// *************************************************************************** *
// *                                                                           *
// * Description:         CANDB File                                           *
// * Generated at:        2025-01-24 12:56                                     *
// * System:              SDB22436                                             *
// * Variant:             L946_ADCU9_ZCUDM                                     *
// * Network:             BodyExposedCAN                                       *
// *                                                                           *
// *************************************************************************** *
VERSION "BodyExposedCAN"

NS_ :

BS_ :

BU_ :  ETC HCML HCMR ZCUD

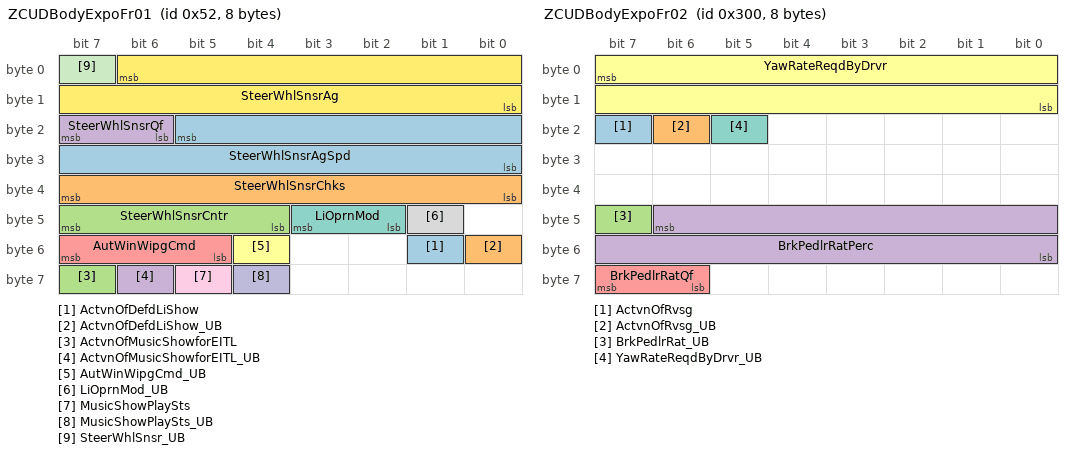
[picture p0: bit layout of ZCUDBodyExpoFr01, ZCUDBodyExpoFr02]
BO_ 82 ZCUDBodyExpoFr01 : 8 ZCUD
 SG_ ActvnOfDefdLiShow : 49|1@0+ (1,0) [0|1] "" HCML,HCMR
 SG_ ActvnOfDefdLiShow_UB : 48|1@0+ (1,0) [0|1] "" HCML,HCMR
 SG_ ActvnOfMusicShowforEITL : 63|1@0+ (1,0) [0|1] "" HCML,HCMR
 SG_ ActvnOfMusicShowforEITL_UB : 62|1@0+ (1,0) [0|1] "" HCML,HCMR
 SG_ AutWinWipgCmd : 55|3@0+ (1,0) [0|7] "" HCML,HCMR
 SG_ AutWinWipgCmd_UB : 52|1@0+ (1,0) [0|1] "" HCML,HCMR
 SG_ LiOprnMod : 43|2@0+ (1,0) [0|3] "" ETC,HCML,HCMR
 SG_ LiOprnMod_UB : 41|1@0+ (1,0) [0|1] "" ETC,HCML,HCMR
 SG_ MusicShowPlaySts : 61|1@0+ (1,0) [0|1] "" HCML,HCMR
 SG_ MusicShowPlaySts_UB : 60|1@0+ (1,0) [0|1] "" HCML,HCMR
 SG_ SteerWhlSnsr_UB : 7|1@0+ (1,0) [0|1] "" HCML,HCMR
 SG_ SteerWhlSnsrAg : 6|15@0- (0.0009765625,0.0) [-14.5|14.5] "rad" HCML,HCMR
 SG_ SteerWhlSnsrAgSpd : 21|14@0- (0.0078125,0.0) [-50.0|50.0] "rad/s" HCML,HCMR
 SG_ SteerWhlSnsrChks : 39|8@0+ (1.0,0.0) [0.0|255.0] "Unitless" HCML,HCMR
 SG_ SteerWhlSnsrCntr : 47|4@0+ (1.0,0.0) [0.0|15.0] "Unitless" HCML,HCMR
 SG_ SteerWhlSnsrQf : 23|2@0+ (1,0) [0|3] "" HCML,HCMR

BO_ 768 ZCUDBodyExpoFr02 : 8 ZCUD
 SG_ ActvnOfRvsg : 23|1@0+ (1,0) [0|1] "" Vector__XXX
 SG_ ActvnOfRvsg_UB : 22|1@0+ (1,0) [0|1] "" Vector__XXX
 SG_ BrkPedlrRat_UB : 47|1@0+ (1,0) [0|1] "" HCML,HCMR
 SG_ BrkPedlrRatPerc : 46|15@0+ (0.00390625,0.0) [0.0|100.0] "%" HCML,HCMR
 SG_ BrkPedlrRatQf : 63|2@0+ (1,0) [0|3] "" HCML,HCMR
 SG_ YawRateReqdByDrvr : 7|16@0- (0.000244140625,0.0) [-5.0|5.0] "rad/s" HCML,HCMR
 SG_ YawRateReqdByDrvr_UB : 21|1@0+ (1,0) [0|1] "" HCML,HCMR

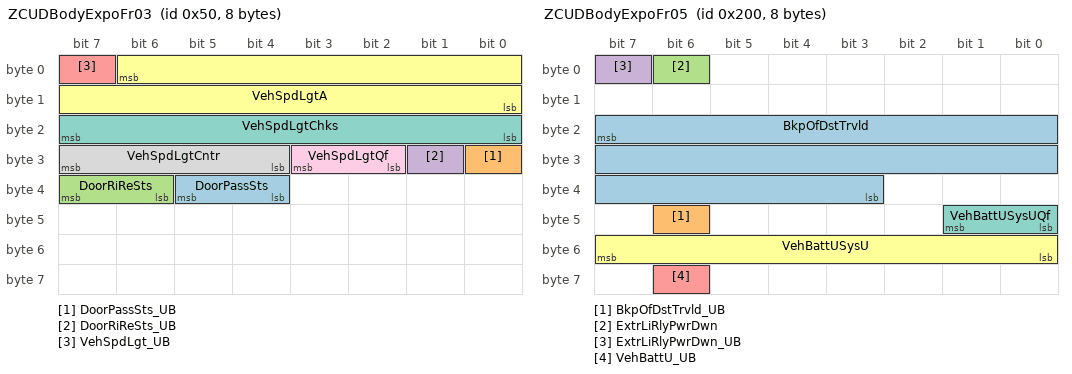
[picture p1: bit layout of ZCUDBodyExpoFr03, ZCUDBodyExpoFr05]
BO_ 80 ZCUDBodyExpoFr03 : 8 ZCUD
 SG_ DoorPassSts : 37|2@0+ (1,0) [0|3] "" Vector__XXX
 SG_ DoorPassSts_UB : 24|1@0+ (1,0) [0|1] "" Vector__XXX
 SG_ DoorRiReSts : 39|2@0+ (1,0) [0|3] "" Vector__XXX
 SG_ DoorRiReSts_UB : 25|1@0+ (1,0) [0|1] "" Vector__XXX
 SG_ VehSpdLgt_UB : 7|1@0+ (1,0) [0|1] "" HCML,HCMR
 SG_ VehSpdLgtA : 6|15@0+ (0.00391,0.0) [0.0|125.0027] "m/s" HCML,HCMR
 SG_ VehSpdLgtChks : 23|8@0+ (1.0,0.0) [0.0|255.0] "Unitless" HCML,HCMR
 SG_ VehSpdLgtCntr : 31|4@0+ (1.0,0.0) [0.0|15.0] "Unitless" HCML,HCMR
 SG_ VehSpdLgtQf : 27|2@0+ (1,0) [0|3] "" HCML,HCMR

BO_ 384 ZCUDBodyExpoFr04 : 8 ZCUD
 SG_ VehCfgPrmBlkIDBytePosn1 : 7|8@0+ (1.0,0.0) [0.0|255.0] "Unitless" HCML,HCMR
 SG_ VehCfgPrmCCPBytePosn2 : 15|8@0+ (1.0,0.0) [0.0|255.0] "Unitless" HCML,HCMR
 SG_ VehCfgPrmCCPBytePosn3 : 23|8@0+ (1.0,0.0) [0.0|255.0] "Unitless" HCML,HCMR
 SG_ VehCfgPrmCCPBytePosn4 : 31|8@0+ (1.0,0.0) [0.0|255.0] "Unitless" HCML,HCMR
 SG_ VehCfgPrmCCPBytePosn5 : 39|8@0+ (1.0,0.0) [0.0|255.0] "Unitless" HCML,HCMR
 SG_ VehCfgPrmCCPBytePosn6 : 47|8@0+ (1.0,0.0) [0.0|255.0] "Unitless" HCML,HCMR
 SG_ VehCfgPrmCCPBytePosn7 : 55|8@0+ (1.0,0.0) [0.0|255.0] "Unitless" HCML,HCMR
 SG_ VehCfgPrmCCPBytePosn8 : 63|8@0+ (1.0,0.0) [0.0|255.0] "Unitless" HCML,HCMR

BO_ 512 ZCUDBodyExpoFr05 : 8 ZCUD
 SG_ BkpOfDstTrvld : 23|21@0+ (1.0,0.0) [0.0|2000000.0] "km" HCML,HCMR
 SG_ BkpOfDstTrvld_UB : 46|1@0+ (1,0) [0|1] "" HCML,HCMR
 SG_ ExtrLiRlyPwrDwn : 6|1@0+ (1,0) [0|1] "" HCML,HCMR
 SG_ ExtrLiRlyPwrDwn_UB : 7|1@0+ (1,0) [0|1] "" HCML,HCMR
 SG_ VehBattU_UB : 62|1@0+ (1,0) [0|1] "" HCML,HCMR
 SG_ VehBattUSysU : 55|8@0+ (0.1,0.0) [0.0|25.0] "Volt" HCML,HCMR
 SG_ VehBattUSysUQf : 41|2@0+ (1,0) [0|3] "" HCML,HCMR

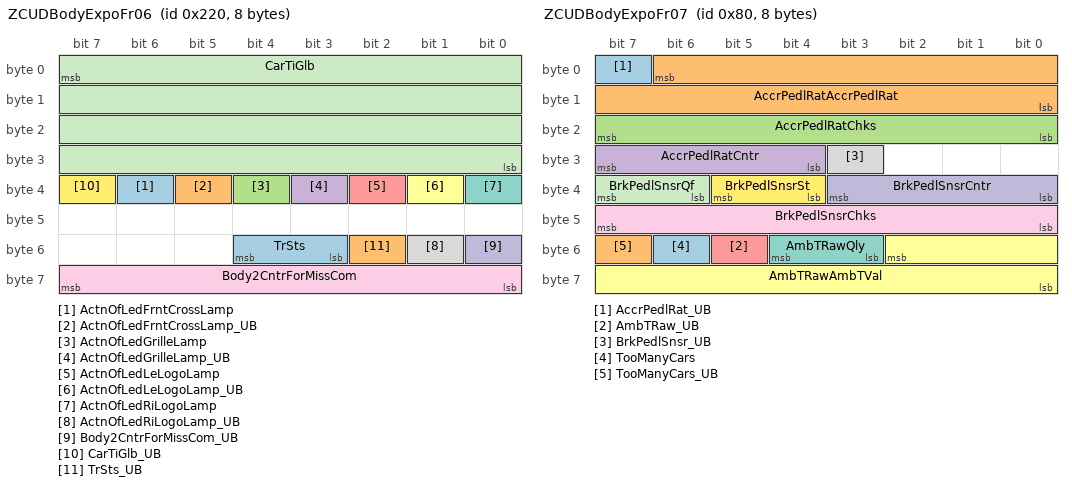
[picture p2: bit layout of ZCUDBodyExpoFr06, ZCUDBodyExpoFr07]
BO_ 544 ZCUDBodyExpoFr06 : 8 ZCUD
 SG_ ActnOfLedFrntCrossLamp : 38|1@0+ (1,0) [0|1] "" HCML,HCMR
 SG_ ActnOfLedFrntCrossLamp_UB : 37|1@0+ (1,0) [0|1] "" HCML,HCMR
 SG_ ActnOfLedGrilleLamp : 36|1@0+ (1,0) [0|1] "" HCML,HCMR
 SG_ ActnOfLedGrilleLamp_UB : 35|1@0+ (1,0) [0|1] "" HCML,HCMR
 SG_ ActnOfLedLeLogoLamp : 34|1@0+ (1,0) [0|1] "" HCML
 SG_ ActnOfLedLeLogoLamp_UB : 33|1@0+ (1,0) [0|1] "" HCML
 SG_ ActnOfLedRiLogoLamp : 32|1@0+ (1,0) [0|1] "" HCMR
 SG_ ActnOfLedRiLogoLamp_UB : 49|1@0+ (1,0) [0|1] "" HCMR
 SG_ Body2CntrForMissCom : 63|8@0+ (1.0,0.0) [0.0|255.0] "Unitless" HCML,HCMR
 SG_ Body2CntrForMissCom_UB : 48|1@0+ (1,0) [0|1] "" HCML,HCMR
 SG_ CarTiGlb : 7|32@0+ (0.1,0.0) [0.0|429496729.5] "s" HCML,HCMR
 SG_ CarTiGlb_UB : 39|1@0+ (1,0) [0|1] "" HCML,HCMR
 SG_ TrSts : 52|2@0+ (1,0) [0|3] "" Vector__XXX
 SG_ TrSts_UB : 50|1@0+ (1,0) [0|1] "" Vector__XXX

BO_ 128 ZCUDBodyExpoFr07 : 8 ZCUD
 SG_ AccrPedlRat_UB : 7|1@0+ (1,0) [0|1] "" HCML,HCMR
 SG_ AccrPedlRatAccrPedlRat : 6|15@0+ (0.00390625,0.0) [0.0|100.0] "%" HCML,HCMR
 SG_ AccrPedlRatChks : 23|8@0+ (1.0,0.0) [0.0|255.0] "Unitless" HCML,HCMR
 SG_ AccrPedlRatCntr : 31|4@0+ (1.0,0.0) [0.0|15.0] "Unitless" HCML,HCMR
 SG_ AmbTRaw_UB : 53|1@0+ (1,0) [0|1] "" HCML,HCMR
 SG_ AmbTRawAmbTVal : 50|11@0+ (0.1,-70.0) [-70.0|134.70000000000002] "degC" HCML,HCMR
 SG_ AmbTRawQly : 52|2@0+ (1,0) [0|3] "" HCML,HCMR
 SG_ BrkPedlSnsr_UB : 27|1@0+ (1,0) [0|1] "" HCML,HCMR
 SG_ BrkPedlSnsrChks : 47|8@0+ (1.0,0.0) [0.0|255.0] "Unitless" HCML,HCMR
 SG_ BrkPedlSnsrCntr : 35|4@0+ (1.0,0.0) [0.0|15.0] "Unitless" HCML,HCMR
 SG_ BrkPedlSnsrQf : 39|2@0+ (1,0) [0|3] "" HCML,HCMR
 SG_ BrkPedlSnsrSt : 37|2@0+ (1,0) [0|3] "" HCML,HCMR
 SG_ TooManyCars : 54|1@0+ (1,0) [0|1] "" HCML,HCMR
 SG_ TooManyCars_UB : 55|1@0+ (1,0) [0|1] "" HCML,HCMR

BO_ 387 ZCUDBodyExpoFr08 : 8 ZCUD
 SG_ VehCfgPrmExtBlkIDBytePosn1 : 7|8@0+ (1.0,0.0) [0.0|255.0] "Unitless" HCML,HCMR
 SG_ VehCfgPrmExtCCPBytePosn2 : 15|8@0+ (1.0,0.0) [0.0|255.0] "Unitless" HCML,HCMR
 SG_ VehCfgPrmExtCCPBytePosn3 : 23|8@0+ (1.0,0.0) [0.0|255.0] "Unitless" HCML,HCMR
 SG_ VehCfgPrmExtCCPBytePosn4 : 31|8@0+ (1.0,0.0) [0.0|255.0] "Unitless" HCML,HCMR
 SG_ VehCfgPrmExtCCPBytePosn5 : 39|8@0+ (1.0,0.0) [0.0|255.0] "Unitless" HCML,HCMR
 SG_ VehCfgPrmExtCCPBytePosn6 : 47|8@0+ (1.0,0.0) [0.0|255.0] "Unitless" HCML,HCMR
 SG_ VehCfgPrmExtCCPBytePosn7 : 55|8@0+ (1.0,0.0) [0.0|255.0] "Unitless" HCML,HCMR
 SG_ VehCfgPrmExtCCPBytePosn8 : 63|8@0+ (1.0,0.0) [0.0|255.0] "Unitless" HCML,HCMR

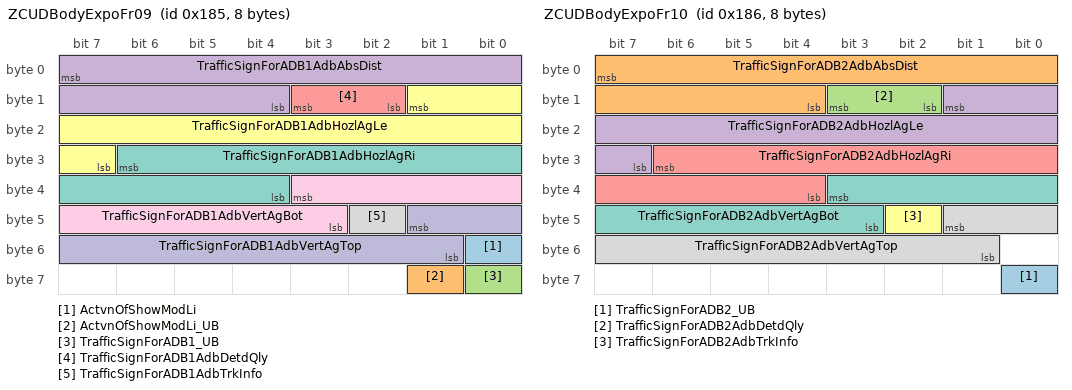
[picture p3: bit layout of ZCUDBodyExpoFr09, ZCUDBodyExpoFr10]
BO_ 389 ZCUDBodyExpoFr09 : 8 ZCUD
 SG_ ActvnOfShowModLi : 48|1@0+ (1,0) [0|1] "" HCML,HCMR
 SG_ ActvnOfShowModLi_UB : 57|1@0+ (1,0) [0|1] "" HCML,HCMR
 SG_ TrafficSignForADB1_UB : 56|1@0+ (1,0) [0|1] "" HCML,HCMR
 SG_ TrafficSignForADB1AdbAbsDist : 7|12@0+ (0.2,0.0) [0.0|819.0] "m" HCML,HCMR
 SG_ TrafficSignForADB1AdbDetdQly : 11|2@0+ (1,0) [0|3] "" HCML,HCMR
 SG_ TrafficSignForADB1AdbHozlAgLe : 9|11@0+ (0.05,-40.0) [-40.0|40.0] "Deg" HCML,HCMR
 SG_ TrafficSignForADB1AdbHozlAgRi : 30|11@0+ (0.05,-40.0) [-40.0|40.0] "Deg" HCML,HCMR
 SG_ TrafficSignForADB1AdbTrkInfo : 42|1@0+ (1,0) [0|1] "" HCML,HCMR
 SG_ TrafficSignForADB1AdbVertAgBot : 35|9@0+ (0.05,-3.0) [-3.0|22.55] "Deg" HCML,HCMR
 SG_ TrafficSignForADB1AdbVertAgTop : 41|9@0+ (0.05,-3.0) [-3.0|22.55] "Deg" HCML,HCMR

BO_ 390 ZCUDBodyExpoFr10 : 8 ZCUD
 SG_ TrafficSignForADB2_UB : 56|1@0+ (1,0) [0|1] "" HCML,HCMR
 SG_ TrafficSignForADB2AdbAbsDist : 7|12@0+ (0.2,0.0) [0.0|819.0] "m" HCML,HCMR
 SG_ TrafficSignForADB2AdbDetdQly : 11|2@0+ (1,0) [0|3] "" HCML,HCMR
 SG_ TrafficSignForADB2AdbHozlAgLe : 9|11@0+ (0.05,-40.0) [-40.0|40.0] "Deg" HCML,HCMR
 SG_ TrafficSignForADB2AdbHozlAgRi : 30|11@0+ (0.05,-40.0) [-40.0|40.0] "Deg" HCML,HCMR
 SG_ TrafficSignForADB2AdbTrkInfo : 42|1@0+ (1,0) [0|1] "" HCML,HCMR
 SG_ TrafficSignForADB2AdbVertAgBot : 35|9@0+ (0.05,-3.0) [-3.0|22.55] "Deg" HCML,HCMR
 SG_ TrafficSignForADB2AdbVertAgTop : 41|9@0+ (0.05,-3.0) [-3.0|22.55] "Deg" HCML,HCMR

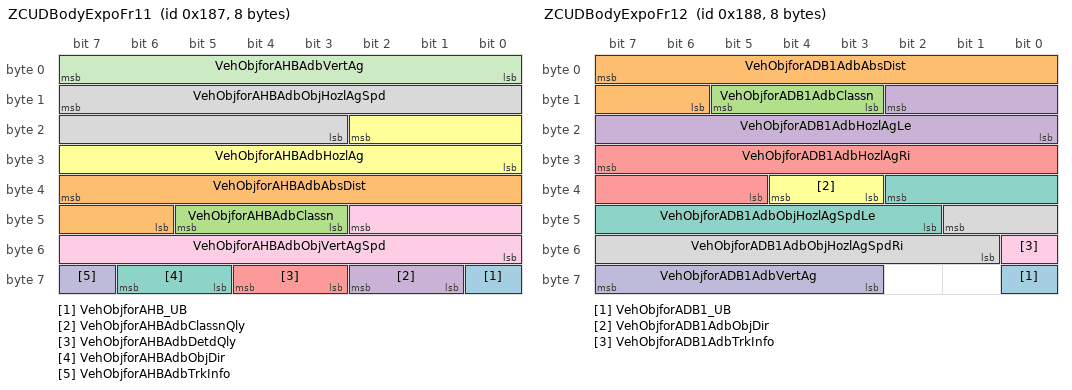
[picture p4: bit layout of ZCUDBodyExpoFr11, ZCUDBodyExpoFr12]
BO_ 391 ZCUDBodyExpoFr11 : 8 ZCUD
 SG_ VehObjforAHB_UB : 56|1@0+ (1,0) [0|1] "" HCML,HCMR
 SG_ VehObjforAHBAdbAbsDist : 39|10@0+ (1.0,0.0) [0.0|1000.0] "m" HCML,HCMR
 SG_ VehObjforAHBAdbClassn : 45|3@0+ (1,0) [0|7] "" HCML,HCMR
 SG_ VehObjforAHBAdbClassnQly : 58|2@0+ (1,0) [0|3] "" HCML,HCMR
 SG_ VehObjforAHBAdbDetdQly : 60|2@0+ (1,0) [0|3] "" HCML,HCMR
 SG_ VehObjforAHBAdbHozlAg : 18|11@0+ (0.05,-40.0) [-40.0|40.0] "Deg" HCML,HCMR
 SG_ VehObjforAHBAdbObjDir : 62|2@0+ (1,0) [0|3] "" HCML,HCMR
 SG_ VehObjforAHBAdbObjHozlAgSpd : 15|13@0+ (0.05,-144.0) [-144.0|144.0] "DegPerSec" HCML,HCMR
 SG_ VehObjforAHBAdbObjVertAgSpd : 42|11@0+ (0.2,-144.0) [-144.0|144.0] "DegPerSec" HCML,HCMR
 SG_ VehObjforAHBAdbTrkInfo : 63|1@0+ (1,0) [0|1] "" HCML,HCMR
 SG_ VehObjforAHBAdbVertAg : 7|8@0+ (0.2,-15.0) [-15.0|15.0] "Deg" HCML,HCMR

BO_ 392 ZCUDBodyExpoFr12 : 8 ZCUD
 SG_ VehObjforADB1_UB : 56|1@0+ (1,0) [0|1] "" HCML,HCMR
 SG_ VehObjforADB1AdbAbsDist : 7|10@0+ (1.0,0.0) [0.0|1000.0] "m" HCML,HCMR
 SG_ VehObjforADB1AdbClassn : 13|3@0+ (1,0) [0|7] "" HCML,HCMR
 SG_ VehObjforADB1AdbHozlAgLe : 10|11@0+ (0.05,-40.0) [-40.0|40.0] "Deg" HCML,HCMR
 SG_ VehObjforADB1AdbHozlAgRi : 31|11@0+ (0.05,-40.0) [-40.0|40.0] "Deg" HCML,HCMR
 SG_ VehObjforADB1AdbObjDir : 36|2@0+ (1,0) [0|3] "" HCML,HCMR
 SG_ VehObjforADB1AdbObjHozlAgSpdLe : 34|9@0+ (0.2,-50.0) [-50.0|52.2] "DegPerSec" HCML,HCMR
 SG_ VehObjforADB1AdbObjHozlAgSpdRi : 41|9@0+ (0.2,-50.0) [-50.0|52.2] "DegPerSec" HCML,HCMR
 SG_ VehObjforADB1AdbTrkInfo : 48|1@0+ (1,0) [0|1] "" HCML,HCMR
 SG_ VehObjforADB1AdbVertAg : 63|5@0+ (0.5,-3.0) [-3.0|12.5] "Deg" HCML,HCMR

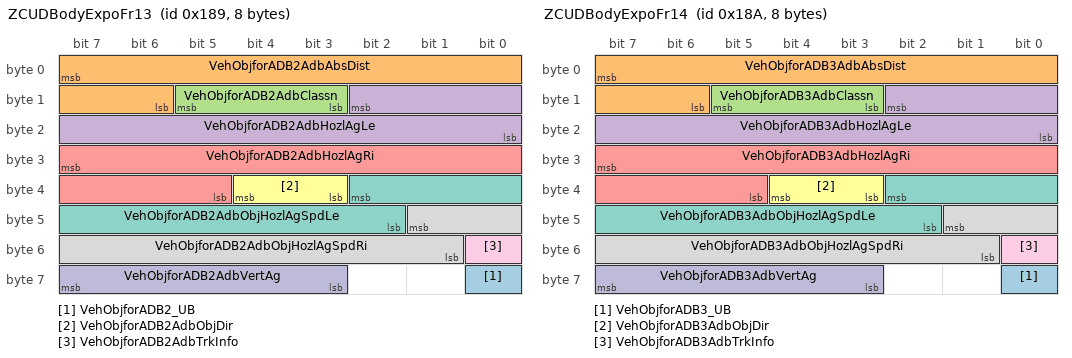
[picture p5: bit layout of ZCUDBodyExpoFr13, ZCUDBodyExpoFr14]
BO_ 393 ZCUDBodyExpoFr13 : 8 ZCUD
 SG_ VehObjforADB2_UB : 56|1@0+ (1,0) [0|1] "" HCML,HCMR
 SG_ VehObjforADB2AdbAbsDist : 7|10@0+ (1.0,0.0) [0.0|1000.0] "m" HCML,HCMR
 SG_ VehObjforADB2AdbClassn : 13|3@0+ (1,0) [0|7] "" HCML,HCMR
 SG_ VehObjforADB2AdbHozlAgLe : 10|11@0+ (0.05,-40.0) [-40.0|40.0] "Deg" HCML,HCMR
 SG_ VehObjforADB2AdbHozlAgRi : 31|11@0+ (0.05,-40.0) [-40.0|40.0] "Deg" HCML,HCMR
 SG_ VehObjforADB2AdbObjDir : 36|2@0+ (1,0) [0|3] "" HCML,HCMR
 SG_ VehObjforADB2AdbObjHozlAgSpdLe : 34|9@0+ (0.2,-50.0) [-50.0|52.2] "DegPerSec" HCML,HCMR
 SG_ VehObjforADB2AdbObjHozlAgSpdRi : 41|9@0+ (0.2,-50.0) [-50.0|52.2] "DegPerSec" HCML,HCMR
 SG_ VehObjforADB2AdbTrkInfo : 48|1@0+ (1,0) [0|1] "" HCML,HCMR
 SG_ VehObjforADB2AdbVertAg : 63|5@0+ (0.5,-3.0) [-3.0|12.5] "Deg" HCML,HCMR

BO_ 394 ZCUDBodyExpoFr14 : 8 ZCUD
 SG_ VehObjforADB3_UB : 56|1@0+ (1,0) [0|1] "" HCML,HCMR
 SG_ VehObjforADB3AdbAbsDist : 7|10@0+ (1.0,0.0) [0.0|1000.0] "m" HCML,HCMR
 SG_ VehObjforADB3AdbClassn : 13|3@0+ (1,0) [0|7] "" HCML,HCMR
 SG_ VehObjforADB3AdbHozlAgLe : 10|11@0+ (0.05,-40.0) [-40.0|40.0] "Deg" HCML,HCMR
 SG_ VehObjforADB3AdbHozlAgRi : 31|11@0+ (0.05,-40.0) [-40.0|40.0] "Deg" HCML,HCMR
 SG_ VehObjforADB3AdbObjDir : 36|2@0+ (1,0) [0|3] "" HCML,HCMR
 SG_ VehObjforADB3AdbObjHozlAgSpdLe : 34|9@0+ (0.2,-50.0) [-50.0|52.2] "DegPerSec" HCML,HCMR
 SG_ VehObjforADB3AdbObjHozlAgSpdRi : 41|9@0+ (0.2,-50.0) [-50.0|52.2] "DegPerSec" HCML,HCMR
 SG_ VehObjforADB3AdbTrkInfo : 48|1@0+ (1,0) [0|1] "" HCML,HCMR
 SG_ VehObjforADB3AdbVertAg : 63|5@0+ (0.5,-3.0) [-3.0|12.5] "Deg" HCML,HCMR

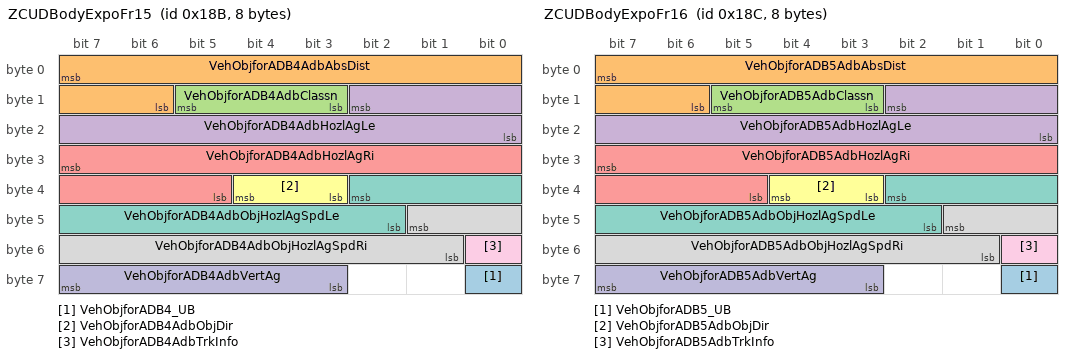
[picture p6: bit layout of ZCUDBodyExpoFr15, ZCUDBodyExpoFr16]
BO_ 395 ZCUDBodyExpoFr15 : 8 ZCUD
 SG_ VehObjforADB4_UB : 56|1@0+ (1,0) [0|1] "" HCML,HCMR
 SG_ VehObjforADB4AdbAbsDist : 7|10@0+ (1.0,0.0) [0.0|1000.0] "m" HCML,HCMR
 SG_ VehObjforADB4AdbClassn : 13|3@0+ (1,0) [0|7] "" HCML,HCMR
 SG_ VehObjforADB4AdbHozlAgLe : 10|11@0+ (0.05,-40.0) [-40.0|40.0] "Deg" HCML,HCMR
 SG_ VehObjforADB4AdbHozlAgRi : 31|11@0+ (0.05,-40.0) [-40.0|40.0] "Deg" HCML,HCMR
 SG_ VehObjforADB4AdbObjDir : 36|2@0+ (1,0) [0|3] "" HCML,HCMR
 SG_ VehObjforADB4AdbObjHozlAgSpdLe : 34|9@0+ (0.2,-50.0) [-50.0|52.2] "DegPerSec" HCML,HCMR
 SG_ VehObjforADB4AdbObjHozlAgSpdRi : 41|9@0+ (0.2,-50.0) [-50.0|52.2] "DegPerSec" HCML,HCMR
 SG_ VehObjforADB4AdbTrkInfo : 48|1@0+ (1,0) [0|1] "" HCML,HCMR
 SG_ VehObjforADB4AdbVertAg : 63|5@0+ (0.5,-3.0) [-3.0|12.5] "Deg" HCML,HCMR

BO_ 396 ZCUDBodyExpoFr16 : 8 ZCUD
 SG_ VehObjforADB5_UB : 56|1@0+ (1,0) [0|1] "" HCML,HCMR
 SG_ VehObjforADB5AdbAbsDist : 7|10@0+ (1.0,0.0) [0.0|1000.0] "m" HCML,HCMR
 SG_ VehObjforADB5AdbClassn : 13|3@0+ (1,0) [0|7] "" HCML,HCMR
 SG_ VehObjforADB5AdbHozlAgLe : 10|11@0+ (0.05,-40.0) [-40.0|40.0] "Deg" HCML,HCMR
 SG_ VehObjforADB5AdbHozlAgRi : 31|11@0+ (0.05,-40.0) [-40.0|40.0] "Deg" HCML,HCMR
 SG_ VehObjforADB5AdbObjDir : 36|2@0+ (1,0) [0|3] "" HCML,HCMR
 SG_ VehObjforADB5AdbObjHozlAgSpdLe : 34|9@0+ (0.2,-50.0) [-50.0|52.2] "DegPerSec" HCML,HCMR
 SG_ VehObjforADB5AdbObjHozlAgSpdRi : 41|9@0+ (0.2,-50.0) [-50.0|52.2] "DegPerSec" HCML,HCMR
 SG_ VehObjforADB5AdbTrkInfo : 48|1@0+ (1,0) [0|1] "" HCML,HCMR
 SG_ VehObjforADB5AdbVertAg : 63|5@0+ (0.5,-3.0) [-3.0|12.5] "Deg" HCML,HCMR

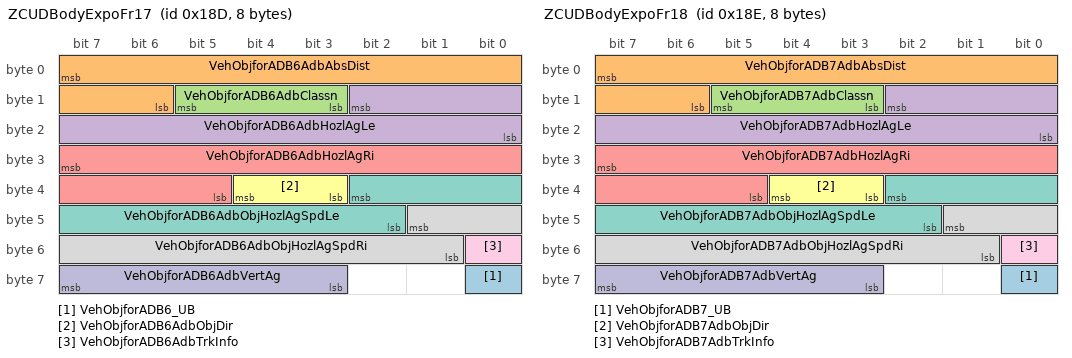
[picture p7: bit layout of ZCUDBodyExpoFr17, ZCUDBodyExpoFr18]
BO_ 397 ZCUDBodyExpoFr17 : 8 ZCUD
 SG_ VehObjforADB6_UB : 56|1@0+ (1,0) [0|1] "" HCML,HCMR
 SG_ VehObjforADB6AdbAbsDist : 7|10@0+ (1.0,0.0) [0.0|1000.0] "m" HCML,HCMR
 SG_ VehObjforADB6AdbClassn : 13|3@0+ (1,0) [0|7] "" HCML,HCMR
 SG_ VehObjforADB6AdbHozlAgLe : 10|11@0+ (0.05,-40.0) [-40.0|40.0] "Deg" HCML,HCMR
 SG_ VehObjforADB6AdbHozlAgRi : 31|11@0+ (0.05,-40.0) [-40.0|40.0] "Deg" HCML,HCMR
 SG_ VehObjforADB6AdbObjDir : 36|2@0+ (1,0) [0|3] "" HCML,HCMR
 SG_ VehObjforADB6AdbObjHozlAgSpdLe : 34|9@0+ (0.2,-50.0) [-50.0|52.2] "DegPerSec" HCML,HCMR
 SG_ VehObjforADB6AdbObjHozlAgSpdRi : 41|9@0+ (0.2,-50.0) [-50.0|52.2] "DegPerSec" HCML,HCMR
 SG_ VehObjforADB6AdbTrkInfo : 48|1@0+ (1,0) [0|1] "" HCML,HCMR
 SG_ VehObjforADB6AdbVertAg : 63|5@0+ (0.5,-3.0) [-3.0|12.5] "Deg" HCML,HCMR

BO_ 398 ZCUDBodyExpoFr18 : 8 ZCUD
 SG_ VehObjforADB7_UB : 56|1@0+ (1,0) [0|1] "" HCML,HCMR
 SG_ VehObjforADB7AdbAbsDist : 7|10@0+ (1.0,0.0) [0.0|1000.0] "m" HCML,HCMR
 SG_ VehObjforADB7AdbClassn : 13|3@0+ (1,0) [0|7] "" HCML,HCMR
 SG_ VehObjforADB7AdbHozlAgLe : 10|11@0+ (0.05,-40.0) [-40.0|40.0] "Deg" HCML,HCMR
 SG_ VehObjforADB7AdbHozlAgRi : 31|11@0+ (0.05,-40.0) [-40.0|40.0] "Deg" HCML,HCMR
 SG_ VehObjforADB7AdbObjDir : 36|2@0+ (1,0) [0|3] "" HCML,HCMR
 SG_ VehObjforADB7AdbObjHozlAgSpdLe : 34|9@0+ (0.2,-50.0) [-50.0|52.2] "DegPerSec" HCML,HCMR
 SG_ VehObjforADB7AdbObjHozlAgSpdRi : 41|9@0+ (0.2,-50.0) [-50.0|52.2] "DegPerSec" HCML,HCMR
 SG_ VehObjforADB7AdbTrkInfo : 48|1@0+ (1,0) [0|1] "" HCML,HCMR
 SG_ VehObjforADB7AdbVertAg : 63|5@0+ (0.5,-3.0) [-3.0|12.5] "Deg" HCML,HCMR

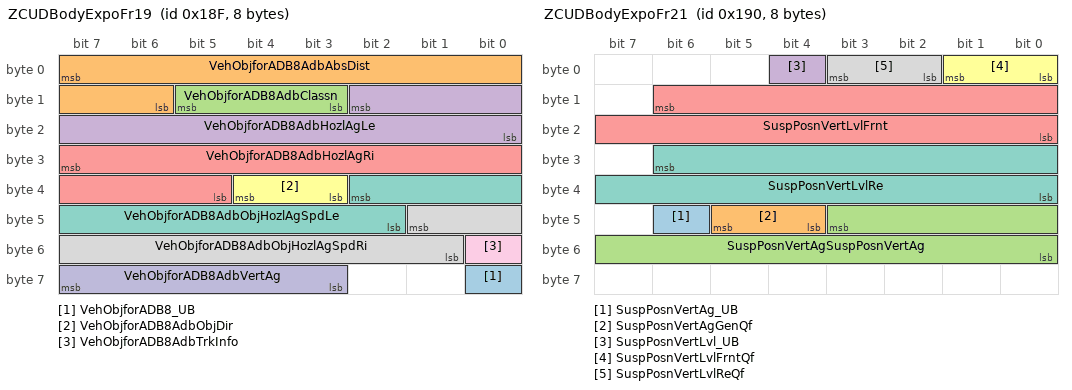
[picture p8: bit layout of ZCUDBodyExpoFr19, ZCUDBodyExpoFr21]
BO_ 399 ZCUDBodyExpoFr19 : 8 ZCUD
 SG_ VehObjforADB8_UB : 56|1@0+ (1,0) [0|1] "" HCML,HCMR
 SG_ VehObjforADB8AdbAbsDist : 7|10@0+ (1.0,0.0) [0.0|1000.0] "m" HCML,HCMR
 SG_ VehObjforADB8AdbClassn : 13|3@0+ (1,0) [0|7] "" HCML,HCMR
 SG_ VehObjforADB8AdbHozlAgLe : 10|11@0+ (0.05,-40.0) [-40.0|40.0] "Deg" HCML,HCMR
 SG_ VehObjforADB8AdbHozlAgRi : 31|11@0+ (0.05,-40.0) [-40.0|40.0] "Deg" HCML,HCMR
 SG_ VehObjforADB8AdbObjDir : 36|2@0+ (1,0) [0|3] "" HCML,HCMR
 SG_ VehObjforADB8AdbObjHozlAgSpdLe : 34|9@0+ (0.2,-50.0) [-50.0|52.2] "DegPerSec" HCML,HCMR
 SG_ VehObjforADB8AdbObjHozlAgSpdRi : 41|9@0+ (0.2,-50.0) [-50.0|52.2] "DegPerSec" HCML,HCMR
 SG_ VehObjforADB8AdbTrkInfo : 48|1@0+ (1,0) [0|1] "" HCML,HCMR
 SG_ VehObjforADB8AdbVertAg : 63|5@0+ (0.5,-3.0) [-3.0|12.5] "Deg" HCML,HCMR

BO_ 64 ZCUDBodyExpoFr20 : 8 ZCUD
 SG_ ActnOfAssistantLi : 46|1@0+ (1,0) [0|1] "" HCML,HCMR
 SG_ ActnOfAssistantLi_UB : 56|1@0+ (1,0) [0|1] "" HCML,HCMR
 SG_ CameraStsforAHBC : 62|2@0+ (1,0) [0|3] "" HCML,HCMR
 SG_ CameraStsforAHBC_UB : 60|1@0+ (1,0) [0|1] "" HCML,HCMR
 SG_ RainLi : 47|1@0+ (1,0) [0|1] "" ETC,HCML,HCMR
 SG_ RainLi_UB : 63|1@0+ (1,0) [0|1] "" ETC,HCML,HCMR
 SG_ VehModMngtGlbSafe1_UB : 32|1@0+ (1,0) [0|1] "" HCML,HCMR
 SG_ VehModMngtGlbSafe1CarModSts1 : 39|3@0+ (1,0) [0|7] "" HCML,HCMR
 SG_ VehModMngtGlbSafe1CarModSubtypWdCarModSubtyp : 35|3@0+ (1.0,0.0) [0.0|7.0] "Unitless" HCML,HCMR
 SG_ VehModMngtGlbSafe1Chks : 7|8@0+ (1.0,0.0) [0.0|255.0] "Unitless" HCML,HCMR
 SG_ VehModMngtGlbSafe1Cntr : 15|4@0+ (1.0,0.0) [0.0|15.0] "Unitless" HCML,HCMR
 SG_ VehModMngtGlbSafe1EgyLvlElecMai : 27|4@0+ (1.0,0.0) [0.0|15.0] "Unitless" HCML,HCMR
 SG_ VehModMngtGlbSafe1EgyLvlElecSubtyp : 31|4@0+ (1.0,0.0) [0.0|15.0] "Unitless" HCML,HCMR
 SG_ VehModMngtGlbSafe1FltEgyCnsWdSts : 36|1@0+ (1,0) [0|1] "" HCML,HCMR
 SG_ VehModMngtGlbSafe1PwrLvlElecMai : 19|4@0+ (1.0,0.0) [0.0|15.0] "Unitless" HCML,HCMR
 SG_ VehModMngtGlbSafe1PwrLvlElecSubtyp : 23|4@0+ (1.0,0.0) [0.0|15.0] "Unitless" HCML,HCMR
 SG_ VehModMngtGlbSafe1UsgModSts : 11|4@0+ (1,0) [0|15] "" HCML,HCMR
 SG_ WipgAutFrntMod : 59|2@0+ (1,0) [0|3] "" HCML,HCMR
 SG_ WipgAutFrntMod_UB : 57|1@0+ (1,0) [0|1] "" HCML,HCMR

BO_ 400 ZCUDBodyExpoFr21 : 8 ZCUD
 SG_ SuspPosnVertAg_UB : 46|1@0+ (1,0) [0|1] "" HCML,HCMR
 SG_ SuspPosnVertAgGenQf : 45|2@0+ (1,0) [0|3] "" HCML,HCMR
 SG_ SuspPosnVertAgSuspPosnVertAg : 43|12@0- (0.000127894181,0.0) [-0.26167149432599995|0.26179938850699996] "rad" HCML,HCMR
 SG_ SuspPosnVertLvl_UB : 4|1@0+ (1,0) [0|1] "" HCML,HCMR
 SG_ SuspPosnVertLvlFrnt : 14|15@0- (0.000062,0.0) [-0.999998|1.00006] "m" HCML,HCMR
 SG_ SuspPosnVertLvlFrntQf : 1|2@0+ (1,0) [0|3] "" HCML,HCMR
 SG_ SuspPosnVertLvlRe : 30|15@0- (0.000062,0.0) [-0.999998|1.00006] "m" HCML,HCMR
 SG_ SuspPosnVertLvlReQf : 3|2@0+ (1,0) [0|3] "" HCML,HCMR

BO_ 28 ZCUDBodyExpoFr22 : 8 ZCUD
 SG_ ExtrLiShowActvnReq : 44|1@0+ (1,0) [0|1] "" HCML,HCMR
 SG_ ExtrLiShowActvnReq_UB : 43|1@0+ (1,0) [0|1] "" HCML,HCMR
 SG_ ExtrLiShowFileTxReq : 42|1@0+ (1,0) [0|1] "" HCML,HCMR
 SG_ ExtrLiShowFileTxReq_UB : 41|1@0+ (1,0) [0|1] "" HCML,HCMR

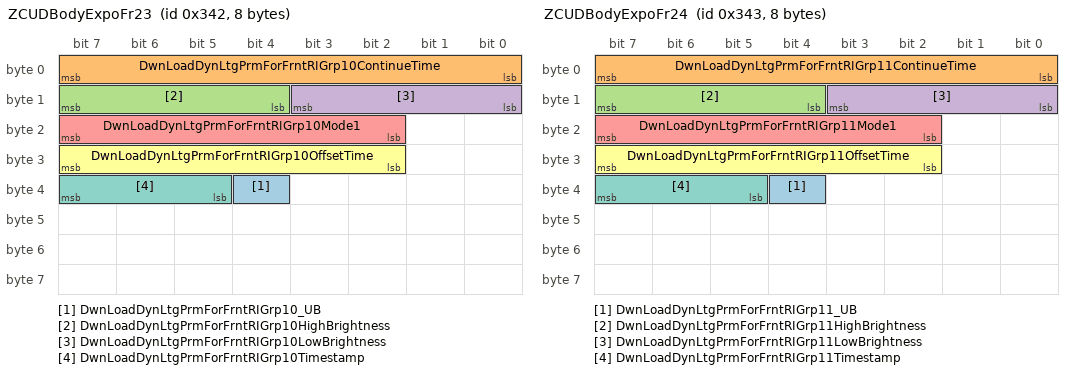
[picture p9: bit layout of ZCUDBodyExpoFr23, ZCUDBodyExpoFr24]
BO_ 834 ZCUDBodyExpoFr23 : 8 ZCUD
 SG_ DwnLoadDynLtgPrmForFrntRIGrp10_UB : 36|1@0+ (1,0) [0|1] "" HCMR
 SG_ DwnLoadDynLtgPrmForFrntRIGrp10ContinueTime : 7|8@0+ (1.0,0.0) [0.0|255.0] "Unitless" HCMR
 SG_ DwnLoadDynLtgPrmForFrntRIGrp10HighBrightness : 15|4@0+ (1.0,0.0) [0.0|10.0] "Unitless" HCMR
 SG_ DwnLoadDynLtgPrmForFrntRIGrp10LowBrightness : 11|4@0+ (1.0,0.0) [0.0|10.0] "Unitless" HCMR
 SG_ DwnLoadDynLtgPrmForFrntRIGrp10Mode1 : 23|6@0+ (1,0) [0|63] "" HCMR
 SG_ DwnLoadDynLtgPrmForFrntRIGrp10OffsetTime : 31|6@0+ (1.0,0.0) [0.0|63.0] "Unitless" HCMR
 SG_ DwnLoadDynLtgPrmForFrntRIGrp10Timestamp : 39|3@0+ (1.0,0.0) [0.0|7.0] "Unitless" HCMR

BO_ 835 ZCUDBodyExpoFr24 : 8 ZCUD
 SG_ DwnLoadDynLtgPrmForFrntRIGrp11_UB : 36|1@0+ (1,0) [0|1] "" HCMR
 SG_ DwnLoadDynLtgPrmForFrntRIGrp11ContinueTime : 7|8@0+ (1.0,0.0) [0.0|255.0] "Unitless" HCMR
 SG_ DwnLoadDynLtgPrmForFrntRIGrp11HighBrightness : 15|4@0+ (1.0,0.0) [0.0|10.0] "Unitless" HCMR
 SG_ DwnLoadDynLtgPrmForFrntRIGrp11LowBrightness : 11|4@0+ (1.0,0.0) [0.0|10.0] "Unitless" HCMR
 SG_ DwnLoadDynLtgPrmForFrntRIGrp11Mode1 : 23|6@0+ (1,0) [0|63] "" HCMR
 SG_ DwnLoadDynLtgPrmForFrntRIGrp11OffsetTime : 31|6@0+ (1.0,0.0) [0.0|63.0] "Unitless" HCMR
 SG_ DwnLoadDynLtgPrmForFrntRIGrp11Timestamp : 39|3@0+ (1.0,0.0) [0.0|7.0] "Unitless" HCMR

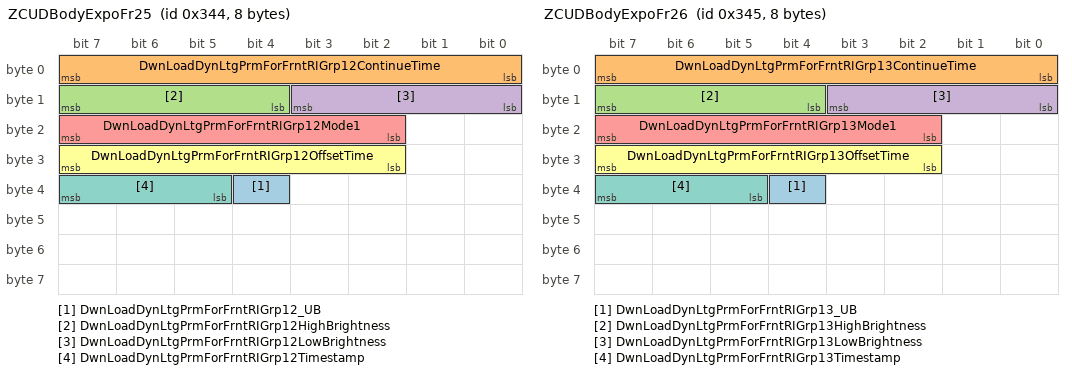
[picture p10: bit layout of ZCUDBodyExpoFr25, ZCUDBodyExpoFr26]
BO_ 836 ZCUDBodyExpoFr25 : 8 ZCUD
 SG_ DwnLoadDynLtgPrmForFrntRIGrp12_UB : 36|1@0+ (1,0) [0|1] "" HCMR
 SG_ DwnLoadDynLtgPrmForFrntRIGrp12ContinueTime : 7|8@0+ (1.0,0.0) [0.0|255.0] "Unitless" HCMR
 SG_ DwnLoadDynLtgPrmForFrntRIGrp12HighBrightness : 15|4@0+ (1.0,0.0) [0.0|10.0] "Unitless" HCMR
 SG_ DwnLoadDynLtgPrmForFrntRIGrp12LowBrightness : 11|4@0+ (1.0,0.0) [0.0|10.0] "Unitless" HCMR
 SG_ DwnLoadDynLtgPrmForFrntRIGrp12Mode1 : 23|6@0+ (1,0) [0|63] "" HCMR
 SG_ DwnLoadDynLtgPrmForFrntRIGrp12OffsetTime : 31|6@0+ (1.0,0.0) [0.0|63.0] "Unitless" HCMR
 SG_ DwnLoadDynLtgPrmForFrntRIGrp12Timestamp : 39|3@0+ (1.0,0.0) [0.0|7.0] "Unitless" HCMR

BO_ 837 ZCUDBodyExpoFr26 : 8 ZCUD
 SG_ DwnLoadDynLtgPrmForFrntRIGrp13_UB : 36|1@0+ (1,0) [0|1] "" HCMR
 SG_ DwnLoadDynLtgPrmForFrntRIGrp13ContinueTime : 7|8@0+ (1.0,0.0) [0.0|255.0] "Unitless" HCMR
 SG_ DwnLoadDynLtgPrmForFrntRIGrp13HighBrightness : 15|4@0+ (1.0,0.0) [0.0|10.0] "Unitless" HCMR
 SG_ DwnLoadDynLtgPrmForFrntRIGrp13LowBrightness : 11|4@0+ (1.0,0.0) [0.0|10.0] "Unitless" HCMR
 SG_ DwnLoadDynLtgPrmForFrntRIGrp13Mode1 : 23|6@0+ (1,0) [0|63] "" HCMR
 SG_ DwnLoadDynLtgPrmForFrntRIGrp13OffsetTime : 31|6@0+ (1.0,0.0) [0.0|63.0] "Unitless" HCMR
 SG_ DwnLoadDynLtgPrmForFrntRIGrp13Timestamp : 39|3@0+ (1.0,0.0) [0.0|7.0] "Unitless" HCMR

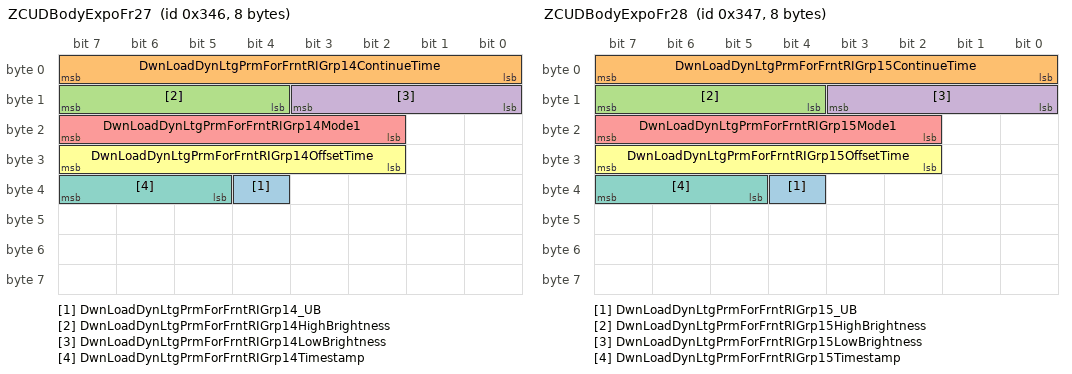
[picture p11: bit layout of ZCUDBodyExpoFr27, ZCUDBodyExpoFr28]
BO_ 838 ZCUDBodyExpoFr27 : 8 ZCUD
 SG_ DwnLoadDynLtgPrmForFrntRIGrp14_UB : 36|1@0+ (1,0) [0|1] "" HCMR
 SG_ DwnLoadDynLtgPrmForFrntRIGrp14ContinueTime : 7|8@0+ (1.0,0.0) [0.0|255.0] "Unitless" HCMR
 SG_ DwnLoadDynLtgPrmForFrntRIGrp14HighBrightness : 15|4@0+ (1.0,0.0) [0.0|10.0] "Unitless" HCMR
 SG_ DwnLoadDynLtgPrmForFrntRIGrp14LowBrightness : 11|4@0+ (1.0,0.0) [0.0|10.0] "Unitless" HCMR
 SG_ DwnLoadDynLtgPrmForFrntRIGrp14Mode1 : 23|6@0+ (1,0) [0|63] "" HCMR
 SG_ DwnLoadDynLtgPrmForFrntRIGrp14OffsetTime : 31|6@0+ (1.0,0.0) [0.0|63.0] "Unitless" HCMR
 SG_ DwnLoadDynLtgPrmForFrntRIGrp14Timestamp : 39|3@0+ (1.0,0.0) [0.0|7.0] "Unitless" HCMR

BO_ 839 ZCUDBodyExpoFr28 : 8 ZCUD
 SG_ DwnLoadDynLtgPrmForFrntRIGrp15_UB : 36|1@0+ (1,0) [0|1] "" HCMR
 SG_ DwnLoadDynLtgPrmForFrntRIGrp15ContinueTime : 7|8@0+ (1.0,0.0) [0.0|255.0] "Unitless" HCMR
 SG_ DwnLoadDynLtgPrmForFrntRIGrp15HighBrightness : 15|4@0+ (1.0,0.0) [0.0|10.0] "Unitless" HCMR
 SG_ DwnLoadDynLtgPrmForFrntRIGrp15LowBrightness : 11|4@0+ (1.0,0.0) [0.0|10.0] "Unitless" HCMR
 SG_ DwnLoadDynLtgPrmForFrntRIGrp15Mode1 : 23|6@0+ (1,0) [0|63] "" HCMR
 SG_ DwnLoadDynLtgPrmForFrntRIGrp15OffsetTime : 31|6@0+ (1.0,0.0) [0.0|63.0] "Unitless" HCMR
 SG_ DwnLoadDynLtgPrmForFrntRIGrp15Timestamp : 39|3@0+ (1.0,0.0) [0.0|7.0] "Unitless" HCMR

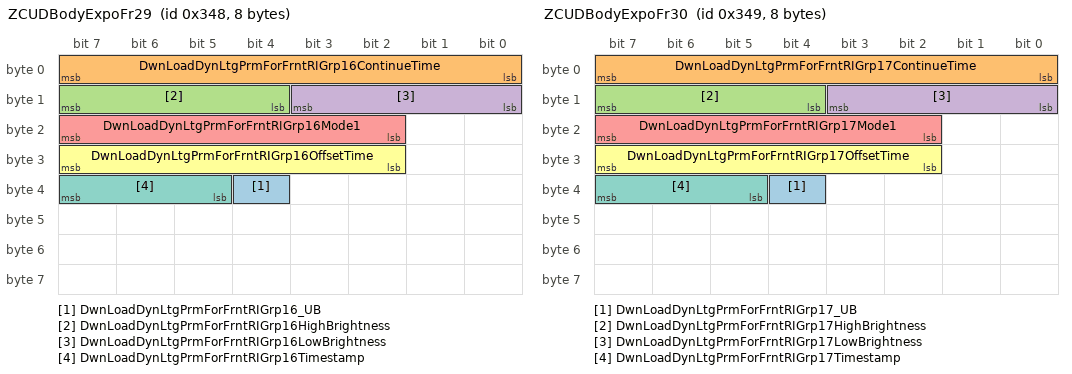
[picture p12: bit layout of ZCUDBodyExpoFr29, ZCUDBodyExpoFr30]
BO_ 840 ZCUDBodyExpoFr29 : 8 ZCUD
 SG_ DwnLoadDynLtgPrmForFrntRIGrp16_UB : 36|1@0+ (1,0) [0|1] "" HCMR
 SG_ DwnLoadDynLtgPrmForFrntRIGrp16ContinueTime : 7|8@0+ (1.0,0.0) [0.0|255.0] "Unitless" HCMR
 SG_ DwnLoadDynLtgPrmForFrntRIGrp16HighBrightness : 15|4@0+ (1.0,0.0) [0.0|10.0] "Unitless" HCMR
 SG_ DwnLoadDynLtgPrmForFrntRIGrp16LowBrightness : 11|4@0+ (1.0,0.0) [0.0|10.0] "Unitless" HCMR
 SG_ DwnLoadDynLtgPrmForFrntRIGrp16Mode1 : 23|6@0+ (1,0) [0|63] "" HCMR
 SG_ DwnLoadDynLtgPrmForFrntRIGrp16OffsetTime : 31|6@0+ (1.0,0.0) [0.0|63.0] "Unitless" HCMR
 SG_ DwnLoadDynLtgPrmForFrntRIGrp16Timestamp : 39|3@0+ (1.0,0.0) [0.0|7.0] "Unitless" HCMR

BO_ 841 ZCUDBodyExpoFr30 : 8 ZCUD
 SG_ DwnLoadDynLtgPrmForFrntRIGrp17_UB : 36|1@0+ (1,0) [0|1] "" HCMR
 SG_ DwnLoadDynLtgPrmForFrntRIGrp17ContinueTime : 7|8@0+ (1.0,0.0) [0.0|255.0] "Unitless" HCMR
 SG_ DwnLoadDynLtgPrmForFrntRIGrp17HighBrightness : 15|4@0+ (1.0,0.0) [0.0|10.0] "Unitless" HCMR
 SG_ DwnLoadDynLtgPrmForFrntRIGrp17LowBrightness : 11|4@0+ (1.0,0.0) [0.0|10.0] "Unitless" HCMR
 SG_ DwnLoadDynLtgPrmForFrntRIGrp17Mode1 : 23|6@0+ (1,0) [0|63] "" HCMR
 SG_ DwnLoadDynLtgPrmForFrntRIGrp17OffsetTime : 31|6@0+ (1.0,0.0) [0.0|63.0] "Unitless" HCMR
 SG_ DwnLoadDynLtgPrmForFrntRIGrp17Timestamp : 39|3@0+ (1.0,0.0) [0.0|7.0] "Unitless" HCMR

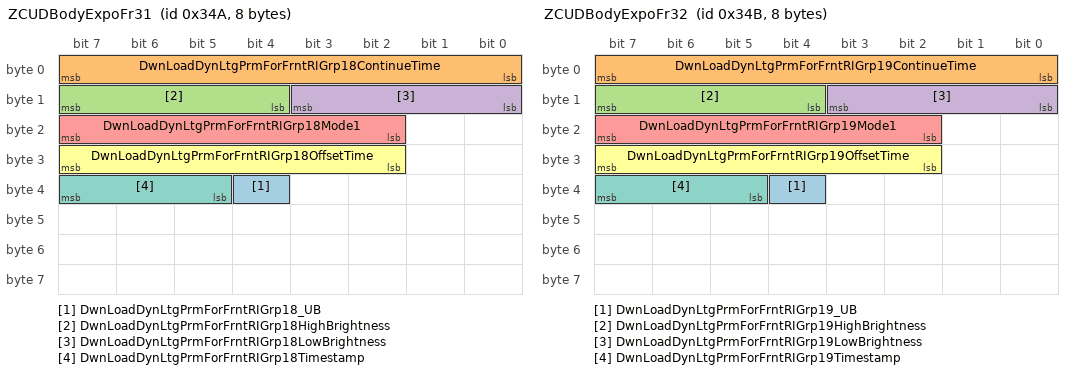
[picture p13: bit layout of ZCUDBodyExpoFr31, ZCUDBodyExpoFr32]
BO_ 842 ZCUDBodyExpoFr31 : 8 ZCUD
 SG_ DwnLoadDynLtgPrmForFrntRIGrp18_UB : 36|1@0+ (1,0) [0|1] "" HCMR
 SG_ DwnLoadDynLtgPrmForFrntRIGrp18ContinueTime : 7|8@0+ (1.0,0.0) [0.0|255.0] "Unitless" HCMR
 SG_ DwnLoadDynLtgPrmForFrntRIGrp18HighBrightness : 15|4@0+ (1.0,0.0) [0.0|10.0] "Unitless" HCMR
 SG_ DwnLoadDynLtgPrmForFrntRIGrp18LowBrightness : 11|4@0+ (1.0,0.0) [0.0|10.0] "Unitless" HCMR
 SG_ DwnLoadDynLtgPrmForFrntRIGrp18Mode1 : 23|6@0+ (1,0) [0|63] "" HCMR
 SG_ DwnLoadDynLtgPrmForFrntRIGrp18OffsetTime : 31|6@0+ (1.0,0.0) [0.0|63.0] "Unitless" HCMR
 SG_ DwnLoadDynLtgPrmForFrntRIGrp18Timestamp : 39|3@0+ (1.0,0.0) [0.0|7.0] "Unitless" HCMR

BO_ 843 ZCUDBodyExpoFr32 : 8 ZCUD
 SG_ DwnLoadDynLtgPrmForFrntRIGrp19_UB : 36|1@0+ (1,0) [0|1] "" HCMR
 SG_ DwnLoadDynLtgPrmForFrntRIGrp19ContinueTime : 7|8@0+ (1.0,0.0) [0.0|255.0] "Unitless" HCMR
 SG_ DwnLoadDynLtgPrmForFrntRIGrp19HighBrightness : 15|4@0+ (1.0,0.0) [0.0|10.0] "Unitless" HCMR
 SG_ DwnLoadDynLtgPrmForFrntRIGrp19LowBrightness : 11|4@0+ (1.0,0.0) [0.0|10.0] "Unitless" HCMR
 SG_ DwnLoadDynLtgPrmForFrntRIGrp19Mode1 : 23|6@0+ (1,0) [0|63] "" HCMR
 SG_ DwnLoadDynLtgPrmForFrntRIGrp19OffsetTime : 31|6@0+ (1.0,0.0) [0.0|63.0] "Unitless" HCMR
 SG_ DwnLoadDynLtgPrmForFrntRIGrp19Timestamp : 39|3@0+ (1.0,0.0) [0.0|7.0] "Unitless" HCMR

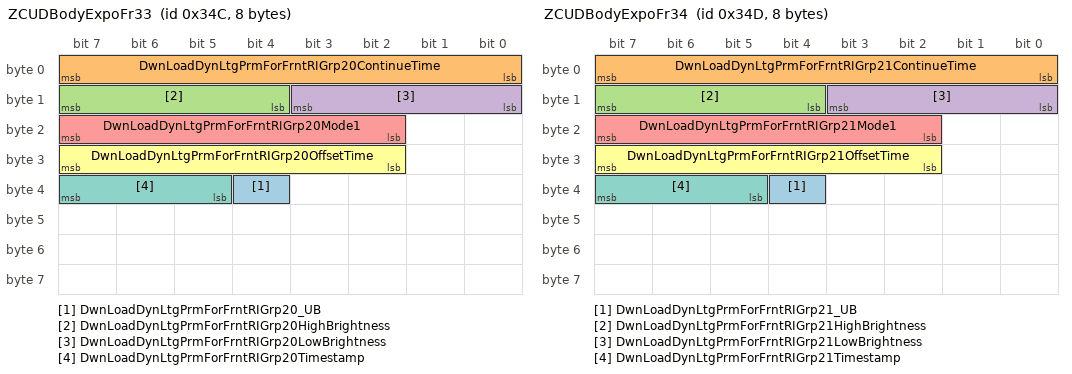
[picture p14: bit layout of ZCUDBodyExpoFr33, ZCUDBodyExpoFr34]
BO_ 844 ZCUDBodyExpoFr33 : 8 ZCUD
 SG_ DwnLoadDynLtgPrmForFrntRIGrp20_UB : 36|1@0+ (1,0) [0|1] "" HCMR
 SG_ DwnLoadDynLtgPrmForFrntRIGrp20ContinueTime : 7|8@0+ (1.0,0.0) [0.0|255.0] "Unitless" HCMR
 SG_ DwnLoadDynLtgPrmForFrntRIGrp20HighBrightness : 15|4@0+ (1.0,0.0) [0.0|10.0] "Unitless" HCMR
 SG_ DwnLoadDynLtgPrmForFrntRIGrp20LowBrightness : 11|4@0+ (1.0,0.0) [0.0|10.0] "Unitless" HCMR
 SG_ DwnLoadDynLtgPrmForFrntRIGrp20Mode1 : 23|6@0+ (1,0) [0|63] "" HCMR
 SG_ DwnLoadDynLtgPrmForFrntRIGrp20OffsetTime : 31|6@0+ (1.0,0.0) [0.0|63.0] "Unitless" HCMR
 SG_ DwnLoadDynLtgPrmForFrntRIGrp20Timestamp : 39|3@0+ (1.0,0.0) [0.0|7.0] "Unitless" HCMR

BO_ 845 ZCUDBodyExpoFr34 : 8 ZCUD
 SG_ DwnLoadDynLtgPrmForFrntRIGrp21_UB : 36|1@0+ (1,0) [0|1] "" HCMR
 SG_ DwnLoadDynLtgPrmForFrntRIGrp21ContinueTime : 7|8@0+ (1.0,0.0) [0.0|255.0] "Unitless" HCMR
 SG_ DwnLoadDynLtgPrmForFrntRIGrp21HighBrightness : 15|4@0+ (1.0,0.0) [0.0|10.0] "Unitless" HCMR
 SG_ DwnLoadDynLtgPrmForFrntRIGrp21LowBrightness : 11|4@0+ (1.0,0.0) [0.0|10.0] "Unitless" HCMR
 SG_ DwnLoadDynLtgPrmForFrntRIGrp21Mode1 : 23|6@0+ (1,0) [0|63] "" HCMR
 SG_ DwnLoadDynLtgPrmForFrntRIGrp21OffsetTime : 31|6@0+ (1.0,0.0) [0.0|63.0] "Unitless" HCMR
 SG_ DwnLoadDynLtgPrmForFrntRIGrp21Timestamp : 39|3@0+ (1.0,0.0) [0.0|7.0] "Unitless" HCMR

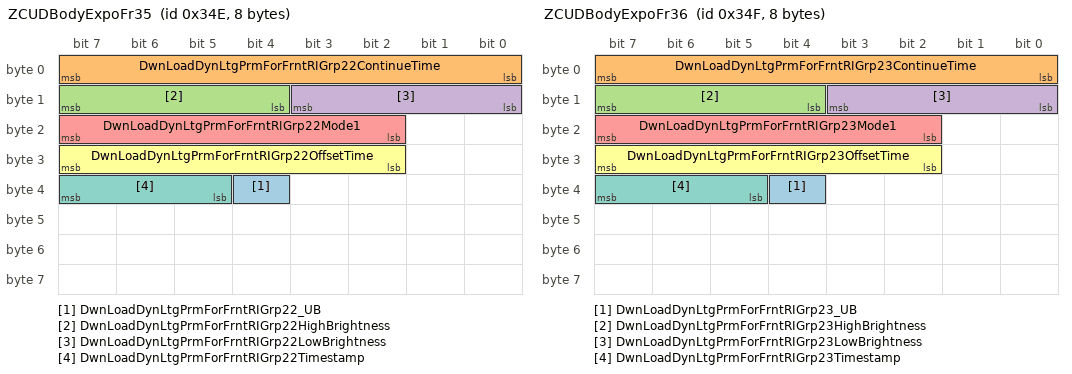
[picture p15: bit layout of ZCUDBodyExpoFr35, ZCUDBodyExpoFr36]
BO_ 846 ZCUDBodyExpoFr35 : 8 ZCUD
 SG_ DwnLoadDynLtgPrmForFrntRIGrp22_UB : 36|1@0+ (1,0) [0|1] "" HCMR
 SG_ DwnLoadDynLtgPrmForFrntRIGrp22ContinueTime : 7|8@0+ (1.0,0.0) [0.0|255.0] "Unitless" HCMR
 SG_ DwnLoadDynLtgPrmForFrntRIGrp22HighBrightness : 15|4@0+ (1.0,0.0) [0.0|10.0] "Unitless" HCMR
 SG_ DwnLoadDynLtgPrmForFrntRIGrp22LowBrightness : 11|4@0+ (1.0,0.0) [0.0|10.0] "Unitless" HCMR
 SG_ DwnLoadDynLtgPrmForFrntRIGrp22Mode1 : 23|6@0+ (1,0) [0|63] "" HCMR
 SG_ DwnLoadDynLtgPrmForFrntRIGrp22OffsetTime : 31|6@0+ (1.0,0.0) [0.0|63.0] "Unitless" HCMR
 SG_ DwnLoadDynLtgPrmForFrntRIGrp22Timestamp : 39|3@0+ (1.0,0.0) [0.0|7.0] "Unitless" HCMR

BO_ 847 ZCUDBodyExpoFr36 : 8 ZCUD
 SG_ DwnLoadDynLtgPrmForFrntRIGrp23_UB : 36|1@0+ (1,0) [0|1] "" HCMR
 SG_ DwnLoadDynLtgPrmForFrntRIGrp23ContinueTime : 7|8@0+ (1.0,0.0) [0.0|255.0] "Unitless" HCMR
 SG_ DwnLoadDynLtgPrmForFrntRIGrp23HighBrightness : 15|4@0+ (1.0,0.0) [0.0|10.0] "Unitless" HCMR
 SG_ DwnLoadDynLtgPrmForFrntRIGrp23LowBrightness : 11|4@0+ (1.0,0.0) [0.0|10.0] "Unitless" HCMR
 SG_ DwnLoadDynLtgPrmForFrntRIGrp23Mode1 : 23|6@0+ (1,0) [0|63] "" HCMR
 SG_ DwnLoadDynLtgPrmForFrntRIGrp23OffsetTime : 31|6@0+ (1.0,0.0) [0.0|63.0] "Unitless" HCMR
 SG_ DwnLoadDynLtgPrmForFrntRIGrp23Timestamp : 39|3@0+ (1.0,0.0) [0.0|7.0] "Unitless" HCMR

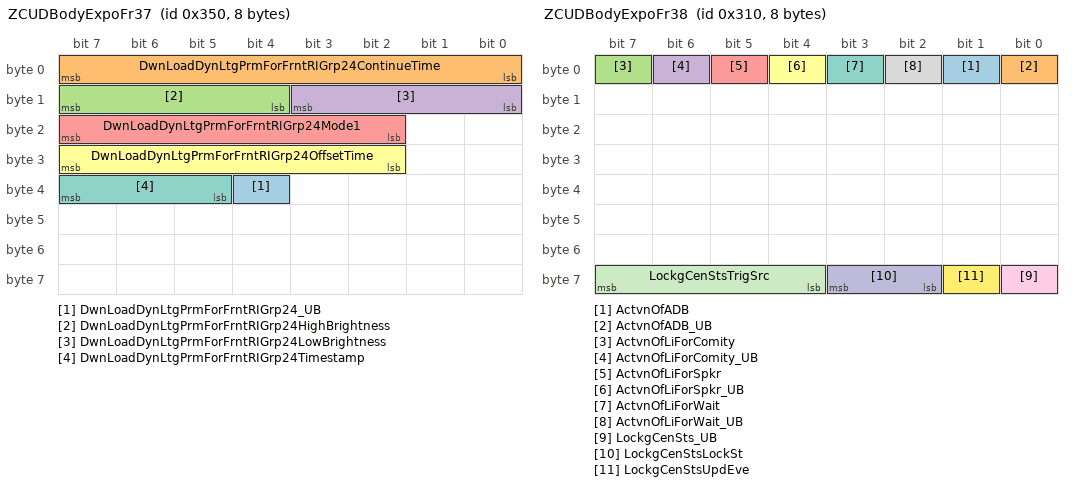
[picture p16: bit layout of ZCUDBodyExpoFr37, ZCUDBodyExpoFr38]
BO_ 848 ZCUDBodyExpoFr37 : 8 ZCUD
 SG_ DwnLoadDynLtgPrmForFrntRIGrp24_UB : 36|1@0+ (1,0) [0|1] "" HCMR
 SG_ DwnLoadDynLtgPrmForFrntRIGrp24ContinueTime : 7|8@0+ (1.0,0.0) [0.0|255.0] "Unitless" HCMR
 SG_ DwnLoadDynLtgPrmForFrntRIGrp24HighBrightness : 15|4@0+ (1.0,0.0) [0.0|10.0] "Unitless" HCMR
 SG_ DwnLoadDynLtgPrmForFrntRIGrp24LowBrightness : 11|4@0+ (1.0,0.0) [0.0|10.0] "Unitless" HCMR
 SG_ DwnLoadDynLtgPrmForFrntRIGrp24Mode1 : 23|6@0+ (1,0) [0|63] "" HCMR
 SG_ DwnLoadDynLtgPrmForFrntRIGrp24OffsetTime : 31|6@0+ (1.0,0.0) [0.0|63.0] "Unitless" HCMR
 SG_ DwnLoadDynLtgPrmForFrntRIGrp24Timestamp : 39|3@0+ (1.0,0.0) [0.0|7.0] "Unitless" HCMR

BO_ 784 ZCUDBodyExpoFr38 : 8 ZCUD
 SG_ ActvnOfADB : 1|1@0+ (1,0) [0|1] "" HCML,HCMR
 SG_ ActvnOfADB_UB : 0|1@0+ (1,0) [0|1] "" HCML,HCMR
 SG_ ActvnOfLiForComity : 7|1@0+ (1,0) [0|1] "" HCML,HCMR
 SG_ ActvnOfLiForComity_UB : 6|1@0+ (1,0) [0|1] "" HCML,HCMR
 SG_ ActvnOfLiForSpkr : 5|1@0+ (1,0) [0|1] "" HCML,HCMR
 SG_ ActvnOfLiForSpkr_UB : 4|1@0+ (1,0) [0|1] "" HCML,HCMR
 SG_ ActvnOfLiForWait : 3|1@0+ (1,0) [0|1] "" HCML,HCMR
 SG_ ActvnOfLiForWait_UB : 2|1@0+ (1,0) [0|1] "" HCML,HCMR
 SG_ LockgCenSts_UB : 56|1@0+ (1,0) [0|1] "" Vector__XXX
 SG_ LockgCenStsLockSt : 59|2@0+ (1,0) [0|3] "" Vector__XXX
 SG_ LockgCenStsTrigSrc : 63|4@0+ (1,0) [0|15] "" Vector__XXX
 SG_ LockgCenStsUpdEve : 57|1@0+ (1,0) [0|1] "" Vector__XXX

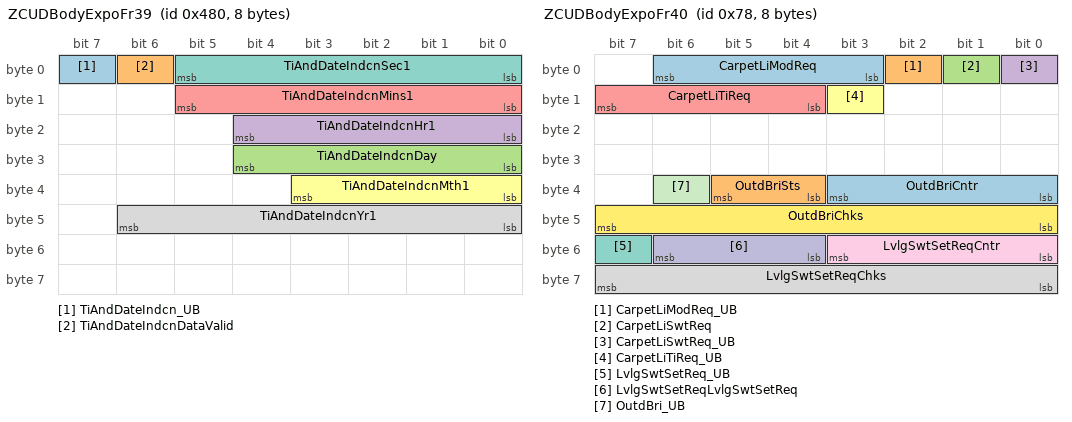
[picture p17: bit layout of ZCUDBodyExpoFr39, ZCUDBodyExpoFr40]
BO_ 1152 ZCUDBodyExpoFr39 : 8 ZCUD
 SG_ TiAndDateIndcn_UB : 7|1@0+ (1,0) [0|1] "" HCML,HCMR
 SG_ TiAndDateIndcnDataValid : 6|1@0+ (1,0) [0|1] "" HCML,HCMR
 SG_ TiAndDateIndcnDay : 28|5@0+ (1.0,0.0) [1.0|31.0] "Days" HCML,HCMR
 SG_ TiAndDateIndcnHr1 : 20|5@0+ (1.0,0.0) [0.0|23.0] "hours" HCML,HCMR
 SG_ TiAndDateIndcnMins1 : 13|6@0+ (1.0,0.0) [0.0|59.0] "Mins" HCML,HCMR
 SG_ TiAndDateIndcnMth1 : 35|4@0+ (1.0,0.0) [1.0|12.0] "Month" HCML,HCMR
 SG_ TiAndDateIndcnSec1 : 5|6@0+ (1.0,0.0) [0.0|59.0] "s" HCML,HCMR
 SG_ TiAndDateIndcnYr1 : 46|7@0+ (1.0,0.0) [0.0|99.0] "Year" HCML,HCMR

BO_ 120 ZCUDBodyExpoFr40 : 8 ZCUD
 SG_ CarpetLiModReq : 6|4@0+ (1,0) [0|15] "" Vector__XXX
 SG_ CarpetLiModReq_UB : 2|1@0+ (1,0) [0|1] "" Vector__XXX
 SG_ CarpetLiSwtReq : 1|1@0+ (1,0) [0|1] "" Vector__XXX
 SG_ CarpetLiSwtReq_UB : 0|1@0+ (1,0) [0|1] "" Vector__XXX
 SG_ CarpetLiTiReq : 15|4@0+ (1,0) [0|15] "" Vector__XXX
 SG_ CarpetLiTiReq_UB : 11|1@0+ (1,0) [0|1] "" Vector__XXX
 SG_ LvlgSwtSetReq_UB : 55|1@0+ (1,0) [0|1] "" HCML,HCMR
 SG_ LvlgSwtSetReqChks : 63|8@0+ (1.0,0.0) [0.0|255.0] "Unitless" HCML,HCMR
 SG_ LvlgSwtSetReqCntr : 51|4@0+ (1.0,0.0) [0.0|15.0] "Unitless" HCML,HCMR
 SG_ LvlgSwtSetReqLvlgSwtSetReq : 54|3@0+ (1,0) [0|7] "" HCML,HCMR
 SG_ OutdBri_UB : 38|1@0+ (1,0) [0|1] "" HCML,HCMR
 SG_ OutdBriChks : 47|8@0+ (1.0,0.0) [0.0|255.0] "Unitless" HCML,HCMR
 SG_ OutdBriCntr : 35|4@0+ (1.0,0.0) [0.0|15.0] "Unitless" HCML,HCMR
 SG_ OutdBriSts : 37|2@0+ (1,0) [0|3] "" HCML,HCMR

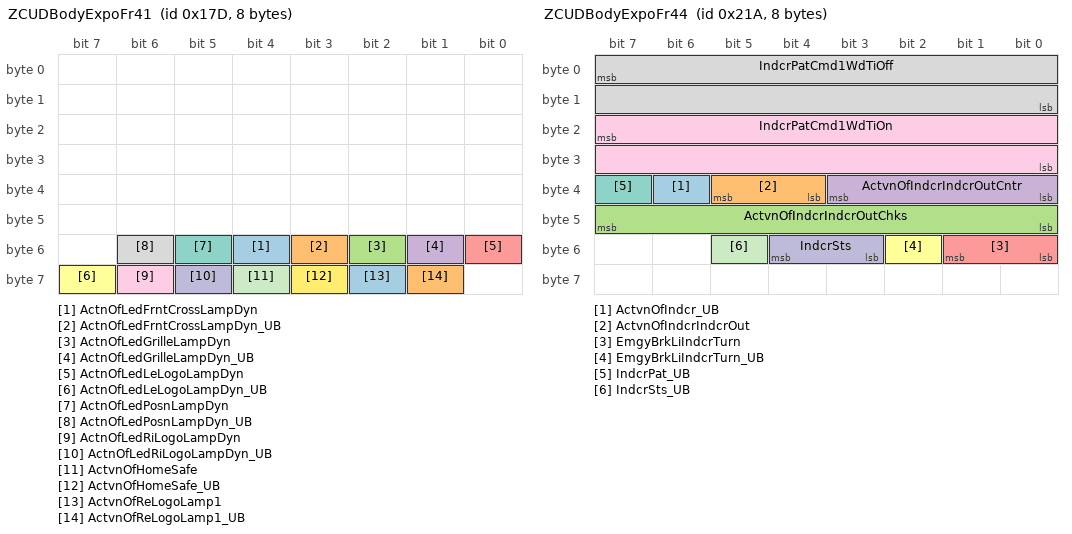
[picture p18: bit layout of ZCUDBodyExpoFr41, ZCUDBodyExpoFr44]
BO_ 381 ZCUDBodyExpoFr41 : 8 ZCUD
 SG_ ActnOfLedFrntCrossLampDyn : 52|1@0+ (1,0) [0|1] "" HCML,HCMR
 SG_ ActnOfLedFrntCrossLampDyn_UB : 51|1@0+ (1,0) [0|1] "" HCML,HCMR
 SG_ ActnOfLedGrilleLampDyn : 50|1@0+ (1,0) [0|1] "" HCML,HCMR
 SG_ ActnOfLedGrilleLampDyn_UB : 49|1@0+ (1,0) [0|1] "" HCML,HCMR
 SG_ ActnOfLedLeLogoLampDyn : 48|1@0+ (1,0) [0|1] "" HCML
 SG_ ActnOfLedLeLogoLampDyn_UB : 63|1@0+ (1,0) [0|1] "" HCML
 SG_ ActnOfLedPosnLampDyn : 53|1@0+ (1,0) [0|1] "" HCML,HCMR
 SG_ ActnOfLedPosnLampDyn_UB : 54|1@0+ (1,0) [0|1] "" HCML,HCMR
 SG_ ActnOfLedRiLogoLampDyn : 62|1@0+ (1,0) [0|1] "" HCMR
 SG_ ActnOfLedRiLogoLampDyn_UB : 61|1@0+ (1,0) [0|1] "" HCMR
 SG_ ActvnOfHomeSafe : 60|1@0+ (1,0) [0|1] "" HCML,HCMR
 SG_ ActvnOfHomeSafe_UB : 59|1@0+ (1,0) [0|1] "" HCML,HCMR
 SG_ ActvnOfReLogoLamp1 : 58|1@0+ (1,0) [0|1] "" Vector__XXX
 SG_ ActvnOfReLogoLamp1_UB : 57|1@0+ (1,0) [0|1] "" Vector__XXX

BO_ 612 ZCUDBodyExpoFr42 : 8 ZCUD
 SG_ ActvnOfApproach : 39|1@0+ (1,0) [0|1] "" HCML,HCMR
 SG_ ActvnOfApproach_UB : 35|1@0+ (1,0) [0|1] "" HCML,HCMR
 SG_ ActvnOfCarLoctr : 38|1@0+ (1,0) [0|1] "" HCML,HCMR
 SG_ ActvnOfCarLoctr_UB : 34|1@0+ (1,0) [0|1] "" HCML,HCMR
 SG_ ActvnOfWaitMode : 36|1@0+ (1,0) [0|1] "" HCML,HCMR
 SG_ ActvnOfWaitMode_UB : 32|1@0+ (1,0) [0|1] "" HCML,HCMR
 SG_ BrkPedlVal_UB : 42|1@0+ (1,0) [0|1] "" HCML,HCMR
 SG_ BrkPedlValBrkPedlVal : 54|15@0+ (0.00390625,0.0) [0.0|100.0] "%" HCML,HCMR
 SG_ BrkPedlValQf : 41|2@0+ (1,0) [0|3] "" HCML,HCMR
 SG_ IndcrNoSeq : 47|1@0+ (1,0) [0|1] "" HCML,HCMR
 SG_ IndcrNoSeq_UB : 46|1@0+ (1,0) [0|1] "" HCML,HCMR
 SG_ LitArea : 10|1@0+ (1,0) [0|1] "" HCML,HCMR
 SG_ LitArea_UB : 30|1@0+ (1,0) [0|1] "" HCML,HCMR
 SG_ WipgInfo_UB : 29|1@0+ (1,0) [0|1] "" HCML,HCMR
 SG_ WipgInfoWipgSpdInfo : 26|3@0+ (1,0) [0|7] "" HCML,HCMR
 SG_ WipgInfoWiprActv : 27|1@0+ (1,0) [0|1] "" HCML,HCMR
 SG_ WipgInfoWiprInWipgAr : 28|1@0+ (1,0) [0|1] "" HCML,HCMR

BO_ 522 ZCUDBodyExpoFr43 : 8 ZCUD
 SG_ ActnOfLedCornrgLampLe : 6|1@0+ (1,0) [0|1] "" HCML
 SG_ ActnOfLedCornrgLampLe_UB : 7|1@0+ (1,0) [0|1] "" HCML
 SG_ ActnOfLedCornrgLampRi : 22|1@0+ (1,0) [0|1] "" HCMR
 SG_ ActnOfLedCornrgLampRi_UB : 23|1@0+ (1,0) [0|1] "" HCMR
 SG_ ActnOfLedDaytiRunngLamp : 32|1@0+ (1,0) [0|1] "" HCML,HCMR
 SG_ ActnOfLedDaytiRunngLamp_UB : 33|1@0+ (1,0) [0|1] "" HCML,HCMR
 SG_ ActnOfLedFrntFogLamp : 34|1@0+ (1,0) [0|1] "" HCML,HCMR
 SG_ ActnOfLedFrntFogLamp_UB : 35|1@0+ (1,0) [0|1] "" HCML,HCMR
 SG_ ActnOfLedHiBeam : 36|1@0+ (1,0) [0|1] "" HCML,HCMR
 SG_ ActnOfLedHiBeam_UB : 37|1@0+ (1,0) [0|1] "" HCML,HCMR
 SG_ ActnOfLedLoBeam_UB : 5|1@0+ (1,0) [0|1] "" HCML,HCMR
 SG_ ActnOfLedLoBeamActnOfLedLoBeam : 4|1@0+ (1,0) [0|1] "" HCML,HCMR
 SG_ ActnOfLedLoBeamChks : 15|8@0+ (1.0,0.0) [0.0|255.0] "Unitless" HCML,HCMR
 SG_ ActnOfLedLoBeamCntr : 3|4@0+ (1.0,0.0) [0.0|15.0] "Unitless" HCML,HCMR
 SG_ ActnOfLedPosnLamp : 38|1@0+ (1,0) [0|1] "" HCML,HCMR
 SG_ ActnOfLedPosnLamp_UB : 39|1@0+ (1,0) [0|1] "" HCML,HCMR
 SG_ ActnOfLedReFogLamp : 40|1@0+ (1,0) [0|1] "" Vector__XXX
 SG_ ActnOfLedReFogLamp_UB : 41|1@0+ (1,0) [0|1] "" Vector__XXX
 SG_ ActnOfLedRePosnLamp : 60|1@0+ (1,0) [0|1] "" Vector__XXX
 SG_ ActnOfLedRePosnLamp_UB : 61|1@0+ (1,0) [0|1] "" Vector__XXX
 SG_ ActnOfLedRvsgLamp : 42|1@0+ (1,0) [0|1] "" Vector__XXX
 SG_ ActnOfLedRvsgLamp_UB : 43|1@0+ (1,0) [0|1] "" Vector__XXX
 SG_ ActnOfLedStopLamp_UB : 21|1@0+ (1,0) [0|1] "" Vector__XXX
 SG_ ActnOfLedStopLampActnOfLedStopLamp : 20|1@0+ (1,0) [0|1] "" Vector__XXX
 SG_ ActnOfLedStopLampChks : 31|8@0+ (1.0,0.0) [0.0|255.0] "Unitless" Vector__XXX
 SG_ ActnOfLedStopLampCntr : 19|4@0+ (1.0,0.0) [0.0|15.0] "Unitless" Vector__XXX
 SG_ ActvnOfAfs : 44|1@0+ (1,0) [0|1] "" HCML,HCMR
 SG_ ActvnOfAfs_UB : 45|1@0+ (1,0) [0|1] "" HCML,HCMR
 SG_ ActvnOfAhbc : 46|1@0+ (1,0) [0|1] "" HCML,HCMR
 SG_ ActvnOfAhbc_UB : 47|1@0+ (1,0) [0|1] "" HCML,HCMR
 SG_ ActvnOfAhl : 48|1@0+ (1,0) [0|1] "" HCML,HCMR
 SG_ ActvnOfAhl_UB : 49|1@0+ (1,0) [0|1] "" HCML,HCMR
 SG_ ActvnOfBrkLi : 50|1@0+ (1,0) [0|1] "" Vector__XXX
 SG_ ActvnOfBrkLi_UB : 51|1@0+ (1,0) [0|1] "" Vector__XXX
 SG_ ActvnOfDbl : 52|1@0+ (1,0) [0|1] "" HCML,HCMR
 SG_ ActvnOfDbl_UB : 53|1@0+ (1,0) [0|1] "" HCML,HCMR
 SG_ ActvnOfGoodByeLi : 54|1@0+ (1,0) [0|1] "" HCML,HCMR
 SG_ ActvnOfGoodByeLi_UB : 55|1@0+ (1,0) [0|1] "" HCML,HCMR
 SG_ ActvnOfTouristMod : 56|1@0+ (1,0) [0|1] "" HCML,HCMR
 SG_ ActvnOfTouristMod_UB : 57|1@0+ (1,0) [0|1] "" HCML,HCMR
 SG_ ActvnOfWelcomeLi : 58|1@0+ (1,0) [0|1] "" HCML,HCMR
 SG_ ActvnOfWelcomeLi_UB : 59|1@0+ (1,0) [0|1] "" HCML,HCMR

BO_ 538 ZCUDBodyExpoFr44 : 8 ZCUD
 SG_ ActvnOfIndcr_UB : 38|1@0+ (1,0) [0|1] "" HCML,HCMR
 SG_ ActvnOfIndcrIndcrOut : 37|2@0+ (1,0) [0|3] "" HCML,HCMR
 SG_ ActvnOfIndcrIndcrOutChks : 47|8@0+ (1.0,0.0) [0.0|255.0] "Unitless" HCML,HCMR
 SG_ ActvnOfIndcrIndcrOutCntr : 35|4@0+ (1.0,0.0) [0.0|15.0] "Unitless" HCML,HCMR
 SG_ EmgyBrkLiIndcrTurn : 49|2@0+ (1,0) [0|3] "" Vector__XXX
 SG_ EmgyBrkLiIndcrTurn_UB : 50|1@0+ (1,0) [0|1] "" Vector__XXX
 SG_ IndcrPat_UB : 39|1@0+ (1,0) [0|1] "" HCML,HCMR
 SG_ IndcrPatCmd1WdTiOff : 7|16@0+ (0.001,0.0) [0.0|65.535] "s" HCML,HCMR
 SG_ IndcrPatCmd1WdTiOn : 23|16@0+ (0.001,0.0) [0.0|65.535] "s" HCML,HCMR
 SG_ IndcrSts : 52|2@0+ (1,0) [0|3] "" HCML,HCMR
 SG_ IndcrSts_UB : 53|1@0+ (1,0) [0|1] "" HCML,HCMR

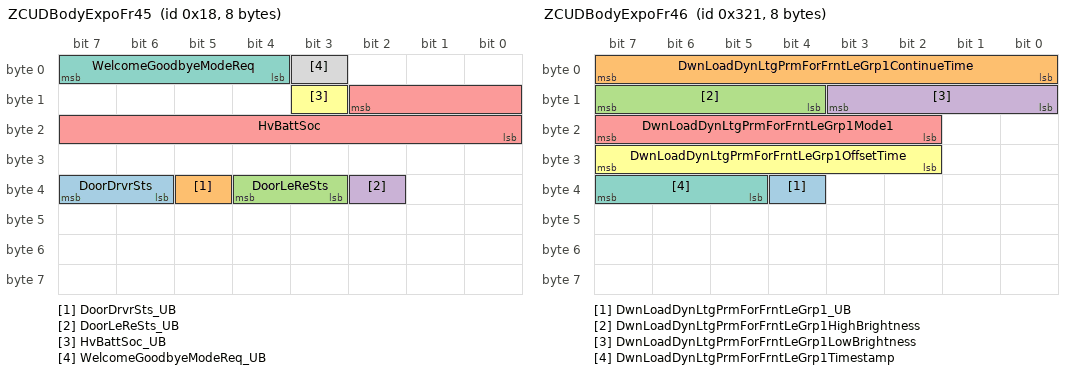
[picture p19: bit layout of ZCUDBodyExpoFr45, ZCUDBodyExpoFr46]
BO_ 24 ZCUDBodyExpoFr45 : 8 ZCUD
 SG_ DoorDrvrSts : 39|2@0+ (1,0) [0|3] "" Vector__XXX
 SG_ DoorDrvrSts_UB : 37|1@0+ (1,0) [0|1] "" Vector__XXX
 SG_ DoorLeReSts : 36|2@0+ (1,0) [0|3] "" Vector__XXX
 SG_ DoorLeReSts_UB : 34|1@0+ (1,0) [0|1] "" Vector__XXX
 SG_ HvBattSoc : 10|11@0+ (0.05,0.0) [0.0|100.0] "%" Vector__XXX
 SG_ HvBattSoc_UB : 11|1@0+ (1,0) [0|1] "" Vector__XXX
 SG_ WelcomeGoodbyeModeReq : 7|4@0+ (1,0) [0|15] "" HCML,HCMR
 SG_ WelcomeGoodbyeModeReq_UB : 3|1@0+ (1,0) [0|1] "" HCML,HCMR

BO_ 801 ZCUDBodyExpoFr46 : 8 ZCUD
 SG_ DwnLoadDynLtgPrmForFrntLeGrp1_UB : 36|1@0+ (1,0) [0|1] "" HCML
 SG_ DwnLoadDynLtgPrmForFrntLeGrp1ContinueTime : 7|8@0+ (1.0,0.0) [0.0|255.0] "Unitless" HCML
 SG_ DwnLoadDynLtgPrmForFrntLeGrp1HighBrightness : 15|4@0+ (1.0,0.0) [0.0|10.0] "Unitless" HCML
 SG_ DwnLoadDynLtgPrmForFrntLeGrp1LowBrightness : 11|4@0+ (1.0,0.0) [0.0|10.0] "Unitless" HCML
 SG_ DwnLoadDynLtgPrmForFrntLeGrp1Mode1 : 23|6@0+ (1,0) [0|63] "" HCML
 SG_ DwnLoadDynLtgPrmForFrntLeGrp1OffsetTime : 31|6@0+ (1.0,0.0) [0.0|63.0] "Unitless" HCML
 SG_ DwnLoadDynLtgPrmForFrntLeGrp1Timestamp : 39|3@0+ (1.0,0.0) [0.0|7.0] "Unitless" HCML

CM_ SG_ 82 ActvnOfDefdLiShow "User-defined light show";
CM_ SG_ 82 ActvnOfMusicShowforEITL "music show activation signal";
CM_ SG_ 82 AutWinWipgCmd "Wiping speed command.";
CM_ SG_ 82 LiOprnMod "Information about day, night, twilight and tunnel detection.";
CM_ SG_ 82 MusicShowPlaySts "indicate music show playing status";
CM_ SG_ 82 SteerWhlSnsrAg "Actual steering wheel angle from the actual centre position of the steering wheel. ";
CM_ SG_ 82 SteerWhlSnsrAgSpd "Actual steering wheel angle from the actual centre position of the steering wheel. Steering angle speed with steering wheel rotation direction.  ";
CM_ SG_ 82 SteerWhlSnsrChks "Checksum for steering wheel sensor data.";
CM_ SG_ 82 SteerWhlSnsrCntr "Counter value for steering wheel sensor data.";
CM_ SG_ 82 SteerWhlSnsrQf "Qf for steering wheel sensor information";
CM_ SG_ 768 ActvnOfRvsg "Activation of Reverse Light";
CM_ SG_ 768 BrkPedlrRatPerc "Brake pedal Ratio in percentage value";
CM_ SG_ 768 BrkPedlrRatQf "quality factor";
CM_ SG_ 768 YawRateReqdByDrvr "When the vehicle is making a left turn this signal is supposed to show positive numbers. Unfiltered and offset compensated plausibility check";
CM_ SG_ 80 DoorPassSts "DoorPassSts - Passenger Door Status
Ukwn - Unknown status
Opend - Opened
Clsd - Closed";
CM_ SG_ 80 DoorRiReSts "DoorRiReSts - Right Rear Side Door Status
Ukwn - Unknown status
Opend - Opened
Clsd - Closed";
CM_ SG_ 80 VehSpdLgtA "Vehicle speed longitudinal based on wheel speed sensors and longitudinal acceleration.";
CM_ SG_ 80 VehSpdLgtChks "Checksum";
CM_ SG_ 80 VehSpdLgtCntr "Counter";
CM_ SG_ 80 VehSpdLgtQf "Quality factor for vehicle speed as measured by wheel speed sensors and longitudinal acceleration.";
CM_ SG_ 384 VehCfgPrmBlkIDBytePosn1 "signal block counter.";
CM_ SG_ 384 VehCfgPrmCCPBytePosn2 " (BlockID-1)*7 + 1. ";
CM_ SG_ 384 VehCfgPrmCCPBytePosn3 " (BlockID-1)*7 + 2. ";
CM_ SG_ 384 VehCfgPrmCCPBytePosn4 " (BlockID-1)*7 + 3. ";
CM_ SG_ 384 VehCfgPrmCCPBytePosn5 " (BlockID-1)*7 + 4. ";
CM_ SG_ 384 VehCfgPrmCCPBytePosn6 " (BlockID-1)*7 + 5. ";
CM_ SG_ 384 VehCfgPrmCCPBytePosn7 " (BlockID-1)*7 + 6. ";
CM_ SG_ 384 VehCfgPrmCCPBytePosn8 " (BlockID-1)*7 + 7. ";
CM_ SG_ 512 BkpOfDstTrvld "total traveled distance.";
CM_ SG_ 512 ExtrLiRlyPwrDwn "Informs HCMs about upcoming shut down of Exterior Light Relay.";
CM_ SG_ 512 VehBattUSysU "Vehicle System Voltage At 12V side";
CM_ SG_ 512 VehBattUSysUQf "Present vehicle voltage measured by CEM with QF";
CM_ SG_ 544 ActnOfLedFrntCrossLamp "Activate LED Front Middle Cross Lamp.";
CM_ SG_ 544 ActnOfLedGrilleLamp "Activate LED Front Grille Lamp.";
CM_ SG_ 544 ActnOfLedLeLogoLamp "Activate LED Left Logo Light Lamp.";
CM_ SG_ 544 ActnOfLedRiLogoLamp "Activate LED Right Logo Light Lamp.";
CM_ SG_ 544 Body2CntrForMissCom "Body Exposed detection for Diagnostic";
CM_ SG_ 544 CarTiGlb "Presents a tiime value that shall be used by all ECUs to time-stamp diagnsotic trouble codes (DTC) according to the requirements for Global DTC snapshot data.";
CM_ SG_ 544 TrSts "TrSts - Tailgate or Bootlid Status
Ukwn - Unknown status
Opend - Opened
Clsd - Closed";
CM_ SG_ 128 AccrPedlRatAccrPedlRat "Accelerator Pedal Position with adapted 0 point. Value as percentage of fully pressed pedal";
CM_ SG_ 128 AccrPedlRatChks "Accelerator Pedal Position with adapted 0 point. Value as percentage of fully pressed pedal. Checksum";
CM_ SG_ 128 AccrPedlRatCntr "Accelerator Pedal Position with adapted 0 point. Value as percentage of fully pressed pedal. Counter";
CM_ SG_ 128 AmbTRawAmbTVal "Unfiltered ambient temp raw data in deg C. Ambient temp value";
CM_ SG_ 128 AmbTRawQly "Unfiltered ambient temp raw data in deg C. Quality Factor of the ambient temp";
CM_ SG_ 128 BrkPedlSnsrChks "E2E protection, checksum. ";
CM_ SG_ 128 BrkPedlSnsrCntr "E2E protection, counter.";
CM_ SG_ 128 BrkPedlSnsrQf "Brake pedal state, quality factor";
CM_ SG_ 128 BrkPedlSnsrSt "brake pedal state, pressed or not pressed.";
CM_ SG_ 128 TooManyCars "Whether there are too many cars";
CM_ SG_ 387 VehCfgPrmExtBlkIDBytePosn1 "CarConfigExtended BlockID";
CM_ SG_ 387 VehCfgPrmExtCCPBytePosn2 "CarConfigExtended BytePos2";
CM_ SG_ 387 VehCfgPrmExtCCPBytePosn3 "CarConfigExtended BytePos3";
CM_ SG_ 387 VehCfgPrmExtCCPBytePosn4 "CarConfigExtended BytePos4";
CM_ SG_ 387 VehCfgPrmExtCCPBytePosn5 "CarConfigExtended BytePos5";
CM_ SG_ 387 VehCfgPrmExtCCPBytePosn6 "CarConfigExtended BytePos6";
CM_ SG_ 387 VehCfgPrmExtCCPBytePosn7 "CarConfigExtended BytePos7";
CM_ SG_ 387 VehCfgPrmExtCCPBytePosn8 "CarConfigExtended BytePos8";
CM_ SG_ 389 ActvnOfShowModLi "Activate show mode light";
CM_ SG_ 389 TrafficSignForADB1AdbAbsDist "refer to VehObjforADB1";
CM_ SG_ 389 TrafficSignForADB1AdbDetdQly "refer to VehObjforADB1";
CM_ SG_ 389 TrafficSignForADB1AdbHozlAgLe "refer to VehObjforADB1";
CM_ SG_ 389 TrafficSignForADB1AdbHozlAgRi "refer to VehObjforADB1";
CM_ SG_ 389 TrafficSignForADB1AdbTrkInfo "refer to VehObjforADB1";
CM_ SG_ 389 TrafficSignForADB1AdbVertAgBot "angle between ego vehicle camera and the bottom of object ";
CM_ SG_ 389 TrafficSignForADB1AdbVertAgTop "angle between ego vehicle camera and the top of object ";
CM_ SG_ 390 TrafficSignForADB2AdbAbsDist "refer to VehObjforADB1";
CM_ SG_ 390 TrafficSignForADB2AdbDetdQly "refer to VehObjforADB1";
CM_ SG_ 390 TrafficSignForADB2AdbHozlAgLe "refer to VehObjforADB1";
CM_ SG_ 390 TrafficSignForADB2AdbHozlAgRi "refer to VehObjforADB1";
CM_ SG_ 390 TrafficSignForADB2AdbTrkInfo "refer to VehObjforADB1";
CM_ SG_ 390 TrafficSignForADB2AdbVertAgBot "angle between ego vehicle camera and the bottom of object ";
CM_ SG_ 390 TrafficSignForADB2AdbVertAgTop "angle between ego vehicle camera and the top of object ";
CM_ SG_ 391 VehObjforAHBAdbAbsDist "refer to VehObjforADB1";
CM_ SG_ 391 VehObjforAHBAdbClassn "refer to VehObjforADB1";
CM_ SG_ 391 VehObjforAHBAdbClassnQly "refer to VehObjforADB1";
CM_ SG_ 391 VehObjforAHBAdbDetdQly "refer to VehObjforADB1";
CM_ SG_ 391 VehObjforAHBAdbHozlAg "refer to VehObjforADB1";
CM_ SG_ 391 VehObjforAHBAdbObjDir "refer to VehObjforADB1";
CM_ SG_ 391 VehObjforAHBAdbObjHozlAgSpd "refer to VehObjforADB1";
CM_ SG_ 391 VehObjforAHBAdbObjVertAgSpd "refer to VehObjforADB1";
CM_ SG_ 391 VehObjforAHBAdbTrkInfo "refer to VehObjforADB1";
CM_ SG_ 391 VehObjforAHBAdbVertAg "refer to VehObjforADB1";
CM_ SG_ 392 VehObjforADB1AdbAbsDist "Absolute distance between ego vehicle/camera and object";
CM_ SG_ 392 VehObjforADB1AdbClassn "Object Type";
CM_ SG_ 392 VehObjforADB1AdbHozlAgLe "horizontal angle between left of object front or tail lamp and the ego vehicle camera";
CM_ SG_ 392 VehObjforADB1AdbHozlAgRi "horizontal angle between right of object front or tail lamp and the ego vehicle camera";
CM_ SG_ 392 VehObjforADB1AdbObjDir "Object moving direction";
CM_ SG_ 392 VehObjforADB1AdbObjHozlAgSpdLe "Object left angle moving speed";
CM_ SG_ 392 VehObjforADB1AdbObjHozlAgSpdRi "Object right angle moving speed";
CM_ SG_ 392 VehObjforADB1AdbTrkInfo "Is the object a tracked one or a spontaneously occuring one";
CM_ SG_ 392 VehObjforADB1AdbVertAg "angle between ego vehicle camera and the bottom of object ";
CM_ SG_ 393 VehObjforADB2AdbAbsDist "Absolute distance between ego vehicle/camera and object";
CM_ SG_ 393 VehObjforADB2AdbClassn "Object Type";
CM_ SG_ 393 VehObjforADB2AdbHozlAgLe "horizontal angle between left of object front or tail lamp and the ego vehicle camera";
CM_ SG_ 393 VehObjforADB2AdbHozlAgRi "horizontal angle between right of object front or tail lamp and the ego vehicle camera";
CM_ SG_ 393 VehObjforADB2AdbObjDir "Object moving direction";
CM_ SG_ 393 VehObjforADB2AdbObjHozlAgSpdLe "Object left angle moving speed";
CM_ SG_ 393 VehObjforADB2AdbObjHozlAgSpdRi "Object right angle moving speed";
CM_ SG_ 393 VehObjforADB2AdbTrkInfo "Is the object a tracked one or a spontaneously occuring one";
CM_ SG_ 393 VehObjforADB2AdbVertAg "angle between ego vehicle camera and the bottom of object ";
CM_ SG_ 394 VehObjforADB3AdbAbsDist "Absolute distance between ego vehicle/camera and object";
CM_ SG_ 394 VehObjforADB3AdbClassn "Object Type";
CM_ SG_ 394 VehObjforADB3AdbHozlAgLe "horizontal angle between left of object front or tail lamp and the ego vehicle camera";
CM_ SG_ 394 VehObjforADB3AdbHozlAgRi "horizontal angle between right of object front or tail lamp and the ego vehicle camera";
CM_ SG_ 394 VehObjforADB3AdbObjDir "Object moving direction";
CM_ SG_ 394 VehObjforADB3AdbObjHozlAgSpdLe "Object left angle moving speed";
CM_ SG_ 394 VehObjforADB3AdbObjHozlAgSpdRi "Object right angle moving speed";
CM_ SG_ 394 VehObjforADB3AdbTrkInfo "Is the object a tracked one or a spontaneously occuring one";
CM_ SG_ 394 VehObjforADB3AdbVertAg "angle between ego vehicle camera and the bottom of object ";
CM_ SG_ 395 VehObjforADB4AdbAbsDist "Absolute distance between ego vehicle/camera and object";
CM_ SG_ 395 VehObjforADB4AdbClassn "Object Type";
CM_ SG_ 395 VehObjforADB4AdbHozlAgLe "horizontal angle between left of object front or tail lamp and the ego vehicle camera";
CM_ SG_ 395 VehObjforADB4AdbHozlAgRi "horizontal angle between right of object front or tail lamp and the ego vehicle camera";
CM_ SG_ 395 VehObjforADB4AdbObjDir "Object moving direction";
CM_ SG_ 395 VehObjforADB4AdbObjHozlAgSpdLe "Object left angle moving speed";
CM_ SG_ 395 VehObjforADB4AdbObjHozlAgSpdRi "Object right angle moving speed";
CM_ SG_ 395 VehObjforADB4AdbTrkInfo "Is the object a tracked one or a spontaneously occuring one";
CM_ SG_ 395 VehObjforADB4AdbVertAg "angle between ego vehicle camera and the bottom of object ";
CM_ SG_ 396 VehObjforADB5AdbAbsDist "Absolute distance between ego vehicle/camera and object";
CM_ SG_ 396 VehObjforADB5AdbClassn "Object Type";
CM_ SG_ 396 VehObjforADB5AdbHozlAgLe "horizontal angle between left of object front or tail lamp and the ego vehicle camera";
CM_ SG_ 396 VehObjforADB5AdbHozlAgRi "horizontal angle between right of object front or tail lamp and the ego vehicle camera";
CM_ SG_ 396 VehObjforADB5AdbObjDir "Object moving direction";
CM_ SG_ 396 VehObjforADB5AdbObjHozlAgSpdLe "Object left angle moving speed";
CM_ SG_ 396 VehObjforADB5AdbObjHozlAgSpdRi "Object right angle moving speed";
CM_ SG_ 396 VehObjforADB5AdbTrkInfo "Is the object a tracked one or a spontaneously occuring one";
CM_ SG_ 396 VehObjforADB5AdbVertAg "angle between ego vehicle camera and the bottom of object ";
CM_ SG_ 397 VehObjforADB6AdbAbsDist "Absolute distance between ego vehicle/camera and object";
CM_ SG_ 397 VehObjforADB6AdbClassn "Object Type";
CM_ SG_ 397 VehObjforADB6AdbHozlAgLe "horizontal angle between left of object front or tail lamp and the ego vehicle camera";
CM_ SG_ 397 VehObjforADB6AdbHozlAgRi "horizontal angle between right of object front or tail lamp and the ego vehicle camera";
CM_ SG_ 397 VehObjforADB6AdbObjDir "Object moving direction";
CM_ SG_ 397 VehObjforADB6AdbObjHozlAgSpdLe "Object left angle moving speed";
CM_ SG_ 397 VehObjforADB6AdbObjHozlAgSpdRi "Object right angle moving speed";
CM_ SG_ 397 VehObjforADB6AdbTrkInfo "Is the object a tracked one or a spontaneously occuring one";
CM_ SG_ 397 VehObjforADB6AdbVertAg "angle between ego vehicle camera and the bottom of object ";
CM_ SG_ 398 VehObjforADB7AdbAbsDist "Absolute distance between ego vehicle/camera and object";
CM_ SG_ 398 VehObjforADB7AdbClassn "Object Type";
CM_ SG_ 398 VehObjforADB7AdbHozlAgLe "horizontal angle between left of object front or tail lamp and the ego vehicle camera";
CM_ SG_ 398 VehObjforADB7AdbHozlAgRi "horizontal angle between right of object front or tail lamp and the ego vehicle camera";
CM_ SG_ 398 VehObjforADB7AdbObjDir "Object moving direction";
CM_ SG_ 398 VehObjforADB7AdbObjHozlAgSpdLe "Object left angle moving speed";
CM_ SG_ 398 VehObjforADB7AdbObjHozlAgSpdRi "Object right angle moving speed";
CM_ SG_ 398 VehObjforADB7AdbTrkInfo "Is the object a tracked one or a spontaneously occuring one";
CM_ SG_ 398 VehObjforADB7AdbVertAg "angle between ego vehicle camera and the bottom of object ";
CM_ SG_ 399 VehObjforADB8AdbAbsDist "Absolute distance between ego vehicle/camera and object";
CM_ SG_ 399 VehObjforADB8AdbClassn "Object Type";
CM_ SG_ 399 VehObjforADB8AdbHozlAgLe "horizontal angle between left of object front or tail lamp and the ego vehicle camera";
CM_ SG_ 399 VehObjforADB8AdbHozlAgRi "horizontal angle between right of object front or tail lamp and the ego vehicle camera";
CM_ SG_ 399 VehObjforADB8AdbObjDir "Object moving direction";
CM_ SG_ 399 VehObjforADB8AdbObjHozlAgSpdLe "Object left angle moving speed";
CM_ SG_ 399 VehObjforADB8AdbObjHozlAgSpdRi "Object right angle moving speed";
CM_ SG_ 399 VehObjforADB8AdbTrkInfo "Is the object a tracked one or a spontaneously occuring one";
CM_ SG_ 399 VehObjforADB8AdbVertAg "angle between ego vehicle camera and the bottom of object ";
CM_ SG_ 64 ActnOfAssistantLi "Activation signal of assistant light";
CM_ SG_ 64 CameraStsforAHBC "To discribe camera can working or not.";
CM_ SG_ 64 RainLi "Information about rain detection for light activation/deactivation.";
CM_ SG_ 64 VehModMngtGlbSafe1CarModSts1 "CarMode Status";
CM_ SG_ 64 VehModMngtGlbSafe1CarModSubtypWdCarModSubtyp "CarMode substate status";
CM_ SG_ 64 VehModMngtGlbSafe1Chks "Checksum";
CM_ SG_ 64 VehModMngtGlbSafe1Cntr "Counter";
CM_ SG_ 64 VehModMngtGlbSafe1EgyLvlElecMai "Main energy level in the vehicle.";
CM_ SG_ 64 VehModMngtGlbSafe1EgyLvlElecSubtyp "Substate of the energy level in the vehicle.";
CM_ SG_ 64 VehModMngtGlbSafe1FltEgyCnsWdSts "High quiescent current detected by CEM via BMS.";
CM_ SG_ 64 VehModMngtGlbSafe1PwrLvlElecMai "Main Power level in the vehicle.";
CM_ SG_ 64 VehModMngtGlbSafe1PwrLvlElecSubtyp "Substate of the power level in the vehicle.";
CM_ SG_ 64 VehModMngtGlbSafe1UsgModSts "UsageMode Status";
CM_ SG_ 64 WipgAutFrntMod "Information regarding rain sensor operational mode.";
CM_ SG_ 400 SuspPosnVertAgGenQf "External CAN signal for inform the rear angle that are calculated from front and rear body height. This signal are used for head lamp control.";
CM_ SG_ 400 SuspPosnVertAgSuspPosnVertAg "External CAN signal for inform the rear angle that are calculated from front and rear body height. This signal are used for head lamp control.";
CM_ SG_ 400 SuspPosnVertLvlFrnt "Front suspension level";
CM_ SG_ 400 SuspPosnVertLvlFrntQf "Front Qf";
CM_ SG_ 400 SuspPosnVertLvlRe "Rear suspension level";
CM_ SG_ 400 SuspPosnVertLvlReQf "Rear Qf";
CM_ SG_ 28 ExtrLiShowActvnReq "Request signal for activating Light show, if the value has been set to on. ";
CM_ SG_ 28 ExtrLiShowFileTxReq "Request signal for transferring sequence table. If the value has been set to on, the parameter of lamp elements can be downloaded from IHU to HCM/RCM. ";
CM_ SG_ 834 DwnLoadDynLtgPrmForFrntRIGrp10ContinueTime "Light Show Continue Time Parameter 2";
CM_ SG_ 834 DwnLoadDynLtgPrmForFrntRIGrp10HighBrightness "Light Show Upper Brightness Parameter 2";
CM_ SG_ 834 DwnLoadDynLtgPrmForFrntRIGrp10LowBrightness "Light Show Lower Brightness Parameter 2";
CM_ SG_ 834 DwnLoadDynLtgPrmForFrntRIGrp10Mode1 "Light Show Mode Parameter 2";
CM_ SG_ 834 DwnLoadDynLtgPrmForFrntRIGrp10OffsetTime "Light Show Offset Time Parameter 2";
CM_ SG_ 834 DwnLoadDynLtgPrmForFrntRIGrp10Timestamp "Light Show time stamp 2";
CM_ SG_ 835 DwnLoadDynLtgPrmForFrntRIGrp11ContinueTime "Light Show Continue Time Parameter 2";
CM_ SG_ 835 DwnLoadDynLtgPrmForFrntRIGrp11HighBrightness "Light Show Upper Brightness Parameter 2";
CM_ SG_ 835 DwnLoadDynLtgPrmForFrntRIGrp11LowBrightness "Light Show Lower Brightness Parameter 2";
CM_ SG_ 835 DwnLoadDynLtgPrmForFrntRIGrp11Mode1 "Light Show Mode Parameter 2";
CM_ SG_ 835 DwnLoadDynLtgPrmForFrntRIGrp11OffsetTime "Light Show Offset Time Parameter 2";
CM_ SG_ 835 DwnLoadDynLtgPrmForFrntRIGrp11Timestamp "Light Show time stamp 2";
CM_ SG_ 836 DwnLoadDynLtgPrmForFrntRIGrp12ContinueTime "Light Show Continue Time Parameter 2";
CM_ SG_ 836 DwnLoadDynLtgPrmForFrntRIGrp12HighBrightness "Light Show Upper Brightness Parameter 2";
CM_ SG_ 836 DwnLoadDynLtgPrmForFrntRIGrp12LowBrightness "Light Show Lower Brightness Parameter 2";
CM_ SG_ 836 DwnLoadDynLtgPrmForFrntRIGrp12Mode1 "Light Show Mode Parameter 2";
CM_ SG_ 836 DwnLoadDynLtgPrmForFrntRIGrp12OffsetTime "Light Show Offset Time Parameter 2";
CM_ SG_ 836 DwnLoadDynLtgPrmForFrntRIGrp12Timestamp "Light Show time stamp 2";
CM_ SG_ 837 DwnLoadDynLtgPrmForFrntRIGrp13ContinueTime "Light Show Continue Time Parameter 2";
CM_ SG_ 837 DwnLoadDynLtgPrmForFrntRIGrp13HighBrightness "Light Show Upper Brightness Parameter 2";
CM_ SG_ 837 DwnLoadDynLtgPrmForFrntRIGrp13LowBrightness "Light Show Lower Brightness Parameter 2";
CM_ SG_ 837 DwnLoadDynLtgPrmForFrntRIGrp13Mode1 "Light Show Mode Parameter 2";
CM_ SG_ 837 DwnLoadDynLtgPrmForFrntRIGrp13OffsetTime "Light Show Offset Time Parameter 2";
CM_ SG_ 837 DwnLoadDynLtgPrmForFrntRIGrp13Timestamp "Light Show time stamp 2";
CM_ SG_ 838 DwnLoadDynLtgPrmForFrntRIGrp14ContinueTime "Light Show Continue Time Parameter 2";
CM_ SG_ 838 DwnLoadDynLtgPrmForFrntRIGrp14HighBrightness "Light Show Upper Brightness Parameter 2";
CM_ SG_ 838 DwnLoadDynLtgPrmForFrntRIGrp14LowBrightness "Light Show Lower Brightness Parameter 2";
CM_ SG_ 838 DwnLoadDynLtgPrmForFrntRIGrp14Mode1 "Light Show Mode Parameter 2";
CM_ SG_ 838 DwnLoadDynLtgPrmForFrntRIGrp14OffsetTime "Light Show Offset Time Parameter 2";
CM_ SG_ 838 DwnLoadDynLtgPrmForFrntRIGrp14Timestamp "Light Show time stamp 2";
CM_ SG_ 839 DwnLoadDynLtgPrmForFrntRIGrp15ContinueTime "Light Show Continue Time Parameter 2";
CM_ SG_ 839 DwnLoadDynLtgPrmForFrntRIGrp15HighBrightness "Light Show Upper Brightness Parameter 2";
CM_ SG_ 839 DwnLoadDynLtgPrmForFrntRIGrp15LowBrightness "Light Show Lower Brightness Parameter 2";
CM_ SG_ 839 DwnLoadDynLtgPrmForFrntRIGrp15Mode1 "Light Show Mode Parameter 2";
CM_ SG_ 839 DwnLoadDynLtgPrmForFrntRIGrp15OffsetTime "Light Show Offset Time Parameter 2";
CM_ SG_ 839 DwnLoadDynLtgPrmForFrntRIGrp15Timestamp "Light Show time stamp 2";
CM_ SG_ 840 DwnLoadDynLtgPrmForFrntRIGrp16ContinueTime "Light Show Continue Time Parameter 2";
CM_ SG_ 840 DwnLoadDynLtgPrmForFrntRIGrp16HighBrightness "Light Show Upper Brightness Parameter 2";
CM_ SG_ 840 DwnLoadDynLtgPrmForFrntRIGrp16LowBrightness "Light Show Lower Brightness Parameter 2";
CM_ SG_ 840 DwnLoadDynLtgPrmForFrntRIGrp16Mode1 "Light Show Mode Parameter 2";
CM_ SG_ 840 DwnLoadDynLtgPrmForFrntRIGrp16OffsetTime "Light Show Offset Time Parameter 2";
CM_ SG_ 840 DwnLoadDynLtgPrmForFrntRIGrp16Timestamp "Light Show time stamp 2";
CM_ SG_ 841 DwnLoadDynLtgPrmForFrntRIGrp17ContinueTime "Light Show Continue Time Parameter 2";
CM_ SG_ 841 DwnLoadDynLtgPrmForFrntRIGrp17HighBrightness "Light Show Upper Brightness Parameter 2";
CM_ SG_ 841 DwnLoadDynLtgPrmForFrntRIGrp17LowBrightness "Light Show Lower Brightness Parameter 2";
CM_ SG_ 841 DwnLoadDynLtgPrmForFrntRIGrp17Mode1 "Light Show Mode Parameter 2";
CM_ SG_ 841 DwnLoadDynLtgPrmForFrntRIGrp17OffsetTime "Light Show Offset Time Parameter 2";
CM_ SG_ 841 DwnLoadDynLtgPrmForFrntRIGrp17Timestamp "Light Show time stamp 2";
CM_ SG_ 842 DwnLoadDynLtgPrmForFrntRIGrp18ContinueTime "Light Show Continue Time Parameter 2";
CM_ SG_ 842 DwnLoadDynLtgPrmForFrntRIGrp18HighBrightness "Light Show Upper Brightness Parameter 2";
CM_ SG_ 842 DwnLoadDynLtgPrmForFrntRIGrp18LowBrightness "Light Show Lower Brightness Parameter 2";
CM_ SG_ 842 DwnLoadDynLtgPrmForFrntRIGrp18Mode1 "Light Show Mode Parameter 2";
CM_ SG_ 842 DwnLoadDynLtgPrmForFrntRIGrp18OffsetTime "Light Show Offset Time Parameter 2";
CM_ SG_ 842 DwnLoadDynLtgPrmForFrntRIGrp18Timestamp "Light Show time stamp 2";
CM_ SG_ 843 DwnLoadDynLtgPrmForFrntRIGrp19ContinueTime "Light Show Continue Time Parameter 2";
CM_ SG_ 843 DwnLoadDynLtgPrmForFrntRIGrp19HighBrightness "Light Show Upper Brightness Parameter 2";
CM_ SG_ 843 DwnLoadDynLtgPrmForFrntRIGrp19LowBrightness "Light Show Lower Brightness Parameter 2";
CM_ SG_ 843 DwnLoadDynLtgPrmForFrntRIGrp19Mode1 "Light Show Mode Parameter 2";
CM_ SG_ 843 DwnLoadDynLtgPrmForFrntRIGrp19OffsetTime "Light Show Offset Time Parameter 2";
CM_ SG_ 843 DwnLoadDynLtgPrmForFrntRIGrp19Timestamp "Light Show time stamp 2";
CM_ SG_ 844 DwnLoadDynLtgPrmForFrntRIGrp20ContinueTime "Light Show Continue Time Parameter 2";
CM_ SG_ 844 DwnLoadDynLtgPrmForFrntRIGrp20HighBrightness "Light Show Upper Brightness Parameter 2";
CM_ SG_ 844 DwnLoadDynLtgPrmForFrntRIGrp20LowBrightness "Light Show Lower Brightness Parameter 2";
CM_ SG_ 844 DwnLoadDynLtgPrmForFrntRIGrp20Mode1 "Light Show Mode Parameter 2";
CM_ SG_ 844 DwnLoadDynLtgPrmForFrntRIGrp20OffsetTime "Light Show Offset Time Parameter 2";
CM_ SG_ 844 DwnLoadDynLtgPrmForFrntRIGrp20Timestamp "Light Show time stamp 2";
CM_ SG_ 845 DwnLoadDynLtgPrmForFrntRIGrp21ContinueTime "Light Show Continue Time Parameter 2";
CM_ SG_ 845 DwnLoadDynLtgPrmForFrntRIGrp21HighBrightness "Light Show Upper Brightness Parameter 2";
CM_ SG_ 845 DwnLoadDynLtgPrmForFrntRIGrp21LowBrightness "Light Show Lower Brightness Parameter 2";
CM_ SG_ 845 DwnLoadDynLtgPrmForFrntRIGrp21Mode1 "Light Show Mode Parameter 2";
CM_ SG_ 845 DwnLoadDynLtgPrmForFrntRIGrp21OffsetTime "Light Show Offset Time Parameter 2";
CM_ SG_ 845 DwnLoadDynLtgPrmForFrntRIGrp21Timestamp "Light Show time stamp 2";
CM_ SG_ 846 DwnLoadDynLtgPrmForFrntRIGrp22ContinueTime "Light Show Continue Time Parameter 2";
CM_ SG_ 846 DwnLoadDynLtgPrmForFrntRIGrp22HighBrightness "Light Show Upper Brightness Parameter 2";
CM_ SG_ 846 DwnLoadDynLtgPrmForFrntRIGrp22LowBrightness "Light Show Lower Brightness Parameter 2";
CM_ SG_ 846 DwnLoadDynLtgPrmForFrntRIGrp22Mode1 "Light Show Mode Parameter 2";
CM_ SG_ 846 DwnLoadDynLtgPrmForFrntRIGrp22OffsetTime "Light Show Offset Time Parameter 2";
CM_ SG_ 846 DwnLoadDynLtgPrmForFrntRIGrp22Timestamp "Light Show time stamp 2";
CM_ SG_ 847 DwnLoadDynLtgPrmForFrntRIGrp23ContinueTime "Light Show Continue Time Parameter 2";
CM_ SG_ 847 DwnLoadDynLtgPrmForFrntRIGrp23HighBrightness "Light Show Upper Brightness Parameter 2";
CM_ SG_ 847 DwnLoadDynLtgPrmForFrntRIGrp23LowBrightness "Light Show Lower Brightness Parameter 2";
CM_ SG_ 847 DwnLoadDynLtgPrmForFrntRIGrp23Mode1 "Light Show Mode Parameter 2";
CM_ SG_ 847 DwnLoadDynLtgPrmForFrntRIGrp23OffsetTime "Light Show Offset Time Parameter 2";
CM_ SG_ 847 DwnLoadDynLtgPrmForFrntRIGrp23Timestamp "Light Show time stamp 2";
CM_ SG_ 848 DwnLoadDynLtgPrmForFrntRIGrp24ContinueTime "Light Show Continue Time Parameter 2";
CM_ SG_ 848 DwnLoadDynLtgPrmForFrntRIGrp24HighBrightness "Light Show Upper Brightness Parameter 2";
CM_ SG_ 848 DwnLoadDynLtgPrmForFrntRIGrp24LowBrightness "Light Show Lower Brightness Parameter 2";
CM_ SG_ 848 DwnLoadDynLtgPrmForFrntRIGrp24Mode1 "Light Show Mode Parameter 2";
CM_ SG_ 848 DwnLoadDynLtgPrmForFrntRIGrp24OffsetTime "Light Show Offset Time Parameter 2";
CM_ SG_ 848 DwnLoadDynLtgPrmForFrntRIGrp24Timestamp "Light Show time stamp 2";
CM_ SG_ 784 ActvnOfADB "activation of ADB";
CM_ SG_ 784 ActvnOfLiForComity "signal send to actuator to activate dynamic light for comity function";
CM_ SG_ 784 ActvnOfLiForSpkr "signal send to actuator to activate dynamic light for showing speaker";
CM_ SG_ 784 ActvnOfLiForWait "signal send to actuator to activate dynamic light for wait function";
CM_ SG_ 784 LockgCenStsLockSt "Signal LockgCenSts provides central locking status to other subsystems.
Signal is a record with three items
- LockSt (Lock State)
- TrigSrc (Trig Source)
- UpdEve (Will be set to TRUE during one second at each new central locking or unlocking event)";
CM_ SG_ 784 LockgCenStsTrigSrc "Signal LockgCenSts provides central locking status to other subsystems.
Signal is a record with three items
- LockSt (Lock State)
- TrigSrc (Trig Source)
- UpdEve (Will be set to TRUE during one second at each new central locking or unlocking event)";
CM_ SG_ 784 LockgCenStsUpdEve "Signal LockgCenSts provides central locking status to other subsystems.
Signal is a record with three items
- LockSt (Lock State)
- TrigSrc (Trig Source)
- UpdEve (Will be set to TRUE during one second at each new central locking or unlocking event)";
CM_ SG_ 1152 TiAndDateIndcnDataValid "Current time (Hr, Min and Sec) and date (Year, Months and days) data for indication. See requirement for more information about the signals. Signal qualifier, No means values should be ignored.";
CM_ SG_ 1152 TiAndDateIndcnDay "Current time (Hr, Min and Sec) and date (Year, Months and days) data for indication. See requirement for more information about the signals. Day";
CM_ SG_ 1152 TiAndDateIndcnHr1 "Current time (Hr, Min and Sec) and date (Year, Months and days) data for indication. See requirement for more information about the signals. Hour";
CM_ SG_ 1152 TiAndDateIndcnMins1 "Current time (Hr, Min and Sec) and date (Year, Months and days) data for indication. See requirement for more information about the signals. Minutes";
CM_ SG_ 1152 TiAndDateIndcnMth1 "Current time (Hr, Min and Sec) and date (Year, Months and days) data for indication. See requirement for more information about the signals. Month, 1-12";
CM_ SG_ 1152 TiAndDateIndcnSec1 "Current time (Hr, Min and Sec) and date (Year, Months and days) data for indication. See requirement for more information about the signals. Seconds";
CM_ SG_ 1152 TiAndDateIndcnYr1 "Current time (Hr, Min and Sec) and date (Year, Months and days) data for indication. See requirement for more information about the signals. Year, 0-99";
CM_ SG_ 120 CarpetLiModReq "this port is used to inform the exterior light subsystem the user choose which one mode of carpet light.";
CM_ SG_ 120 CarpetLiSwtReq "this port is used to inform exterior light subsystem whether driver want to active carpet light.";
CM_ SG_ 120 CarpetLiTiReq "this port is used to inform the exterior light subsystem the user choose how long of lighting carpet light.";
CM_ SG_ 120 LvlgSwtSetReqChks "this signal is used to set the vertical level of low beam for exterior  light systerm ";
CM_ SG_ 120 LvlgSwtSetReqCntr "this signal is used to set the vertical level of low beam for exterior  light systerm ";
CM_ SG_ 120 LvlgSwtSetReqLvlgSwtSetReq "this signal is used to set the vertical level of low beam for exterior  light systerm ";
CM_ SG_ 120 OutdBriChks "Input for controlling lights on and off automatically. Checksum";
CM_ SG_ 120 OutdBriCntr "Input for controlling lights on and off automatically. Counter";
CM_ SG_ 120 OutdBriSts "Input for controlling lights on and off automatically. Status information.";
CM_ SG_ 381 ActnOfLedFrntCrossLampDyn "Activation of Front Middle Cross Lamp as part of Position Lights with dynamic pattern";
CM_ SG_ 381 ActnOfLedGrilleLampDyn "Activation of Grille Lamp as part of Position Lights with dynamic pattern";
CM_ SG_ 381 ActnOfLedLeLogoLampDyn "Activation of Left Logo Lamp as part of Position Lights with dynamic pattern";
CM_ SG_ 381 ActnOfLedPosnLampDyn "Activation of Led Position Lamp Dynamic mode";
CM_ SG_ 381 ActnOfLedRiLogoLampDyn "Activation of Right Logo Lamp as part of Charging Lights with dynamic pattern";
CM_ SG_ 381 ActvnOfHomeSafe "Activate home safe light function";
CM_ SG_ 381 ActvnOfReLogoLamp1 "Activate rear logo lamp";
CM_ SG_ 612 ActvnOfApproach "to indicate approach light function for dynmaic animation";
CM_ SG_ 612 ActvnOfCarLoctr "to indicate car locate function for dynmaic animation";
CM_ SG_ 612 ActvnOfWaitMode "Activate signal to actuator to implement wait mode animation";
CM_ SG_ 612 BrkPedlValBrkPedlVal "Position of the brake pedal. Physical lower limit: no pedal activation. Physical upper limit: full pedal stroke Brake pedal position";
CM_ SG_ 612 BrkPedlValQf "Position of the brake pedal. Physical lower limit: no pedal activation. Physical upper limit: full pedal stroke Brake pedal sensor quality factor";
CM_ SG_ 612 IndcrNoSeq "to indicate if HWL or DI with sequence";
CM_ SG_ 612 LitArea "Whether the host vehicle is in a lit area";
CM_ SG_ 612 WipgInfoWipgSpdInfo "Information regarding how the wipers are run";
CM_ SG_ 612 WipgInfoWiprActv " 0 No wiping, 1 Wiping";
CM_ SG_ 612 WipgInfoWiprInWipgAr " 0 Wiper in lower reversing area or parked, 1 Wiper in wiping area";
CM_ SG_ 522 ActnOfLedCornrgLampLe "Acitvation of Led Cornering Lamp Left";
CM_ SG_ 522 ActnOfLedCornrgLampRi "Activate LED Cornering Lamp Right.";
CM_ SG_ 522 ActnOfLedDaytiRunngLamp "Activate LED Daytime Running Lamp.";
CM_ SG_ 522 ActnOfLedFrntFogLamp "Activate LED Front Fog Lamp.";
CM_ SG_ 522 ActnOfLedHiBeam "Activate LED High Beam.";
CM_ SG_ 522 ActnOfLedLoBeamActnOfLedLoBeam "Activation of Low Beam function to HCM";
CM_ SG_ 522 ActnOfLedLoBeamChks "Low Beam Check Sum ASIL B";
CM_ SG_ 522 ActnOfLedLoBeamCntr "Low Beam Counter ASIL B";
CM_ SG_ 522 ActnOfLedPosnLamp "Activate LED Position Lamp.";
CM_ SG_ 522 ActnOfLedReFogLamp "Activate LED Rear Fog Lamp.";
CM_ SG_ 522 ActnOfLedRePosnLamp "Activate LED Position Lamp.";
CM_ SG_ 522 ActnOfLedRvsgLamp "Activate LED Revering Lamp.";
CM_ SG_ 522 ActnOfLedStopLampActnOfLedStopLamp "Activation of Stop Lamps by HCM";
CM_ SG_ 522 ActnOfLedStopLampChks "Stop Lamps Check Sum ASIL B";
CM_ SG_ 522 ActnOfLedStopLampCntr "Stop Lamps Counter ASIL B";
CM_ SG_ 522 ActvnOfAfs "Activation of Aaptive Frontlight System ";
CM_ SG_ 522 ActvnOfAhbc "Activate Auto High Beam Control.";
CM_ SG_ 522 ActvnOfAhl "Activate Auto Headlamp Leveling";
CM_ SG_ 522 ActvnOfBrkLi "Activation of Break Light";
CM_ SG_ 522 ActvnOfDbl "Activate Bending Light.";
CM_ SG_ 522 ActvnOfGoodByeLi "Activation Request for Goodbye Light";
CM_ SG_ 522 ActvnOfTouristMod "Activate Tourist Mode.";
CM_ SG_ 522 ActvnOfWelcomeLi "Activation Request for Welcome Light";
CM_ SG_ 538 ActvnOfIndcrIndcrOut "Direction indicator command";
CM_ SG_ 538 ActvnOfIndcrIndcrOutChks "CheckSum";
CM_ SG_ 538 ActvnOfIndcrIndcrOutCntr "Coounter";
CM_ SG_ 538 EmgyBrkLiIndcrTurn "Activation of both rear direction indicators for EBL.";
CM_ SG_ 538 IndcrPatCmd1WdTiOff "Used for Hazard Sleep (subfunction to Hazard Warning Light).

This signal holds the pattern of the flashing to use when buses are asleep and TRM/DCUs shall flash synchronized by themselves.

Holds both on and off timing in two separate record items. HWL Off time";
CM_ SG_ 538 IndcrPatCmd1WdTiOn "Used for Hazard Sleep (subfunction to Hazard Warning Light).

This signal holds the pattern of the flashing to use when buses are asleep and TRM/DCUs shall flash synchronized by themselves.

Holds both on and off timing in two separate record items. HWL On time";
CM_ SG_ 538 IndcrSts "Provides the state and not the event of HWL/Direction Indicator.";
CM_ SG_ 24 DoorDrvrSts "DoorDrvrSts - Driver Door Status
Ukwn - Unknown status
Opend - Opened
Clsd - Closed";
CM_ SG_ 24 DoorLeReSts "DoorLeReSts - Left Rear Side Door Status.
Ukwn - Unknown status
Opend - Opened
Clsd - Closed";
CM_ SG_ 24 HvBattSoc "Actual state of charge of the Hv Battery.";
CM_ SG_ 24 WelcomeGoodbyeModeReq "this port is used to inform the CEM the user choose which one mode of  welcome goodbye  founction.";
CM_ SG_ 801 DwnLoadDynLtgPrmForFrntLeGrp1ContinueTime "Light Show Continue Time Parameter 2";
CM_ SG_ 801 DwnLoadDynLtgPrmForFrntLeGrp1HighBrightness "Light Show Upper Brightness Parameter 2";
CM_ SG_ 801 DwnLoadDynLtgPrmForFrntLeGrp1LowBrightness "Light Show Lower Brightness Parameter 2";
CM_ SG_ 801 DwnLoadDynLtgPrmForFrntLeGrp1Mode1 "Light Show Mode Parameter 2";
CM_ SG_ 801 DwnLoadDynLtgPrmForFrntLeGrp1OffsetTime "Light Show Offset Time Parameter 2";
CM_ SG_ 801 DwnLoadDynLtgPrmForFrntLeGrp1Timestamp "Light Show time stamp 2";
BA_DEF_ BO_ "GenMsgCycleTime" INT 0 65536; // [ms]
BA_DEF_ BO_ "GenMsgDelayTime" INT 0 65536; // [ms]
BA_DEF_ BO_ "GenMsgSendType" ENUM "cyclic", "spontaneous", "not-used", "not-used", "not-used", "cyclicAndSpontaneous", "not-used", "cyclicIfActive", "NoMsgSendType"; // [us]
BA_DEF_ BO_ "GenMsgStartDelayTime" INT 0 65536; // [ms]
BA_DEF_ SG_ "GenSigSendType" ENUM "Cyclic","OnWrite","OnWriteWithRepetition","OnChange","OnChangeWithRepetition","IfActive","IfActiveWithRepetition","NoSigSendType";
BA_DEF_ SG_ "GenSigStartValue" HEX 0 80000000;
BA_DEF_ BO_ "GenMsgILSupport" ENUM "No","Yes";
BA_DEF_ BO_ "NmAsrMessage" ENUM "No","Yes";
BA_DEF_ SG_ "GenSigFuncType" ENUM "NoFunction","n/a","n/a","n/a","n/a","n/a","n/a","n/a","n/a","n/a","n/a","n/a","n/a","n/a","n/a","CHK","CNTR","n/a","n/a","n/a","CNTR_AR_01","CRC_AR_01_BOTH","CRC_AR_01_ALT","CRC_AR_01_LOW","CRC_AR_01_NIBBLE","CNTR_AR_04","CRC_AR_04A","CNTR_AR_05","CRC_AR_05";
BA_DEF_ SG_ "GenSigDataID" STRING;
BA_DEF_DEF_ "GenSigStartValue" 0;
BA_DEF_DEF_ "GenSigSendType" "NoSigSendType";
BA_DEF_DEF_ "GenMsgCycleTime" 0;
BA_DEF_DEF_ "GenMsgDelayTime" 0;
BA_DEF_DEF_ "GenMsgStartDelayTime" 0;
BA_DEF_DEF_ "GenMsgSendType" "NoMsgSendType";
BA_DEF_DEF_ "GenMsgILSupport" "Yes";
BA_DEF_DEF_ "NmAsrMessage" "No";
BA_DEF_DEF_ "GenSigFuncType" "NoFunction";
BA_DEF_DEF_ "GenSigDataID" "";
// Frame: ZCUDBodyExpoFr01
BA_ "GenMsgCycleTime" BO_ 82 10.000;
BA_ "GenMsgSendType" BO_ 82 0;
// Frame: ZCUDBodyExpoFr02
BA_ "GenMsgCycleTime" BO_ 768 45.000;
BA_ "GenMsgSendType" BO_ 768 0;
// Frame: ZCUDBodyExpoFr03
BA_ "GenMsgCycleTime" BO_ 80 40.000;
BA_ "GenMsgSendType" BO_ 80 0;
// Frame: ZCUDBodyExpoFr04
BA_ "GenMsgDelayTime" BO_ 384 120.000;
BA_ "GenMsgSendType" BO_ 384 1;
// Frame: ZCUDBodyExpoFr05
BA_ "GenMsgCycleTime" BO_ 512 50.000;
BA_ "GenMsgSendType" BO_ 512 0;
// Frame: ZCUDBodyExpoFr06
BA_ "GenMsgCycleTime" BO_ 544 60.000;
BA_ "GenMsgDelayTime" BO_ 544 10.000;
BA_ "GenMsgSendType" BO_ 544 5;
// Frame: ZCUDBodyExpoFr07
BA_ "GenMsgCycleTime" BO_ 128 20.000;
BA_ "GenMsgSendType" BO_ 128 0;
// Frame: ZCUDBodyExpoFr08
BA_ "GenMsgDelayTime" BO_ 387 120.000;
BA_ "GenMsgSendType" BO_ 387 1;
// Frame: ZCUDBodyExpoFr09
BA_ "GenMsgCycleTime" BO_ 389 45.000;
BA_ "GenMsgDelayTime" BO_ 389 10.000;
BA_ "GenMsgSendType" BO_ 389 5;
// Frame: ZCUDBodyExpoFr10
BA_ "GenMsgCycleTime" BO_ 390 45.000;
BA_ "GenMsgSendType" BO_ 390 0;
// Frame: ZCUDBodyExpoFr11
BA_ "GenMsgCycleTime" BO_ 391 45.000;
BA_ "GenMsgSendType" BO_ 391 0;
// Frame: ZCUDBodyExpoFr12
BA_ "GenMsgCycleTime" BO_ 392 45.000;
BA_ "GenMsgSendType" BO_ 392 0;
// Frame: ZCUDBodyExpoFr13
BA_ "GenMsgCycleTime" BO_ 393 45.000;
BA_ "GenMsgSendType" BO_ 393 0;
// Frame: ZCUDBodyExpoFr14
BA_ "GenMsgCycleTime" BO_ 394 45.000;
BA_ "GenMsgSendType" BO_ 394 0;
// Frame: ZCUDBodyExpoFr15
BA_ "GenMsgCycleTime" BO_ 395 45.000;
BA_ "GenMsgSendType" BO_ 395 0;
// Frame: ZCUDBodyExpoFr16
BA_ "GenMsgCycleTime" BO_ 396 45.000;
BA_ "GenMsgSendType" BO_ 396 0;
// Frame: ZCUDBodyExpoFr17
BA_ "GenMsgCycleTime" BO_ 397 45.000;
BA_ "GenMsgSendType" BO_ 397 0;
// Frame: ZCUDBodyExpoFr18
BA_ "GenMsgCycleTime" BO_ 398 45.000;
BA_ "GenMsgSendType" BO_ 398 0;
// Frame: ZCUDBodyExpoFr19
BA_ "GenMsgCycleTime" BO_ 399 45.000;
BA_ "GenMsgSendType" BO_ 399 0;
// Frame: ZCUDBodyExpoFr20
BA_ "GenMsgCycleTime" BO_ 64 15.000;
BA_ "GenMsgSendType" BO_ 64 0;
// Frame: ZCUDBodyExpoFr21
BA_ "GenMsgCycleTime" BO_ 400 45.000;
BA_ "GenMsgSendType" BO_ 400 0;
// Frame: ZCUDBodyExpoFr22
BA_ "GenMsgDelayTime" BO_ 28 30.000;
BA_ "GenMsgSendType" BO_ 28 1;
// Frame: ZCUDBodyExpoFr23
BA_ "GenMsgDelayTime" BO_ 834 30.000;
BA_ "GenMsgSendType" BO_ 834 1;
// Frame: ZCUDBodyExpoFr24
BA_ "GenMsgDelayTime" BO_ 835 30.000;
BA_ "GenMsgSendType" BO_ 835 1;
// Frame: ZCUDBodyExpoFr25
BA_ "GenMsgDelayTime" BO_ 836 30.000;
BA_ "GenMsgSendType" BO_ 836 1;
// Frame: ZCUDBodyExpoFr26
BA_ "GenMsgDelayTime" BO_ 837 30.000;
BA_ "GenMsgSendType" BO_ 837 1;
// Frame: ZCUDBodyExpoFr27
BA_ "GenMsgDelayTime" BO_ 838 30.000;
BA_ "GenMsgSendType" BO_ 838 1;
// Frame: ZCUDBodyExpoFr28
BA_ "GenMsgDelayTime" BO_ 839 30.000;
BA_ "GenMsgSendType" BO_ 839 1;
// Frame: ZCUDBodyExpoFr29
BA_ "GenMsgDelayTime" BO_ 840 30.000;
BA_ "GenMsgSendType" BO_ 840 1;
// Frame: ZCUDBodyExpoFr30
BA_ "GenMsgDelayTime" BO_ 841 30.000;
BA_ "GenMsgSendType" BO_ 841 1;
// Frame: ZCUDBodyExpoFr31
BA_ "GenMsgDelayTime" BO_ 842 30.000;
BA_ "GenMsgSendType" BO_ 842 1;
// Frame: ZCUDBodyExpoFr32
BA_ "GenMsgDelayTime" BO_ 843 30.000;
BA_ "GenMsgSendType" BO_ 843 1;
// Frame: ZCUDBodyExpoFr33
BA_ "GenMsgDelayTime" BO_ 844 30.000;
BA_ "GenMsgSendType" BO_ 844 1;
// Frame: ZCUDBodyExpoFr34
BA_ "GenMsgDelayTime" BO_ 845 30.000;
BA_ "GenMsgSendType" BO_ 845 1;
// Frame: ZCUDBodyExpoFr35
BA_ "GenMsgDelayTime" BO_ 846 30.000;
BA_ "GenMsgSendType" BO_ 846 1;
// Frame: ZCUDBodyExpoFr36
BA_ "GenMsgDelayTime" BO_ 847 30.000;
BA_ "GenMsgSendType" BO_ 847 1;
// Frame: ZCUDBodyExpoFr37
BA_ "GenMsgDelayTime" BO_ 848 30.000;
BA_ "GenMsgSendType" BO_ 848 1;
// Frame: ZCUDBodyExpoFr38
BA_ "GenMsgCycleTime" BO_ 784 100.000;
BA_ "GenMsgSendType" BO_ 784 0;
// Frame: ZCUDBodyExpoFr39
BA_ "GenMsgCycleTime" BO_ 1152 1000.000;
BA_ "GenMsgSendType" BO_ 1152 0;
// Frame: ZCUDBodyExpoFr40
BA_ "GenMsgCycleTime" BO_ 120 25.000;
BA_ "GenMsgSendType" BO_ 120 0;
// Frame: ZCUDBodyExpoFr41
BA_ "GenMsgCycleTime" BO_ 381 65.000;
BA_ "GenMsgDelayTime" BO_ 381 10.000;
BA_ "GenMsgSendType" BO_ 381 5;
// Frame: ZCUDBodyExpoFr42
BA_ "GenMsgCycleTime" BO_ 612 65.000;
BA_ "GenMsgDelayTime" BO_ 612 10.000;
BA_ "GenMsgSendType" BO_ 612 5;
// Frame: ZCUDBodyExpoFr43
BA_ "GenMsgCycleTime" BO_ 522 50.000;
BA_ "GenMsgDelayTime" BO_ 522 10.000;
BA_ "GenMsgSendType" BO_ 522 5;
// Frame: ZCUDBodyExpoFr44
BA_ "GenMsgCycleTime" BO_ 538 20.000;
BA_ "GenMsgSendType" BO_ 538 0;
// Frame: ZCUDBodyExpoFr45
BA_ "GenMsgCycleTime" BO_ 24 15.000;
BA_ "GenMsgSendType" BO_ 24 0;
// Frame: ZCUDBodyExpoFr46
BA_ "GenMsgDelayTime" BO_ 801 25.000;
BA_ "GenMsgSendType" BO_ 801 1;
BA_ "GenSigSendType" SG_ 128 AccrPedlRatAccrPedlRat 0;
BA_ "GenSigDataID" SG_ 128 AccrPedlRatChks "0x364";
BA_ "GenSigFuncType" SG_ 128 AccrPedlRatChks 15;
BA_ "GenSigSendType" SG_ 128 AccrPedlRatChks 0;
BA_ "GenSigFuncType" SG_ 128 AccrPedlRatCntr 16;
BA_ "GenSigSendType" SG_ 128 AccrPedlRatCntr 0;
BA_ "GenSigSendType" SG_ 64 ActnOfAssistantLi 0;
BA_ "GenSigSendType" SG_ 522 ActnOfLedCornrgLampLe 0;
BA_ "GenSigSendType" SG_ 522 ActnOfLedCornrgLampRi 0;
BA_ "GenSigSendType" SG_ 522 ActnOfLedDaytiRunngLamp 0;
BA_ "GenSigSendType" SG_ 544 ActnOfLedFrntCrossLamp 0;
BA_ "GenSigSendType" SG_ 381 ActnOfLedFrntCrossLampDyn 0;
BA_ "GenSigSendType" SG_ 522 ActnOfLedFrntFogLamp 0;
BA_ "GenSigSendType" SG_ 544 ActnOfLedGrilleLamp 0;
BA_ "GenSigSendType" SG_ 381 ActnOfLedGrilleLampDyn 0;
BA_ "GenSigSendType" SG_ 522 ActnOfLedHiBeam 0;
BA_ "GenSigSendType" SG_ 544 ActnOfLedLeLogoLamp 0;
BA_ "GenSigSendType" SG_ 381 ActnOfLedLeLogoLampDyn 0;
BA_ "GenSigSendType" SG_ 522 ActnOfLedLoBeamActnOfLedLoBeam 0;
BA_ "GenSigDataID" SG_ 522 ActnOfLedLoBeamChks "0x441";
BA_ "GenSigFuncType" SG_ 522 ActnOfLedLoBeamChks 15;
BA_ "GenSigSendType" SG_ 522 ActnOfLedLoBeamChks 0;
BA_ "GenSigFuncType" SG_ 522 ActnOfLedLoBeamCntr 16;
BA_ "GenSigSendType" SG_ 522 ActnOfLedLoBeamCntr 0;
BA_ "GenSigSendType" SG_ 522 ActnOfLedPosnLamp 0;
BA_ "GenSigSendType" SG_ 381 ActnOfLedPosnLampDyn 0;
BA_ "GenSigSendType" SG_ 522 ActnOfLedReFogLamp 0;
BA_ "GenSigSendType" SG_ 522 ActnOfLedRePosnLamp 0;
BA_ "GenSigSendType" SG_ 544 ActnOfLedRiLogoLamp 0;
BA_ "GenSigSendType" SG_ 381 ActnOfLedRiLogoLampDyn 0;
BA_ "GenSigSendType" SG_ 522 ActnOfLedRvsgLamp 0;
BA_ "GenSigSendType" SG_ 522 ActnOfLedStopLampActnOfLedStopLamp 0;
BA_ "GenSigDataID" SG_ 522 ActnOfLedStopLampChks "0x443";
BA_ "GenSigFuncType" SG_ 522 ActnOfLedStopLampChks 15;
BA_ "GenSigSendType" SG_ 522 ActnOfLedStopLampChks 0;
BA_ "GenSigFuncType" SG_ 522 ActnOfLedStopLampCntr 16;
BA_ "GenSigSendType" SG_ 522 ActnOfLedStopLampCntr 0;
BA_ "GenSigSendType" SG_ 784 ActvnOfADB 0;
BA_ "GenSigSendType" SG_ 522 ActvnOfAfs 0;
BA_ "GenSigSendType" SG_ 522 ActvnOfAhbc 0;
BA_ "GenSigSendType" SG_ 522 ActvnOfAhl 0;
BA_ "GenSigSendType" SG_ 612 ActvnOfApproach 0;
BA_ "GenSigSendType" SG_ 522 ActvnOfBrkLi 0;
BA_ "GenSigSendType" SG_ 612 ActvnOfCarLoctr 0;
BA_ "GenSigSendType" SG_ 522 ActvnOfDbl 0;
BA_ "GenSigSendType" SG_ 82 ActvnOfDefdLiShow 0;
BA_ "GenSigSendType" SG_ 522 ActvnOfGoodByeLi 0;
BA_ "GenSigSendType" SG_ 381 ActvnOfHomeSafe 0;
BA_ "GenSigSendType" SG_ 538 ActvnOfIndcrIndcrOut 0;
BA_ "GenSigDataID" SG_ 538 ActvnOfIndcrIndcrOutChks "0x9E";
BA_ "GenSigFuncType" SG_ 538 ActvnOfIndcrIndcrOutChks 15;
BA_ "GenSigSendType" SG_ 538 ActvnOfIndcrIndcrOutChks 0;
BA_ "GenSigFuncType" SG_ 538 ActvnOfIndcrIndcrOutCntr 16;
BA_ "GenSigSendType" SG_ 538 ActvnOfIndcrIndcrOutCntr 0;
BA_ "GenSigSendType" SG_ 784 ActvnOfLiForComity 0;
BA_ "GenSigSendType" SG_ 784 ActvnOfLiForSpkr 0;
BA_ "GenSigSendType" SG_ 784 ActvnOfLiForWait 0;
BA_ "GenSigSendType" SG_ 82 ActvnOfMusicShowforEITL 0;
BA_ "GenSigSendType" SG_ 381 ActvnOfReLogoLamp1 0;
BA_ "GenSigSendType" SG_ 768 ActvnOfRvsg 0;
BA_ "GenSigSendType" SG_ 389 ActvnOfShowModLi 0;
BA_ "GenSigSendType" SG_ 522 ActvnOfTouristMod 0;
BA_ "GenSigSendType" SG_ 612 ActvnOfWaitMode 0;
BA_ "GenSigSendType" SG_ 522 ActvnOfWelcomeLi 0;
BA_ "GenSigSendType" SG_ 128 AmbTRawAmbTVal 0;
BA_ "GenSigStartValue" SG_ 128 AmbTRawAmbTVal 700;
BA_ "GenSigSendType" SG_ 128 AmbTRawQly 0;
BA_ "GenSigSendType" SG_ 82 AutWinWipgCmd 0;
BA_ "GenSigSendType" SG_ 512 BkpOfDstTrvld 0;
BA_ "GenSigSendType" SG_ 544 Body2CntrForMissCom 0;
BA_ "GenSigDataID" SG_ 128 BrkPedlSnsrChks "0xAF";
BA_ "GenSigFuncType" SG_ 128 BrkPedlSnsrChks 15;
BA_ "GenSigSendType" SG_ 128 BrkPedlSnsrChks 0;
BA_ "GenSigFuncType" SG_ 128 BrkPedlSnsrCntr 16;
BA_ "GenSigSendType" SG_ 128 BrkPedlSnsrCntr 0;
BA_ "GenSigSendType" SG_ 128 BrkPedlSnsrQf 0;
BA_ "GenSigSendType" SG_ 128 BrkPedlSnsrSt 0;
BA_ "GenSigSendType" SG_ 612 BrkPedlValBrkPedlVal 0;
BA_ "GenSigSendType" SG_ 612 BrkPedlValQf 0;
BA_ "GenSigStartValue" SG_ 612 BrkPedlValQf 1;
BA_ "GenSigSendType" SG_ 768 BrkPedlrRatPerc 0;
BA_ "GenSigSendType" SG_ 768 BrkPedlrRatQf 0;
BA_ "GenSigSendType" SG_ 64 CameraStsforAHBC 0;
BA_ "GenSigSendType" SG_ 544 CarTiGlb 0;
BA_ "GenSigSendType" SG_ 120 CarpetLiModReq 0;
BA_ "GenSigSendType" SG_ 120 CarpetLiSwtReq 0;
BA_ "GenSigSendType" SG_ 120 CarpetLiTiReq 0;
BA_ "GenSigSendType" SG_ 24 DoorDrvrSts 0;
BA_ "GenSigSendType" SG_ 24 DoorLeReSts 0;
BA_ "GenSigSendType" SG_ 80 DoorPassSts 0;
BA_ "GenSigSendType" SG_ 80 DoorRiReSts 0;
BA_ "GenSigSendType" SG_ 801 DwnLoadDynLtgPrmForFrntLeGrp1ContinueTime 1;
BA_ "GenSigSendType" SG_ 801 DwnLoadDynLtgPrmForFrntLeGrp1HighBrightness 1;
BA_ "GenSigSendType" SG_ 801 DwnLoadDynLtgPrmForFrntLeGrp1LowBrightness 1;
BA_ "GenSigSendType" SG_ 801 DwnLoadDynLtgPrmForFrntLeGrp1Mode1 1;
BA_ "GenSigSendType" SG_ 801 DwnLoadDynLtgPrmForFrntLeGrp1OffsetTime 1;
BA_ "GenSigSendType" SG_ 801 DwnLoadDynLtgPrmForFrntLeGrp1Timestamp 1;
BA_ "GenSigSendType" SG_ 834 DwnLoadDynLtgPrmForFrntRIGrp10ContinueTime 1;
BA_ "GenSigSendType" SG_ 834 DwnLoadDynLtgPrmForFrntRIGrp10HighBrightness 1;
BA_ "GenSigSendType" SG_ 834 DwnLoadDynLtgPrmForFrntRIGrp10LowBrightness 1;
BA_ "GenSigSendType" SG_ 834 DwnLoadDynLtgPrmForFrntRIGrp10Mode1 1;
BA_ "GenSigSendType" SG_ 834 DwnLoadDynLtgPrmForFrntRIGrp10OffsetTime 1;
BA_ "GenSigSendType" SG_ 834 DwnLoadDynLtgPrmForFrntRIGrp10Timestamp 1;
BA_ "GenSigSendType" SG_ 835 DwnLoadDynLtgPrmForFrntRIGrp11ContinueTime 1;
BA_ "GenSigSendType" SG_ 835 DwnLoadDynLtgPrmForFrntRIGrp11HighBrightness 1;
BA_ "GenSigSendType" SG_ 835 DwnLoadDynLtgPrmForFrntRIGrp11LowBrightness 1;
BA_ "GenSigSendType" SG_ 835 DwnLoadDynLtgPrmForFrntRIGrp11Mode1 1;
BA_ "GenSigSendType" SG_ 835 DwnLoadDynLtgPrmForFrntRIGrp11OffsetTime 1;
BA_ "GenSigSendType" SG_ 835 DwnLoadDynLtgPrmForFrntRIGrp11Timestamp 1;
BA_ "GenSigSendType" SG_ 836 DwnLoadDynLtgPrmForFrntRIGrp12ContinueTime 1;
BA_ "GenSigSendType" SG_ 836 DwnLoadDynLtgPrmForFrntRIGrp12HighBrightness 1;
BA_ "GenSigSendType" SG_ 836 DwnLoadDynLtgPrmForFrntRIGrp12LowBrightness 1;
BA_ "GenSigSendType" SG_ 836 DwnLoadDynLtgPrmForFrntRIGrp12Mode1 1;
BA_ "GenSigSendType" SG_ 836 DwnLoadDynLtgPrmForFrntRIGrp12OffsetTime 1;
BA_ "GenSigSendType" SG_ 836 DwnLoadDynLtgPrmForFrntRIGrp12Timestamp 1;
BA_ "GenSigSendType" SG_ 837 DwnLoadDynLtgPrmForFrntRIGrp13ContinueTime 1;
BA_ "GenSigSendType" SG_ 837 DwnLoadDynLtgPrmForFrntRIGrp13HighBrightness 1;
BA_ "GenSigSendType" SG_ 837 DwnLoadDynLtgPrmForFrntRIGrp13LowBrightness 1;
BA_ "GenSigSendType" SG_ 837 DwnLoadDynLtgPrmForFrntRIGrp13Mode1 1;
BA_ "GenSigSendType" SG_ 837 DwnLoadDynLtgPrmForFrntRIGrp13OffsetTime 1;
BA_ "GenSigSendType" SG_ 837 DwnLoadDynLtgPrmForFrntRIGrp13Timestamp 1;
BA_ "GenSigSendType" SG_ 838 DwnLoadDynLtgPrmForFrntRIGrp14ContinueTime 1;
BA_ "GenSigSendType" SG_ 838 DwnLoadDynLtgPrmForFrntRIGrp14HighBrightness 1;
BA_ "GenSigSendType" SG_ 838 DwnLoadDynLtgPrmForFrntRIGrp14LowBrightness 1;
BA_ "GenSigSendType" SG_ 838 DwnLoadDynLtgPrmForFrntRIGrp14Mode1 1;
BA_ "GenSigSendType" SG_ 838 DwnLoadDynLtgPrmForFrntRIGrp14OffsetTime 1;
BA_ "GenSigSendType" SG_ 838 DwnLoadDynLtgPrmForFrntRIGrp14Timestamp 1;
BA_ "GenSigSendType" SG_ 839 DwnLoadDynLtgPrmForFrntRIGrp15ContinueTime 1;
BA_ "GenSigSendType" SG_ 839 DwnLoadDynLtgPrmForFrntRIGrp15HighBrightness 1;
BA_ "GenSigSendType" SG_ 839 DwnLoadDynLtgPrmForFrntRIGrp15LowBrightness 1;
BA_ "GenSigSendType" SG_ 839 DwnLoadDynLtgPrmForFrntRIGrp15Mode1 1;
BA_ "GenSigSendType" SG_ 839 DwnLoadDynLtgPrmForFrntRIGrp15OffsetTime 1;
BA_ "GenSigSendType" SG_ 839 DwnLoadDynLtgPrmForFrntRIGrp15Timestamp 1;
BA_ "GenSigSendType" SG_ 840 DwnLoadDynLtgPrmForFrntRIGrp16ContinueTime 1;
BA_ "GenSigSendType" SG_ 840 DwnLoadDynLtgPrmForFrntRIGrp16HighBrightness 1;
BA_ "GenSigSendType" SG_ 840 DwnLoadDynLtgPrmForFrntRIGrp16LowBrightness 1;
BA_ "GenSigSendType" SG_ 840 DwnLoadDynLtgPrmForFrntRIGrp16Mode1 1;
BA_ "GenSigSendType" SG_ 840 DwnLoadDynLtgPrmForFrntRIGrp16OffsetTime 1;
BA_ "GenSigSendType" SG_ 840 DwnLoadDynLtgPrmForFrntRIGrp16Timestamp 1;
BA_ "GenSigSendType" SG_ 841 DwnLoadDynLtgPrmForFrntRIGrp17ContinueTime 1;
BA_ "GenSigSendType" SG_ 841 DwnLoadDynLtgPrmForFrntRIGrp17HighBrightness 1;
BA_ "GenSigSendType" SG_ 841 DwnLoadDynLtgPrmForFrntRIGrp17LowBrightness 1;
BA_ "GenSigSendType" SG_ 841 DwnLoadDynLtgPrmForFrntRIGrp17Mode1 1;
BA_ "GenSigSendType" SG_ 841 DwnLoadDynLtgPrmForFrntRIGrp17OffsetTime 1;
BA_ "GenSigSendType" SG_ 841 DwnLoadDynLtgPrmForFrntRIGrp17Timestamp 1;
BA_ "GenSigSendType" SG_ 842 DwnLoadDynLtgPrmForFrntRIGrp18ContinueTime 1;
BA_ "GenSigSendType" SG_ 842 DwnLoadDynLtgPrmForFrntRIGrp18HighBrightness 1;
BA_ "GenSigSendType" SG_ 842 DwnLoadDynLtgPrmForFrntRIGrp18LowBrightness 1;
BA_ "GenSigSendType" SG_ 842 DwnLoadDynLtgPrmForFrntRIGrp18Mode1 1;
BA_ "GenSigSendType" SG_ 842 DwnLoadDynLtgPrmForFrntRIGrp18OffsetTime 1;
BA_ "GenSigSendType" SG_ 842 DwnLoadDynLtgPrmForFrntRIGrp18Timestamp 1;
BA_ "GenSigSendType" SG_ 843 DwnLoadDynLtgPrmForFrntRIGrp19ContinueTime 1;
BA_ "GenSigSendType" SG_ 843 DwnLoadDynLtgPrmForFrntRIGrp19HighBrightness 1;
BA_ "GenSigSendType" SG_ 843 DwnLoadDynLtgPrmForFrntRIGrp19LowBrightness 1;
BA_ "GenSigSendType" SG_ 843 DwnLoadDynLtgPrmForFrntRIGrp19Mode1 1;
BA_ "GenSigSendType" SG_ 843 DwnLoadDynLtgPrmForFrntRIGrp19OffsetTime 1;
BA_ "GenSigSendType" SG_ 843 DwnLoadDynLtgPrmForFrntRIGrp19Timestamp 1;
BA_ "GenSigSendType" SG_ 844 DwnLoadDynLtgPrmForFrntRIGrp20ContinueTime 1;
BA_ "GenSigSendType" SG_ 844 DwnLoadDynLtgPrmForFrntRIGrp20HighBrightness 1;
BA_ "GenSigSendType" SG_ 844 DwnLoadDynLtgPrmForFrntRIGrp20LowBrightness 1;
BA_ "GenSigSendType" SG_ 844 DwnLoadDynLtgPrmForFrntRIGrp20Mode1 1;
BA_ "GenSigSendType" SG_ 844 DwnLoadDynLtgPrmForFrntRIGrp20OffsetTime 1;
BA_ "GenSigSendType" SG_ 844 DwnLoadDynLtgPrmForFrntRIGrp20Timestamp 1;
BA_ "GenSigSendType" SG_ 845 DwnLoadDynLtgPrmForFrntRIGrp21ContinueTime 1;
BA_ "GenSigSendType" SG_ 845 DwnLoadDynLtgPrmForFrntRIGrp21HighBrightness 1;
BA_ "GenSigSendType" SG_ 845 DwnLoadDynLtgPrmForFrntRIGrp21LowBrightness 1;
BA_ "GenSigSendType" SG_ 845 DwnLoadDynLtgPrmForFrntRIGrp21Mode1 1;
BA_ "GenSigSendType" SG_ 845 DwnLoadDynLtgPrmForFrntRIGrp21OffsetTime 1;
BA_ "GenSigSendType" SG_ 845 DwnLoadDynLtgPrmForFrntRIGrp21Timestamp 1;
BA_ "GenSigSendType" SG_ 846 DwnLoadDynLtgPrmForFrntRIGrp22ContinueTime 1;
BA_ "GenSigSendType" SG_ 846 DwnLoadDynLtgPrmForFrntRIGrp22HighBrightness 1;
BA_ "GenSigSendType" SG_ 846 DwnLoadDynLtgPrmForFrntRIGrp22LowBrightness 1;
BA_ "GenSigSendType" SG_ 846 DwnLoadDynLtgPrmForFrntRIGrp22Mode1 1;
BA_ "GenSigSendType" SG_ 846 DwnLoadDynLtgPrmForFrntRIGrp22OffsetTime 1;
BA_ "GenSigSendType" SG_ 846 DwnLoadDynLtgPrmForFrntRIGrp22Timestamp 1;
BA_ "GenSigSendType" SG_ 847 DwnLoadDynLtgPrmForFrntRIGrp23ContinueTime 1;
BA_ "GenSigSendType" SG_ 847 DwnLoadDynLtgPrmForFrntRIGrp23HighBrightness 1;
BA_ "GenSigSendType" SG_ 847 DwnLoadDynLtgPrmForFrntRIGrp23LowBrightness 1;
BA_ "GenSigSendType" SG_ 847 DwnLoadDynLtgPrmForFrntRIGrp23Mode1 1;
BA_ "GenSigSendType" SG_ 847 DwnLoadDynLtgPrmForFrntRIGrp23OffsetTime 1;
BA_ "GenSigSendType" SG_ 847 DwnLoadDynLtgPrmForFrntRIGrp23Timestamp 1;
BA_ "GenSigSendType" SG_ 848 DwnLoadDynLtgPrmForFrntRIGrp24ContinueTime 1;
BA_ "GenSigSendType" SG_ 848 DwnLoadDynLtgPrmForFrntRIGrp24HighBrightness 1;
BA_ "GenSigSendType" SG_ 848 DwnLoadDynLtgPrmForFrntRIGrp24LowBrightness 1;
BA_ "GenSigSendType" SG_ 848 DwnLoadDynLtgPrmForFrntRIGrp24Mode1 1;
BA_ "GenSigSendType" SG_ 848 DwnLoadDynLtgPrmForFrntRIGrp24OffsetTime 1;
BA_ "GenSigSendType" SG_ 848 DwnLoadDynLtgPrmForFrntRIGrp24Timestamp 1;
BA_ "GenSigSendType" SG_ 538 EmgyBrkLiIndcrTurn 0;
BA_ "GenSigStartValue" SG_ 538 EmgyBrkLiIndcrTurn 1;
BA_ "GenSigSendType" SG_ 512 ExtrLiRlyPwrDwn 0;
BA_ "GenSigSendType" SG_ 28 ExtrLiShowActvnReq 1;
BA_ "GenSigSendType" SG_ 28 ExtrLiShowFileTxReq 1;
BA_ "GenSigSendType" SG_ 24 HvBattSoc 0;
BA_ "GenSigSendType" SG_ 612 IndcrNoSeq 0;
BA_ "GenSigSendType" SG_ 538 IndcrPatCmd1WdTiOff 0;
BA_ "GenSigSendType" SG_ 538 IndcrPatCmd1WdTiOn 0;
BA_ "GenSigSendType" SG_ 538 IndcrSts 0;
BA_ "GenSigSendType" SG_ 82 LiOprnMod 0;
BA_ "GenSigSendType" SG_ 612 LitArea 0;
BA_ "GenSigSendType" SG_ 784 LockgCenStsLockSt 0;
BA_ "GenSigSendType" SG_ 784 LockgCenStsTrigSrc 0;
BA_ "GenSigSendType" SG_ 784 LockgCenStsUpdEve 0;
BA_ "GenSigSendType" SG_ 120 LvlgSwtSetReqChks 0;
BA_ "GenSigSendType" SG_ 120 LvlgSwtSetReqCntr 0;
BA_ "GenSigSendType" SG_ 120 LvlgSwtSetReqLvlgSwtSetReq 0;
BA_ "GenSigSendType" SG_ 82 MusicShowPlaySts 0;
BA_ "GenSigDataID" SG_ 120 OutdBriChks "0x1F42";
BA_ "GenSigFuncType" SG_ 120 OutdBriChks 15;
BA_ "GenSigSendType" SG_ 120 OutdBriChks 0;
BA_ "GenSigFuncType" SG_ 120 OutdBriCntr 16;
BA_ "GenSigSendType" SG_ 120 OutdBriCntr 0;
BA_ "GenSigSendType" SG_ 120 OutdBriSts 0;
BA_ "GenSigSendType" SG_ 64 RainLi 0;
BA_ "GenSigSendType" SG_ 82 SteerWhlSnsrAg 0;
BA_ "GenSigSendType" SG_ 82 SteerWhlSnsrAgSpd 0;
BA_ "GenSigDataID" SG_ 82 SteerWhlSnsrChks "0x33";
BA_ "GenSigFuncType" SG_ 82 SteerWhlSnsrChks 15;
BA_ "GenSigSendType" SG_ 82 SteerWhlSnsrChks 0;
BA_ "GenSigFuncType" SG_ 82 SteerWhlSnsrCntr 16;
BA_ "GenSigSendType" SG_ 82 SteerWhlSnsrCntr 0;
BA_ "GenSigSendType" SG_ 82 SteerWhlSnsrQf 0;
BA_ "GenSigStartValue" SG_ 82 SteerWhlSnsrQf 1;
BA_ "GenSigSendType" SG_ 400 SuspPosnVertAgGenQf 0;
BA_ "GenSigStartValue" SG_ 400 SuspPosnVertAgGenQf 1;
BA_ "GenSigSendType" SG_ 400 SuspPosnVertAgSuspPosnVertAg 0;
BA_ "GenSigSendType" SG_ 400 SuspPosnVertLvlFrnt 0;
BA_ "GenSigSendType" SG_ 400 SuspPosnVertLvlFrntQf 0;
BA_ "GenSigSendType" SG_ 400 SuspPosnVertLvlRe 0;
BA_ "GenSigSendType" SG_ 400 SuspPosnVertLvlReQf 0;
BA_ "GenSigSendType" SG_ 1152 TiAndDateIndcnDataValid 0;
BA_ "GenSigSendType" SG_ 1152 TiAndDateIndcnDay 0;
BA_ "GenSigStartValue" SG_ 1152 TiAndDateIndcnDay 1;
BA_ "GenSigSendType" SG_ 1152 TiAndDateIndcnHr1 0;
BA_ "GenSigSendType" SG_ 1152 TiAndDateIndcnMins1 0;
BA_ "GenSigSendType" SG_ 1152 TiAndDateIndcnMth1 0;
BA_ "GenSigStartValue" SG_ 1152 TiAndDateIndcnMth1 1;
BA_ "GenSigSendType" SG_ 1152 TiAndDateIndcnSec1 0;
BA_ "GenSigSendType" SG_ 1152 TiAndDateIndcnYr1 0;
BA_ "GenSigSendType" SG_ 128 TooManyCars 0;
BA_ "GenSigSendType" SG_ 544 TrSts 0;
BA_ "GenSigSendType" SG_ 389 TrafficSignForADB1AdbAbsDist 0;
BA_ "GenSigSendType" SG_ 389 TrafficSignForADB1AdbDetdQly 0;
BA_ "GenSigSendType" SG_ 389 TrafficSignForADB1AdbHozlAgLe 0;
BA_ "GenSigStartValue" SG_ 389 TrafficSignForADB1AdbHozlAgLe 800;
BA_ "GenSigSendType" SG_ 389 TrafficSignForADB1AdbHozlAgRi 0;
BA_ "GenSigStartValue" SG_ 389 TrafficSignForADB1AdbHozlAgRi 800;
BA_ "GenSigSendType" SG_ 389 TrafficSignForADB1AdbTrkInfo 0;
BA_ "GenSigSendType" SG_ 389 TrafficSignForADB1AdbVertAgBot 0;
BA_ "GenSigStartValue" SG_ 389 TrafficSignForADB1AdbVertAgBot 60;
BA_ "GenSigSendType" SG_ 389 TrafficSignForADB1AdbVertAgTop 0;
BA_ "GenSigStartValue" SG_ 389 TrafficSignForADB1AdbVertAgTop 60;
BA_ "GenSigSendType" SG_ 390 TrafficSignForADB2AdbAbsDist 0;
BA_ "GenSigSendType" SG_ 390 TrafficSignForADB2AdbDetdQly 0;
BA_ "GenSigSendType" SG_ 390 TrafficSignForADB2AdbHozlAgLe 0;
BA_ "GenSigStartValue" SG_ 390 TrafficSignForADB2AdbHozlAgLe 800;
BA_ "GenSigSendType" SG_ 390 TrafficSignForADB2AdbHozlAgRi 0;
BA_ "GenSigStartValue" SG_ 390 TrafficSignForADB2AdbHozlAgRi 800;
BA_ "GenSigSendType" SG_ 390 TrafficSignForADB2AdbTrkInfo 0;
BA_ "GenSigSendType" SG_ 390 TrafficSignForADB2AdbVertAgBot 0;
BA_ "GenSigStartValue" SG_ 390 TrafficSignForADB2AdbVertAgBot 60;
BA_ "GenSigSendType" SG_ 390 TrafficSignForADB2AdbVertAgTop 0;
BA_ "GenSigStartValue" SG_ 390 TrafficSignForADB2AdbVertAgTop 60;
BA_ "GenSigSendType" SG_ 512 VehBattUSysU 0;
BA_ "GenSigSendType" SG_ 512 VehBattUSysUQf 0;
BA_ "GenSigStartValue" SG_ 512 VehBattUSysUQf 1;
BA_ "GenSigSendType" SG_ 384 VehCfgPrmBlkIDBytePosn1 1;
BA_ "GenSigSendType" SG_ 384 VehCfgPrmCCPBytePosn2 1;
BA_ "GenSigSendType" SG_ 384 VehCfgPrmCCPBytePosn3 1;
BA_ "GenSigSendType" SG_ 384 VehCfgPrmCCPBytePosn4 1;
BA_ "GenSigSendType" SG_ 384 VehCfgPrmCCPBytePosn5 1;
BA_ "GenSigSendType" SG_ 384 VehCfgPrmCCPBytePosn6 1;
BA_ "GenSigSendType" SG_ 384 VehCfgPrmCCPBytePosn7 1;
BA_ "GenSigSendType" SG_ 384 VehCfgPrmCCPBytePosn8 1;
BA_ "GenSigSendType" SG_ 387 VehCfgPrmExtBlkIDBytePosn1 1;
BA_ "GenSigSendType" SG_ 387 VehCfgPrmExtCCPBytePosn2 1;
BA_ "GenSigSendType" SG_ 387 VehCfgPrmExtCCPBytePosn3 1;
BA_ "GenSigSendType" SG_ 387 VehCfgPrmExtCCPBytePosn4 1;
BA_ "GenSigSendType" SG_ 387 VehCfgPrmExtCCPBytePosn5 1;
BA_ "GenSigSendType" SG_ 387 VehCfgPrmExtCCPBytePosn6 1;
BA_ "GenSigSendType" SG_ 387 VehCfgPrmExtCCPBytePosn7 1;
BA_ "GenSigSendType" SG_ 387 VehCfgPrmExtCCPBytePosn8 1;
BA_ "GenSigSendType" SG_ 64 VehModMngtGlbSafe1CarModSts1 0;
BA_ "GenSigSendType" SG_ 64 VehModMngtGlbSafe1CarModSubtypWdCarModSubtyp 0;
BA_ "GenSigDataID" SG_ 64 VehModMngtGlbSafe1Chks "0x74";
BA_ "GenSigFuncType" SG_ 64 VehModMngtGlbSafe1Chks 15;
BA_ "GenSigSendType" SG_ 64 VehModMngtGlbSafe1Chks 0;
BA_ "GenSigFuncType" SG_ 64 VehModMngtGlbSafe1Cntr 16;
BA_ "GenSigSendType" SG_ 64 VehModMngtGlbSafe1Cntr 0;
BA_ "GenSigSendType" SG_ 64 VehModMngtGlbSafe1EgyLvlElecMai 0;
BA_ "GenSigSendType" SG_ 64 VehModMngtGlbSafe1EgyLvlElecSubtyp 0;
BA_ "GenSigSendType" SG_ 64 VehModMngtGlbSafe1FltEgyCnsWdSts 0;
BA_ "GenSigSendType" SG_ 64 VehModMngtGlbSafe1PwrLvlElecMai 0;
BA_ "GenSigSendType" SG_ 64 VehModMngtGlbSafe1PwrLvlElecSubtyp 0;
BA_ "GenSigSendType" SG_ 64 VehModMngtGlbSafe1UsgModSts 0;
BA_ "GenSigStartValue" SG_ 64 VehModMngtGlbSafe1UsgModSts 1;
BA_ "GenSigSendType" SG_ 392 VehObjforADB1AdbAbsDist 0;
BA_ "GenSigSendType" SG_ 392 VehObjforADB1AdbClassn 0;
BA_ "GenSigSendType" SG_ 392 VehObjforADB1AdbHozlAgLe 0;
BA_ "GenSigStartValue" SG_ 392 VehObjforADB1AdbHozlAgLe 800;
BA_ "GenSigSendType" SG_ 392 VehObjforADB1AdbHozlAgRi 0;
BA_ "GenSigStartValue" SG_ 392 VehObjforADB1AdbHozlAgRi 800;
BA_ "GenSigSendType" SG_ 392 VehObjforADB1AdbObjDir 0;
BA_ "GenSigSendType" SG_ 392 VehObjforADB1AdbObjHozlAgSpdLe 0;
BA_ "GenSigStartValue" SG_ 392 VehObjforADB1AdbObjHozlAgSpdLe 250;
BA_ "GenSigSendType" SG_ 392 VehObjforADB1AdbObjHozlAgSpdRi 0;
BA_ "GenSigStartValue" SG_ 392 VehObjforADB1AdbObjHozlAgSpdRi 250;
BA_ "GenSigSendType" SG_ 392 VehObjforADB1AdbTrkInfo 0;
BA_ "GenSigSendType" SG_ 392 VehObjforADB1AdbVertAg 0;
BA_ "GenSigStartValue" SG_ 392 VehObjforADB1AdbVertAg 6;
BA_ "GenSigSendType" SG_ 393 VehObjforADB2AdbAbsDist 0;
BA_ "GenSigSendType" SG_ 393 VehObjforADB2AdbClassn 0;
BA_ "GenSigSendType" SG_ 393 VehObjforADB2AdbHozlAgLe 0;
BA_ "GenSigStartValue" SG_ 393 VehObjforADB2AdbHozlAgLe 800;
BA_ "GenSigSendType" SG_ 393 VehObjforADB2AdbHozlAgRi 0;
BA_ "GenSigStartValue" SG_ 393 VehObjforADB2AdbHozlAgRi 800;
BA_ "GenSigSendType" SG_ 393 VehObjforADB2AdbObjDir 0;
BA_ "GenSigSendType" SG_ 393 VehObjforADB2AdbObjHozlAgSpdLe 0;
BA_ "GenSigStartValue" SG_ 393 VehObjforADB2AdbObjHozlAgSpdLe 250;
BA_ "GenSigSendType" SG_ 393 VehObjforADB2AdbObjHozlAgSpdRi 0;
BA_ "GenSigStartValue" SG_ 393 VehObjforADB2AdbObjHozlAgSpdRi 250;
BA_ "GenSigSendType" SG_ 393 VehObjforADB2AdbTrkInfo 0;
BA_ "GenSigSendType" SG_ 393 VehObjforADB2AdbVertAg 0;
BA_ "GenSigStartValue" SG_ 393 VehObjforADB2AdbVertAg 6;
BA_ "GenSigSendType" SG_ 394 VehObjforADB3AdbAbsDist 0;
BA_ "GenSigSendType" SG_ 394 VehObjforADB3AdbClassn 0;
BA_ "GenSigSendType" SG_ 394 VehObjforADB3AdbHozlAgLe 0;
BA_ "GenSigStartValue" SG_ 394 VehObjforADB3AdbHozlAgLe 800;
BA_ "GenSigSendType" SG_ 394 VehObjforADB3AdbHozlAgRi 0;
BA_ "GenSigStartValue" SG_ 394 VehObjforADB3AdbHozlAgRi 800;
BA_ "GenSigSendType" SG_ 394 VehObjforADB3AdbObjDir 0;
BA_ "GenSigSendType" SG_ 394 VehObjforADB3AdbObjHozlAgSpdLe 0;
BA_ "GenSigStartValue" SG_ 394 VehObjforADB3AdbObjHozlAgSpdLe 250;
BA_ "GenSigSendType" SG_ 394 VehObjforADB3AdbObjHozlAgSpdRi 0;
BA_ "GenSigStartValue" SG_ 394 VehObjforADB3AdbObjHozlAgSpdRi 250;
BA_ "GenSigSendType" SG_ 394 VehObjforADB3AdbTrkInfo 0;
BA_ "GenSigSendType" SG_ 394 VehObjforADB3AdbVertAg 0;
BA_ "GenSigStartValue" SG_ 394 VehObjforADB3AdbVertAg 6;
BA_ "GenSigSendType" SG_ 395 VehObjforADB4AdbAbsDist 0;
BA_ "GenSigSendType" SG_ 395 VehObjforADB4AdbClassn 0;
BA_ "GenSigSendType" SG_ 395 VehObjforADB4AdbHozlAgLe 0;
BA_ "GenSigStartValue" SG_ 395 VehObjforADB4AdbHozlAgLe 800;
BA_ "GenSigSendType" SG_ 395 VehObjforADB4AdbHozlAgRi 0;
BA_ "GenSigStartValue" SG_ 395 VehObjforADB4AdbHozlAgRi 800;
BA_ "GenSigSendType" SG_ 395 VehObjforADB4AdbObjDir 0;
BA_ "GenSigSendType" SG_ 395 VehObjforADB4AdbObjHozlAgSpdLe 0;
BA_ "GenSigStartValue" SG_ 395 VehObjforADB4AdbObjHozlAgSpdLe 250;
BA_ "GenSigSendType" SG_ 395 VehObjforADB4AdbObjHozlAgSpdRi 0;
BA_ "GenSigStartValue" SG_ 395 VehObjforADB4AdbObjHozlAgSpdRi 250;
BA_ "GenSigSendType" SG_ 395 VehObjforADB4AdbTrkInfo 0;
BA_ "GenSigSendType" SG_ 395 VehObjforADB4AdbVertAg 0;
BA_ "GenSigStartValue" SG_ 395 VehObjforADB4AdbVertAg 6;
BA_ "GenSigSendType" SG_ 396 VehObjforADB5AdbAbsDist 0;
BA_ "GenSigSendType" SG_ 396 VehObjforADB5AdbClassn 0;
BA_ "GenSigSendType" SG_ 396 VehObjforADB5AdbHozlAgLe 0;
BA_ "GenSigStartValue" SG_ 396 VehObjforADB5AdbHozlAgLe 800;
BA_ "GenSigSendType" SG_ 396 VehObjforADB5AdbHozlAgRi 0;
BA_ "GenSigStartValue" SG_ 396 VehObjforADB5AdbHozlAgRi 800;
BA_ "GenSigSendType" SG_ 396 VehObjforADB5AdbObjDir 0;
BA_ "GenSigSendType" SG_ 396 VehObjforADB5AdbObjHozlAgSpdLe 0;
BA_ "GenSigStartValue" SG_ 396 VehObjforADB5AdbObjHozlAgSpdLe 250;
BA_ "GenSigSendType" SG_ 396 VehObjforADB5AdbObjHozlAgSpdRi 0;
BA_ "GenSigStartValue" SG_ 396 VehObjforADB5AdbObjHozlAgSpdRi 250;
BA_ "GenSigSendType" SG_ 396 VehObjforADB5AdbTrkInfo 0;
BA_ "GenSigSendType" SG_ 396 VehObjforADB5AdbVertAg 0;
BA_ "GenSigStartValue" SG_ 396 VehObjforADB5AdbVertAg 6;
BA_ "GenSigSendType" SG_ 397 VehObjforADB6AdbAbsDist 0;
BA_ "GenSigSendType" SG_ 397 VehObjforADB6AdbClassn 0;
BA_ "GenSigSendType" SG_ 397 VehObjforADB6AdbHozlAgLe 0;
BA_ "GenSigStartValue" SG_ 397 VehObjforADB6AdbHozlAgLe 800;
BA_ "GenSigSendType" SG_ 397 VehObjforADB6AdbHozlAgRi 0;
BA_ "GenSigStartValue" SG_ 397 VehObjforADB6AdbHozlAgRi 800;
BA_ "GenSigSendType" SG_ 397 VehObjforADB6AdbObjDir 0;
BA_ "GenSigSendType" SG_ 397 VehObjforADB6AdbObjHozlAgSpdLe 0;
BA_ "GenSigStartValue" SG_ 397 VehObjforADB6AdbObjHozlAgSpdLe 250;
BA_ "GenSigSendType" SG_ 397 VehObjforADB6AdbObjHozlAgSpdRi 0;
BA_ "GenSigStartValue" SG_ 397 VehObjforADB6AdbObjHozlAgSpdRi 250;
BA_ "GenSigSendType" SG_ 397 VehObjforADB6AdbTrkInfo 0;
BA_ "GenSigSendType" SG_ 397 VehObjforADB6AdbVertAg 0;
BA_ "GenSigStartValue" SG_ 397 VehObjforADB6AdbVertAg 6;
BA_ "GenSigSendType" SG_ 398 VehObjforADB7AdbAbsDist 0;
BA_ "GenSigSendType" SG_ 398 VehObjforADB7AdbClassn 0;
BA_ "GenSigSendType" SG_ 398 VehObjforADB7AdbHozlAgLe 0;
BA_ "GenSigStartValue" SG_ 398 VehObjforADB7AdbHozlAgLe 800;
BA_ "GenSigSendType" SG_ 398 VehObjforADB7AdbHozlAgRi 0;
BA_ "GenSigStartValue" SG_ 398 VehObjforADB7AdbHozlAgRi 800;
BA_ "GenSigSendType" SG_ 398 VehObjforADB7AdbObjDir 0;
BA_ "GenSigSendType" SG_ 398 VehObjforADB7AdbObjHozlAgSpdLe 0;
BA_ "GenSigStartValue" SG_ 398 VehObjforADB7AdbObjHozlAgSpdLe 250;
BA_ "GenSigSendType" SG_ 398 VehObjforADB7AdbObjHozlAgSpdRi 0;
BA_ "GenSigStartValue" SG_ 398 VehObjforADB7AdbObjHozlAgSpdRi 250;
BA_ "GenSigSendType" SG_ 398 VehObjforADB7AdbTrkInfo 0;
BA_ "GenSigSendType" SG_ 398 VehObjforADB7AdbVertAg 0;
BA_ "GenSigStartValue" SG_ 398 VehObjforADB7AdbVertAg 6;
BA_ "GenSigSendType" SG_ 399 VehObjforADB8AdbAbsDist 0;
BA_ "GenSigSendType" SG_ 399 VehObjforADB8AdbClassn 0;
BA_ "GenSigSendType" SG_ 399 VehObjforADB8AdbHozlAgLe 0;
BA_ "GenSigStartValue" SG_ 399 VehObjforADB8AdbHozlAgLe 800;
BA_ "GenSigSendType" SG_ 399 VehObjforADB8AdbHozlAgRi 0;
BA_ "GenSigStartValue" SG_ 399 VehObjforADB8AdbHozlAgRi 800;
BA_ "GenSigSendType" SG_ 399 VehObjforADB8AdbObjDir 0;
BA_ "GenSigSendType" SG_ 399 VehObjforADB8AdbObjHozlAgSpdLe 0;
BA_ "GenSigStartValue" SG_ 399 VehObjforADB8AdbObjHozlAgSpdLe 250;
BA_ "GenSigSendType" SG_ 399 VehObjforADB8AdbObjHozlAgSpdRi 0;
BA_ "GenSigStartValue" SG_ 399 VehObjforADB8AdbObjHozlAgSpdRi 250;
BA_ "GenSigSendType" SG_ 399 VehObjforADB8AdbTrkInfo 0;
BA_ "GenSigSendType" SG_ 399 VehObjforADB8AdbVertAg 0;
BA_ "GenSigStartValue" SG_ 399 VehObjforADB8AdbVertAg 6;
BA_ "GenSigSendType" SG_ 391 VehObjforAHBAdbAbsDist 0;
BA_ "GenSigSendType" SG_ 391 VehObjforAHBAdbClassn 0;
BA_ "GenSigSendType" SG_ 391 VehObjforAHBAdbClassnQly 0;
BA_ "GenSigSendType" SG_ 391 VehObjforAHBAdbDetdQly 0;
BA_ "GenSigSendType" SG_ 391 VehObjforAHBAdbHozlAg 0;
BA_ "GenSigStartValue" SG_ 391 VehObjforAHBAdbHozlAg 800;
BA_ "GenSigSendType" SG_ 391 VehObjforAHBAdbObjDir 0;
BA_ "GenSigSendType" SG_ 391 VehObjforAHBAdbObjHozlAgSpd 0;
BA_ "GenSigStartValue" SG_ 391 VehObjforAHBAdbObjHozlAgSpd 2880;
BA_ "GenSigSendType" SG_ 391 VehObjforAHBAdbObjVertAgSpd 0;
BA_ "GenSigStartValue" SG_ 391 VehObjforAHBAdbObjVertAgSpd 720;
BA_ "GenSigSendType" SG_ 391 VehObjforAHBAdbTrkInfo 0;
BA_ "GenSigSendType" SG_ 391 VehObjforAHBAdbVertAg 0;
BA_ "GenSigStartValue" SG_ 391 VehObjforAHBAdbVertAg 75;
BA_ "GenSigSendType" SG_ 80 VehSpdLgtA 0;
BA_ "GenSigDataID" SG_ 80 VehSpdLgtChks "0x37";
BA_ "GenSigFuncType" SG_ 80 VehSpdLgtChks 15;
BA_ "GenSigSendType" SG_ 80 VehSpdLgtChks 0;
BA_ "GenSigFuncType" SG_ 80 VehSpdLgtCntr 16;
BA_ "GenSigSendType" SG_ 80 VehSpdLgtCntr 0;
BA_ "GenSigSendType" SG_ 80 VehSpdLgtQf 0;
BA_ "GenSigStartValue" SG_ 80 VehSpdLgtQf 1;
BA_ "GenSigSendType" SG_ 24 WelcomeGoodbyeModeReq 0;
BA_ "GenSigSendType" SG_ 64 WipgAutFrntMod 0;
BA_ "GenSigSendType" SG_ 612 WipgInfoWipgSpdInfo 0;
BA_ "GenSigSendType" SG_ 612 WipgInfoWiprActv 0;
BA_ "GenSigSendType" SG_ 612 WipgInfoWiprInWipgAr 0;
BA_ "GenSigSendType" SG_ 768 YawRateReqdByDrvr 0;
VAL_ 82 ActvnOfDefdLiShow 0 "OnOff1_Off" 1 "OnOff1_On";
VAL_ 82 ActvnOfMusicShowforEITL 0 "OnOff1_Off" 1 "OnOff1_On";
VAL_ 82 AutWinWipgCmd 0 "WipgSpd2_WipgSpd0Rpm" 1 "WipgSpd2_WipgSpd40Rpm" 2 "WipgSpd2_WipgSpd43Rpm" 3 "WipgSpd2_WipgSpd46Rpm" 4 "WipgSpd2_WipgSpd50Rpm" 5 "WipgSpd2_WipgSpd54Rpm" 6 "WipgSpd2_WipgSpd57Rpm" 7 "WipgSpd2_WipgSpd60Rpm";
VAL_ 82 LiOprnMod 0 "LiOperMod_Night" 1 "LiOperMod_Day" 2 "LiOperMod_Twli" 3 "LiOperMod_Tnl";
VAL_ 82 MusicShowPlaySts 0 "OnOff1_Off" 1 "OnOff1_On";
VAL_ 82 SteerWhlSnsrQf 0 "GenQf1_UndefindDataAccur" 1 "GenQf1_TmpUndefdData" 2 "GenQf1_DataAccurNotWithinSpcn" 3 "GenQf1_AccurData";
VAL_ 768 ActvnOfRvsg 0 "OnOff1_Off" 1 "OnOff1_On";
VAL_ 768 BrkPedlrRatQf 0 "GenQf1_UndefindDataAccur" 1 "GenQf1_TmpUndefdData" 2 "GenQf1_DataAccurNotWithinSpcn" 3 "GenQf1_AccurData";
VAL_ 80 DoorPassSts 0 "DoorSts2_Ukwn" 1 "DoorSts2_Opend" 2 "DoorSts2_Clsd";
VAL_ 80 DoorRiReSts 0 "DoorSts2_Ukwn" 1 "DoorSts2_Opend" 2 "DoorSts2_Clsd";
VAL_ 80 VehSpdLgtQf 0 "GenQf1_UndefindDataAccur" 1 "GenQf1_TmpUndefdData" 2 "GenQf1_DataAccurNotWithinSpcn" 3 "GenQf1_AccurData";
VAL_ 512 ExtrLiRlyPwrDwn 0 "Boolean_FALSE" 1 "Boolean_TRUE";
VAL_ 512 VehBattUSysUQf 0 "GenQf1_UndefindDataAccur" 1 "GenQf1_TmpUndefdData" 2 "GenQf1_DataAccurNotWithinSpcn" 3 "GenQf1_AccurData";
VAL_ 544 ActnOfLedFrntCrossLamp 0 "OnOff1_Off" 1 "OnOff1_On";
VAL_ 544 ActnOfLedGrilleLamp 0 "OnOff1_Off" 1 "OnOff1_On";
VAL_ 544 ActnOfLedLeLogoLamp 0 "OnOff1_Off" 1 "OnOff1_On";
VAL_ 544 ActnOfLedRiLogoLamp 0 "OnOff1_Off" 1 "OnOff1_On";
VAL_ 544 TrSts 0 "DoorSts2_Ukwn" 1 "DoorSts2_Opend" 2 "DoorSts2_Clsd";
VAL_ 128 AmbTRawQly 0 "GenQf1_UndefindDataAccur" 1 "GenQf1_TmpUndefdData" 2 "GenQf1_DataAccurNotWithinSpcn" 3 "GenQf1_AccurData";
VAL_ 128 BrkPedlSnsrQf 0 "GenQf1_UndefindDataAccur" 1 "GenQf1_TmpUndefdData" 2 "GenQf1_DataAccurNotWithinSpcn" 3 "GenQf1_AccurData";
VAL_ 128 BrkPedlSnsrSt 0 "PsdNotPsd2_NoInfo1" 1 "PsdNotPsd2_NotPsd" 2 "PsdNotPsd2_Psd" 3 "PsdNotPsd2_NoInfo2";
VAL_ 128 TooManyCars 0 "NoYes1_No" 1 "NoYes1_Yes";
VAL_ 389 ActvnOfShowModLi 0 "OnOff1_Off" 1 "OnOff1_On";
VAL_ 389 TrafficSignForADB1AdbDetdQly 0 "ClassnQly_Low" 1 "ClassnQly_Medium" 2 "ClassnQly_High";
VAL_ 389 TrafficSignForADB1AdbTrkInfo 0 "NotTracked" 1 "Tracking";
VAL_ 390 TrafficSignForADB2AdbDetdQly 0 "ClassnQly_Low" 1 "ClassnQly_Medium" 2 "ClassnQly_High";
VAL_ 390 TrafficSignForADB2AdbTrkInfo 0 "NotTracked" 1 "Tracking";
VAL_ 391 VehObjforAHBAdbClassn 0 "AdbClassn_NoVehicle" 1 "AdbClassn_Car" 2 "AdbClassn_Truck" 3 "AdbClassn_Bus" 4 "AdbClassn_BikeOrMotorBike" 5 "AdbClassn_Pedestrain" 6 "AdbClassn_Mixed" 7 "AdbClassn_Unknown";
VAL_ 391 VehObjforAHBAdbClassnQly 0 "ClassnQly_Low" 1 "ClassnQly_Medium" 2 "ClassnQly_High";
VAL_ 391 VehObjforAHBAdbDetdQly 0 "ClassnQly_Low" 1 "ClassnQly_Medium" 2 "ClassnQly_High";
VAL_ 391 VehObjforAHBAdbObjDir 0 "AdbObjDir_Idle" 1 "AdbObjDir_Oncoming" 2 "AdbObjDir_Preceding" 3 "AdbObjDir_Others";
VAL_ 391 VehObjforAHBAdbTrkInfo 0 "NotTracked" 1 "Tracking";
VAL_ 392 VehObjforADB1AdbClassn 0 "AdbClassn_NoVehicle" 1 "AdbClassn_Car" 2 "AdbClassn_Truck" 3 "AdbClassn_Bus" 4 "AdbClassn_BikeOrMotorBike" 5 "AdbClassn_Pedestrain" 6 "AdbClassn_Mixed" 7 "AdbClassn_Unknown";
VAL_ 392 VehObjforADB1AdbObjDir 0 "AdbObjDir_Idle" 1 "AdbObjDir_Oncoming" 2 "AdbObjDir_Preceding" 3 "AdbObjDir_Others";
VAL_ 392 VehObjforADB1AdbTrkInfo 0 "NotTracked" 1 "Tracking";
VAL_ 393 VehObjforADB2AdbClassn 0 "AdbClassn_NoVehicle" 1 "AdbClassn_Car" 2 "AdbClassn_Truck" 3 "AdbClassn_Bus" 4 "AdbClassn_BikeOrMotorBike" 5 "AdbClassn_Pedestrain" 6 "AdbClassn_Mixed" 7 "AdbClassn_Unknown";
VAL_ 393 VehObjforADB2AdbObjDir 0 "AdbObjDir_Idle" 1 "AdbObjDir_Oncoming" 2 "AdbObjDir_Preceding" 3 "AdbObjDir_Others";
VAL_ 393 VehObjforADB2AdbTrkInfo 0 "NotTracked" 1 "Tracking";
VAL_ 394 VehObjforADB3AdbClassn 0 "AdbClassn_NoVehicle" 1 "AdbClassn_Car" 2 "AdbClassn_Truck" 3 "AdbClassn_Bus" 4 "AdbClassn_BikeOrMotorBike" 5 "AdbClassn_Pedestrain" 6 "AdbClassn_Mixed" 7 "AdbClassn_Unknown";
VAL_ 394 VehObjforADB3AdbObjDir 0 "AdbObjDir_Idle" 1 "AdbObjDir_Oncoming" 2 "AdbObjDir_Preceding" 3 "AdbObjDir_Others";
VAL_ 394 VehObjforADB3AdbTrkInfo 0 "NotTracked" 1 "Tracking";
VAL_ 395 VehObjforADB4AdbClassn 0 "AdbClassn_NoVehicle" 1 "AdbClassn_Car" 2 "AdbClassn_Truck" 3 "AdbClassn_Bus" 4 "AdbClassn_BikeOrMotorBike" 5 "AdbClassn_Pedestrain" 6 "AdbClassn_Mixed" 7 "AdbClassn_Unknown";
VAL_ 395 VehObjforADB4AdbObjDir 0 "AdbObjDir_Idle" 1 "AdbObjDir_Oncoming" 2 "AdbObjDir_Preceding" 3 "AdbObjDir_Others";
VAL_ 395 VehObjforADB4AdbTrkInfo 0 "NotTracked" 1 "Tracking";
VAL_ 396 VehObjforADB5AdbClassn 0 "AdbClassn_NoVehicle" 1 "AdbClassn_Car" 2 "AdbClassn_Truck" 3 "AdbClassn_Bus" 4 "AdbClassn_BikeOrMotorBike" 5 "AdbClassn_Pedestrain" 6 "AdbClassn_Mixed" 7 "AdbClassn_Unknown";
VAL_ 396 VehObjforADB5AdbObjDir 0 "AdbObjDir_Idle" 1 "AdbObjDir_Oncoming" 2 "AdbObjDir_Preceding" 3 "AdbObjDir_Others";
VAL_ 396 VehObjforADB5AdbTrkInfo 0 "NotTracked" 1 "Tracking";
VAL_ 397 VehObjforADB6AdbClassn 0 "AdbClassn_NoVehicle" 1 "AdbClassn_Car" 2 "AdbClassn_Truck" 3 "AdbClassn_Bus" 4 "AdbClassn_BikeOrMotorBike" 5 "AdbClassn_Pedestrain" 6 "AdbClassn_Mixed" 7 "AdbClassn_Unknown";
VAL_ 397 VehObjforADB6AdbObjDir 0 "AdbObjDir_Idle" 1 "AdbObjDir_Oncoming" 2 "AdbObjDir_Preceding" 3 "AdbObjDir_Others";
VAL_ 397 VehObjforADB6AdbTrkInfo 0 "NotTracked" 1 "Tracking";
VAL_ 398 VehObjforADB7AdbClassn 0 "AdbClassn_NoVehicle" 1 "AdbClassn_Car" 2 "AdbClassn_Truck" 3 "AdbClassn_Bus" 4 "AdbClassn_BikeOrMotorBike" 5 "AdbClassn_Pedestrain" 6 "AdbClassn_Mixed" 7 "AdbClassn_Unknown";
VAL_ 398 VehObjforADB7AdbObjDir 0 "AdbObjDir_Idle" 1 "AdbObjDir_Oncoming" 2 "AdbObjDir_Preceding" 3 "AdbObjDir_Others";
VAL_ 398 VehObjforADB7AdbTrkInfo 0 "NotTracked" 1 "Tracking";
VAL_ 399 VehObjforADB8AdbClassn 0 "AdbClassn_NoVehicle" 1 "AdbClassn_Car" 2 "AdbClassn_Truck" 3 "AdbClassn_Bus" 4 "AdbClassn_BikeOrMotorBike" 5 "AdbClassn_Pedestrain" 6 "AdbClassn_Mixed" 7 "AdbClassn_Unknown";
VAL_ 399 VehObjforADB8AdbObjDir 0 "AdbObjDir_Idle" 1 "AdbObjDir_Oncoming" 2 "AdbObjDir_Preceding" 3 "AdbObjDir_Others";
VAL_ 399 VehObjforADB8AdbTrkInfo 0 "NotTracked" 1 "Tracking";
VAL_ 64 ActnOfAssistantLi 0 "OnOff1_Off" 1 "OnOff1_On";
VAL_ 64 CameraStsforAHBC 0 "AdbCamSts_Idle" 1 "AdbCamSts_Normal" 2 "AdbCamSts_Blocking" 3 "AdbCamSts_Unknown";
VAL_ 64 RainLi 0 "OnOff1_Off" 1 "OnOff1_On";
VAL_ 64 VehModMngtGlbSafe1CarModSts1 0 "CarModSts1_CarModNorm" 1 "CarModSts1_CarModTrnsp" 2 "CarModSts1_CarModFcy" 3 "CarModSts1_CarModCrash" 5 "CarModSts1_CarModDyno";
VAL_ 64 VehModMngtGlbSafe1FltEgyCnsWdSts 0 "FltEgyCns1_NoFlt" 1 "FltEgyCns1_Flt";
VAL_ 64 VehModMngtGlbSafe1UsgModSts 0 "UsgModSts1_UsgModAbdnd" 1 "UsgModSts1_UsgModInActv" 2 "UsgModSts1_UsgModCnvinc" 11 "UsgModSts1_UsgModActv" 13 "UsgModSts1_UsgModDrvg";
VAL_ 64 WipgAutFrntMod 0 "WipgAutFrntMod_Off" 1 "WipgAutFrntMod_ImdtMod" 2 "WipgAutFrntMod_IntlMod" 3 "WipgAutFrntMod_ContnsMod";
VAL_ 400 SuspPosnVertAgGenQf 0 "GenQf1_UndefindDataAccur" 1 "GenQf1_TmpUndefdData" 2 "GenQf1_DataAccurNotWithinSpcn" 3 "GenQf1_AccurData";
VAL_ 400 SuspPosnVertLvlFrntQf 0 "GenQf1_UndefindDataAccur" 1 "GenQf1_TmpUndefdData" 2 "GenQf1_DataAccurNotWithinSpcn" 3 "GenQf1_AccurData";
VAL_ 400 SuspPosnVertLvlReQf 0 "GenQf1_UndefindDataAccur" 1 "GenQf1_TmpUndefdData" 2 "GenQf1_DataAccurNotWithinSpcn" 3 "GenQf1_AccurData";
VAL_ 28 ExtrLiShowActvnReq 0 "OnOff1_Off" 1 "OnOff1_On";
VAL_ 28 ExtrLiShowFileTxReq 0 "OnOff1_Off" 1 "OnOff1_On";
VAL_ 834 DwnLoadDynLtgPrmForFrntRIGrp10Mode1 0 "Mode4_Off" 1 "Mode4_On" 2 "Mode4_GradualOn" 3 "Mode4_GradualOff" 4 "Mode4_ForwardWipingOn" 5 "Mode4_BackwardWipingOn" 6 "Mode4_OutwardWipingOn" 7 "Mode4_InwardWipingOn" 8 "Mode4_ForwardWipingOff" 9 "Mode4_BackwardWipingOff" 10 "Mode4_OutwardWipingOff" 11 "Mode4_InwardWipingOff" 12 "Mode4_ForwardScanning" 13 "Mode4_BackwardScanning" 14 "Mode4_BreathOn" 15 "Mode4_BreathOff" 16 "Mode4_1stHalfONand2ndHalfOFF" 17 "Mode4_HalfOFFHalfON" 18 "Mode4_HalfDimmingONHalfOFF" 19 "Mode4_HalfDimmingONHalfON" 20 "Mode4_HalfOFFHalfDimmingON" 21 "Mode4_HalfONHalfDimmingON" 22 "Mode4_HalfDimmingOFFHalfOFF" 23 "Mode4_HalfDimmingOFFHalfON" 24 "Mode4_HalfOFFHalfDimmingOFF" 25 "Mode4_HalfONHalfDimmingOFF" 26 "Mode4_SingleOn1" 27 "Mode4_SingleOn2" 28 "Mode4_SingleOn3" 29 "Mode4_SingleOn4" 30 "Mode4_SingleOn5" 31 "Mode4_SingleOn6" 32 "Mode4_SingleOn7" 33 "Mode4_SingleOn8" 34 "Mode4_SingleOn9" 35 "Mode4_SingleOn10" 36 "Mode4_SingleOn11" 37 "Mode4_SingleOn12" 38 "Mode4_SingleOff1" 39 "Mode4_SingleOff2" 40 "Mode4_SingleOff3" 41 "Mode4_SingleOff4" 42 "Mode4_SingleOff5" 43 "Mode4_SingleOff6" 44 "Mode4_SingleOff7" 45 "Mode4_SingleOff8" 46 "Mode4_SingleOff9" 47 "Mode4_SingleOff10" 48 "Mode4_SingleOff11" 49 "Mode4_SingleOff12";
VAL_ 835 DwnLoadDynLtgPrmForFrntRIGrp11Mode1 0 "Mode4_Off" 1 "Mode4_On" 2 "Mode4_GradualOn" 3 "Mode4_GradualOff" 4 "Mode4_ForwardWipingOn" 5 "Mode4_BackwardWipingOn" 6 "Mode4_OutwardWipingOn" 7 "Mode4_InwardWipingOn" 8 "Mode4_ForwardWipingOff" 9 "Mode4_BackwardWipingOff" 10 "Mode4_OutwardWipingOff" 11 "Mode4_InwardWipingOff" 12 "Mode4_ForwardScanning" 13 "Mode4_BackwardScanning" 14 "Mode4_BreathOn" 15 "Mode4_BreathOff" 16 "Mode4_1stHalfONand2ndHalfOFF" 17 "Mode4_HalfOFFHalfON" 18 "Mode4_HalfDimmingONHalfOFF" 19 "Mode4_HalfDimmingONHalfON" 20 "Mode4_HalfOFFHalfDimmingON" 21 "Mode4_HalfONHalfDimmingON" 22 "Mode4_HalfDimmingOFFHalfOFF" 23 "Mode4_HalfDimmingOFFHalfON" 24 "Mode4_HalfOFFHalfDimmingOFF" 25 "Mode4_HalfONHalfDimmingOFF" 26 "Mode4_SingleOn1" 27 "Mode4_SingleOn2" 28 "Mode4_SingleOn3" 29 "Mode4_SingleOn4" 30 "Mode4_SingleOn5" 31 "Mode4_SingleOn6" 32 "Mode4_SingleOn7" 33 "Mode4_SingleOn8" 34 "Mode4_SingleOn9" 35 "Mode4_SingleOn10" 36 "Mode4_SingleOn11" 37 "Mode4_SingleOn12" 38 "Mode4_SingleOff1" 39 "Mode4_SingleOff2" 40 "Mode4_SingleOff3" 41 "Mode4_SingleOff4" 42 "Mode4_SingleOff5" 43 "Mode4_SingleOff6" 44 "Mode4_SingleOff7" 45 "Mode4_SingleOff8" 46 "Mode4_SingleOff9" 47 "Mode4_SingleOff10" 48 "Mode4_SingleOff11" 49 "Mode4_SingleOff12";
VAL_ 836 DwnLoadDynLtgPrmForFrntRIGrp12Mode1 0 "Mode4_Off" 1 "Mode4_On" 2 "Mode4_GradualOn" 3 "Mode4_GradualOff" 4 "Mode4_ForwardWipingOn" 5 "Mode4_BackwardWipingOn" 6 "Mode4_OutwardWipingOn" 7 "Mode4_InwardWipingOn" 8 "Mode4_ForwardWipingOff" 9 "Mode4_BackwardWipingOff" 10 "Mode4_OutwardWipingOff" 11 "Mode4_InwardWipingOff" 12 "Mode4_ForwardScanning" 13 "Mode4_BackwardScanning" 14 "Mode4_BreathOn" 15 "Mode4_BreathOff" 16 "Mode4_1stHalfONand2ndHalfOFF" 17 "Mode4_HalfOFFHalfON" 18 "Mode4_HalfDimmingONHalfOFF" 19 "Mode4_HalfDimmingONHalfON" 20 "Mode4_HalfOFFHalfDimmingON" 21 "Mode4_HalfONHalfDimmingON" 22 "Mode4_HalfDimmingOFFHalfOFF" 23 "Mode4_HalfDimmingOFFHalfON" 24 "Mode4_HalfOFFHalfDimmingOFF" 25 "Mode4_HalfONHalfDimmingOFF" 26 "Mode4_SingleOn1" 27 "Mode4_SingleOn2" 28 "Mode4_SingleOn3" 29 "Mode4_SingleOn4" 30 "Mode4_SingleOn5" 31 "Mode4_SingleOn6" 32 "Mode4_SingleOn7" 33 "Mode4_SingleOn8" 34 "Mode4_SingleOn9" 35 "Mode4_SingleOn10" 36 "Mode4_SingleOn11" 37 "Mode4_SingleOn12" 38 "Mode4_SingleOff1" 39 "Mode4_SingleOff2" 40 "Mode4_SingleOff3" 41 "Mode4_SingleOff4" 42 "Mode4_SingleOff5" 43 "Mode4_SingleOff6" 44 "Mode4_SingleOff7" 45 "Mode4_SingleOff8" 46 "Mode4_SingleOff9" 47 "Mode4_SingleOff10" 48 "Mode4_SingleOff11" 49 "Mode4_SingleOff12";
VAL_ 837 DwnLoadDynLtgPrmForFrntRIGrp13Mode1 0 "Mode4_Off" 1 "Mode4_On" 2 "Mode4_GradualOn" 3 "Mode4_GradualOff" 4 "Mode4_ForwardWipingOn" 5 "Mode4_BackwardWipingOn" 6 "Mode4_OutwardWipingOn" 7 "Mode4_InwardWipingOn" 8 "Mode4_ForwardWipingOff" 9 "Mode4_BackwardWipingOff" 10 "Mode4_OutwardWipingOff" 11 "Mode4_InwardWipingOff" 12 "Mode4_ForwardScanning" 13 "Mode4_BackwardScanning" 14 "Mode4_BreathOn" 15 "Mode4_BreathOff" 16 "Mode4_1stHalfONand2ndHalfOFF" 17 "Mode4_HalfOFFHalfON" 18 "Mode4_HalfDimmingONHalfOFF" 19 "Mode4_HalfDimmingONHalfON" 20 "Mode4_HalfOFFHalfDimmingON" 21 "Mode4_HalfONHalfDimmingON" 22 "Mode4_HalfDimmingOFFHalfOFF" 23 "Mode4_HalfDimmingOFFHalfON" 24 "Mode4_HalfOFFHalfDimmingOFF" 25 "Mode4_HalfONHalfDimmingOFF" 26 "Mode4_SingleOn1" 27 "Mode4_SingleOn2" 28 "Mode4_SingleOn3" 29 "Mode4_SingleOn4" 30 "Mode4_SingleOn5" 31 "Mode4_SingleOn6" 32 "Mode4_SingleOn7" 33 "Mode4_SingleOn8" 34 "Mode4_SingleOn9" 35 "Mode4_SingleOn10" 36 "Mode4_SingleOn11" 37 "Mode4_SingleOn12" 38 "Mode4_SingleOff1" 39 "Mode4_SingleOff2" 40 "Mode4_SingleOff3" 41 "Mode4_SingleOff4" 42 "Mode4_SingleOff5" 43 "Mode4_SingleOff6" 44 "Mode4_SingleOff7" 45 "Mode4_SingleOff8" 46 "Mode4_SingleOff9" 47 "Mode4_SingleOff10" 48 "Mode4_SingleOff11" 49 "Mode4_SingleOff12";
VAL_ 838 DwnLoadDynLtgPrmForFrntRIGrp14Mode1 0 "Mode4_Off" 1 "Mode4_On" 2 "Mode4_GradualOn" 3 "Mode4_GradualOff" 4 "Mode4_ForwardWipingOn" 5 "Mode4_BackwardWipingOn" 6 "Mode4_OutwardWipingOn" 7 "Mode4_InwardWipingOn" 8 "Mode4_ForwardWipingOff" 9 "Mode4_BackwardWipingOff" 10 "Mode4_OutwardWipingOff" 11 "Mode4_InwardWipingOff" 12 "Mode4_ForwardScanning" 13 "Mode4_BackwardScanning" 14 "Mode4_BreathOn" 15 "Mode4_BreathOff" 16 "Mode4_1stHalfONand2ndHalfOFF" 17 "Mode4_HalfOFFHalfON" 18 "Mode4_HalfDimmingONHalfOFF" 19 "Mode4_HalfDimmingONHalfON" 20 "Mode4_HalfOFFHalfDimmingON" 21 "Mode4_HalfONHalfDimmingON" 22 "Mode4_HalfDimmingOFFHalfOFF" 23 "Mode4_HalfDimmingOFFHalfON" 24 "Mode4_HalfOFFHalfDimmingOFF" 25 "Mode4_HalfONHalfDimmingOFF" 26 "Mode4_SingleOn1" 27 "Mode4_SingleOn2" 28 "Mode4_SingleOn3" 29 "Mode4_SingleOn4" 30 "Mode4_SingleOn5" 31 "Mode4_SingleOn6" 32 "Mode4_SingleOn7" 33 "Mode4_SingleOn8" 34 "Mode4_SingleOn9" 35 "Mode4_SingleOn10" 36 "Mode4_SingleOn11" 37 "Mode4_SingleOn12" 38 "Mode4_SingleOff1" 39 "Mode4_SingleOff2" 40 "Mode4_SingleOff3" 41 "Mode4_SingleOff4" 42 "Mode4_SingleOff5" 43 "Mode4_SingleOff6" 44 "Mode4_SingleOff7" 45 "Mode4_SingleOff8" 46 "Mode4_SingleOff9" 47 "Mode4_SingleOff10" 48 "Mode4_SingleOff11" 49 "Mode4_SingleOff12";
VAL_ 839 DwnLoadDynLtgPrmForFrntRIGrp15Mode1 0 "Mode4_Off" 1 "Mode4_On" 2 "Mode4_GradualOn" 3 "Mode4_GradualOff" 4 "Mode4_ForwardWipingOn" 5 "Mode4_BackwardWipingOn" 6 "Mode4_OutwardWipingOn" 7 "Mode4_InwardWipingOn" 8 "Mode4_ForwardWipingOff" 9 "Mode4_BackwardWipingOff" 10 "Mode4_OutwardWipingOff" 11 "Mode4_InwardWipingOff" 12 "Mode4_ForwardScanning" 13 "Mode4_BackwardScanning" 14 "Mode4_BreathOn" 15 "Mode4_BreathOff" 16 "Mode4_1stHalfONand2ndHalfOFF" 17 "Mode4_HalfOFFHalfON" 18 "Mode4_HalfDimmingONHalfOFF" 19 "Mode4_HalfDimmingONHalfON" 20 "Mode4_HalfOFFHalfDimmingON" 21 "Mode4_HalfONHalfDimmingON" 22 "Mode4_HalfDimmingOFFHalfOFF" 23 "Mode4_HalfDimmingOFFHalfON" 24 "Mode4_HalfOFFHalfDimmingOFF" 25 "Mode4_HalfONHalfDimmingOFF" 26 "Mode4_SingleOn1" 27 "Mode4_SingleOn2" 28 "Mode4_SingleOn3" 29 "Mode4_SingleOn4" 30 "Mode4_SingleOn5" 31 "Mode4_SingleOn6" 32 "Mode4_SingleOn7" 33 "Mode4_SingleOn8" 34 "Mode4_SingleOn9" 35 "Mode4_SingleOn10" 36 "Mode4_SingleOn11" 37 "Mode4_SingleOn12" 38 "Mode4_SingleOff1" 39 "Mode4_SingleOff2" 40 "Mode4_SingleOff3" 41 "Mode4_SingleOff4" 42 "Mode4_SingleOff5" 43 "Mode4_SingleOff6" 44 "Mode4_SingleOff7" 45 "Mode4_SingleOff8" 46 "Mode4_SingleOff9" 47 "Mode4_SingleOff10" 48 "Mode4_SingleOff11" 49 "Mode4_SingleOff12";
VAL_ 840 DwnLoadDynLtgPrmForFrntRIGrp16Mode1 0 "Mode4_Off" 1 "Mode4_On" 2 "Mode4_GradualOn" 3 "Mode4_GradualOff" 4 "Mode4_ForwardWipingOn" 5 "Mode4_BackwardWipingOn" 6 "Mode4_OutwardWipingOn" 7 "Mode4_InwardWipingOn" 8 "Mode4_ForwardWipingOff" 9 "Mode4_BackwardWipingOff" 10 "Mode4_OutwardWipingOff" 11 "Mode4_InwardWipingOff" 12 "Mode4_ForwardScanning" 13 "Mode4_BackwardScanning" 14 "Mode4_BreathOn" 15 "Mode4_BreathOff" 16 "Mode4_1stHalfONand2ndHalfOFF" 17 "Mode4_HalfOFFHalfON" 18 "Mode4_HalfDimmingONHalfOFF" 19 "Mode4_HalfDimmingONHalfON" 20 "Mode4_HalfOFFHalfDimmingON" 21 "Mode4_HalfONHalfDimmingON" 22 "Mode4_HalfDimmingOFFHalfOFF" 23 "Mode4_HalfDimmingOFFHalfON" 24 "Mode4_HalfOFFHalfDimmingOFF" 25 "Mode4_HalfONHalfDimmingOFF" 26 "Mode4_SingleOn1" 27 "Mode4_SingleOn2" 28 "Mode4_SingleOn3" 29 "Mode4_SingleOn4" 30 "Mode4_SingleOn5" 31 "Mode4_SingleOn6" 32 "Mode4_SingleOn7" 33 "Mode4_SingleOn8" 34 "Mode4_SingleOn9" 35 "Mode4_SingleOn10" 36 "Mode4_SingleOn11" 37 "Mode4_SingleOn12" 38 "Mode4_SingleOff1" 39 "Mode4_SingleOff2" 40 "Mode4_SingleOff3" 41 "Mode4_SingleOff4" 42 "Mode4_SingleOff5" 43 "Mode4_SingleOff6" 44 "Mode4_SingleOff7" 45 "Mode4_SingleOff8" 46 "Mode4_SingleOff9" 47 "Mode4_SingleOff10" 48 "Mode4_SingleOff11" 49 "Mode4_SingleOff12";
VAL_ 841 DwnLoadDynLtgPrmForFrntRIGrp17Mode1 0 "Mode4_Off" 1 "Mode4_On" 2 "Mode4_GradualOn" 3 "Mode4_GradualOff" 4 "Mode4_ForwardWipingOn" 5 "Mode4_BackwardWipingOn" 6 "Mode4_OutwardWipingOn" 7 "Mode4_InwardWipingOn" 8 "Mode4_ForwardWipingOff" 9 "Mode4_BackwardWipingOff" 10 "Mode4_OutwardWipingOff" 11 "Mode4_InwardWipingOff" 12 "Mode4_ForwardScanning" 13 "Mode4_BackwardScanning" 14 "Mode4_BreathOn" 15 "Mode4_BreathOff" 16 "Mode4_1stHalfONand2ndHalfOFF" 17 "Mode4_HalfOFFHalfON" 18 "Mode4_HalfDimmingONHalfOFF" 19 "Mode4_HalfDimmingONHalfON" 20 "Mode4_HalfOFFHalfDimmingON" 21 "Mode4_HalfONHalfDimmingON" 22 "Mode4_HalfDimmingOFFHalfOFF" 23 "Mode4_HalfDimmingOFFHalfON" 24 "Mode4_HalfOFFHalfDimmingOFF" 25 "Mode4_HalfONHalfDimmingOFF" 26 "Mode4_SingleOn1" 27 "Mode4_SingleOn2" 28 "Mode4_SingleOn3" 29 "Mode4_SingleOn4" 30 "Mode4_SingleOn5" 31 "Mode4_SingleOn6" 32 "Mode4_SingleOn7" 33 "Mode4_SingleOn8" 34 "Mode4_SingleOn9" 35 "Mode4_SingleOn10" 36 "Mode4_SingleOn11" 37 "Mode4_SingleOn12" 38 "Mode4_SingleOff1" 39 "Mode4_SingleOff2" 40 "Mode4_SingleOff3" 41 "Mode4_SingleOff4" 42 "Mode4_SingleOff5" 43 "Mode4_SingleOff6" 44 "Mode4_SingleOff7" 45 "Mode4_SingleOff8" 46 "Mode4_SingleOff9" 47 "Mode4_SingleOff10" 48 "Mode4_SingleOff11" 49 "Mode4_SingleOff12";
VAL_ 842 DwnLoadDynLtgPrmForFrntRIGrp18Mode1 0 "Mode4_Off" 1 "Mode4_On" 2 "Mode4_GradualOn" 3 "Mode4_GradualOff" 4 "Mode4_ForwardWipingOn" 5 "Mode4_BackwardWipingOn" 6 "Mode4_OutwardWipingOn" 7 "Mode4_InwardWipingOn" 8 "Mode4_ForwardWipingOff" 9 "Mode4_BackwardWipingOff" 10 "Mode4_OutwardWipingOff" 11 "Mode4_InwardWipingOff" 12 "Mode4_ForwardScanning" 13 "Mode4_BackwardScanning" 14 "Mode4_BreathOn" 15 "Mode4_BreathOff" 16 "Mode4_1stHalfONand2ndHalfOFF" 17 "Mode4_HalfOFFHalfON" 18 "Mode4_HalfDimmingONHalfOFF" 19 "Mode4_HalfDimmingONHalfON" 20 "Mode4_HalfOFFHalfDimmingON" 21 "Mode4_HalfONHalfDimmingON" 22 "Mode4_HalfDimmingOFFHalfOFF" 23 "Mode4_HalfDimmingOFFHalfON" 24 "Mode4_HalfOFFHalfDimmingOFF" 25 "Mode4_HalfONHalfDimmingOFF" 26 "Mode4_SingleOn1" 27 "Mode4_SingleOn2" 28 "Mode4_SingleOn3" 29 "Mode4_SingleOn4" 30 "Mode4_SingleOn5" 31 "Mode4_SingleOn6" 32 "Mode4_SingleOn7" 33 "Mode4_SingleOn8" 34 "Mode4_SingleOn9" 35 "Mode4_SingleOn10" 36 "Mode4_SingleOn11" 37 "Mode4_SingleOn12" 38 "Mode4_SingleOff1" 39 "Mode4_SingleOff2" 40 "Mode4_SingleOff3" 41 "Mode4_SingleOff4" 42 "Mode4_SingleOff5" 43 "Mode4_SingleOff6" 44 "Mode4_SingleOff7" 45 "Mode4_SingleOff8" 46 "Mode4_SingleOff9" 47 "Mode4_SingleOff10" 48 "Mode4_SingleOff11" 49 "Mode4_SingleOff12";
VAL_ 843 DwnLoadDynLtgPrmForFrntRIGrp19Mode1 0 "Mode4_Off" 1 "Mode4_On" 2 "Mode4_GradualOn" 3 "Mode4_GradualOff" 4 "Mode4_ForwardWipingOn" 5 "Mode4_BackwardWipingOn" 6 "Mode4_OutwardWipingOn" 7 "Mode4_InwardWipingOn" 8 "Mode4_ForwardWipingOff" 9 "Mode4_BackwardWipingOff" 10 "Mode4_OutwardWipingOff" 11 "Mode4_InwardWipingOff" 12 "Mode4_ForwardScanning" 13 "Mode4_BackwardScanning" 14 "Mode4_BreathOn" 15 "Mode4_BreathOff" 16 "Mode4_1stHalfONand2ndHalfOFF" 17 "Mode4_HalfOFFHalfON" 18 "Mode4_HalfDimmingONHalfOFF" 19 "Mode4_HalfDimmingONHalfON" 20 "Mode4_HalfOFFHalfDimmingON" 21 "Mode4_HalfONHalfDimmingON" 22 "Mode4_HalfDimmingOFFHalfOFF" 23 "Mode4_HalfDimmingOFFHalfON" 24 "Mode4_HalfOFFHalfDimmingOFF" 25 "Mode4_HalfONHalfDimmingOFF" 26 "Mode4_SingleOn1" 27 "Mode4_SingleOn2" 28 "Mode4_SingleOn3" 29 "Mode4_SingleOn4" 30 "Mode4_SingleOn5" 31 "Mode4_SingleOn6" 32 "Mode4_SingleOn7" 33 "Mode4_SingleOn8" 34 "Mode4_SingleOn9" 35 "Mode4_SingleOn10" 36 "Mode4_SingleOn11" 37 "Mode4_SingleOn12" 38 "Mode4_SingleOff1" 39 "Mode4_SingleOff2" 40 "Mode4_SingleOff3" 41 "Mode4_SingleOff4" 42 "Mode4_SingleOff5" 43 "Mode4_SingleOff6" 44 "Mode4_SingleOff7" 45 "Mode4_SingleOff8" 46 "Mode4_SingleOff9" 47 "Mode4_SingleOff10" 48 "Mode4_SingleOff11" 49 "Mode4_SingleOff12";
VAL_ 844 DwnLoadDynLtgPrmForFrntRIGrp20Mode1 0 "Mode4_Off" 1 "Mode4_On" 2 "Mode4_GradualOn" 3 "Mode4_GradualOff" 4 "Mode4_ForwardWipingOn" 5 "Mode4_BackwardWipingOn" 6 "Mode4_OutwardWipingOn" 7 "Mode4_InwardWipingOn" 8 "Mode4_ForwardWipingOff" 9 "Mode4_BackwardWipingOff" 10 "Mode4_OutwardWipingOff" 11 "Mode4_InwardWipingOff" 12 "Mode4_ForwardScanning" 13 "Mode4_BackwardScanning" 14 "Mode4_BreathOn" 15 "Mode4_BreathOff" 16 "Mode4_1stHalfONand2ndHalfOFF" 17 "Mode4_HalfOFFHalfON" 18 "Mode4_HalfDimmingONHalfOFF" 19 "Mode4_HalfDimmingONHalfON" 20 "Mode4_HalfOFFHalfDimmingON" 21 "Mode4_HalfONHalfDimmingON" 22 "Mode4_HalfDimmingOFFHalfOFF" 23 "Mode4_HalfDimmingOFFHalfON" 24 "Mode4_HalfOFFHalfDimmingOFF" 25 "Mode4_HalfONHalfDimmingOFF" 26 "Mode4_SingleOn1" 27 "Mode4_SingleOn2" 28 "Mode4_SingleOn3" 29 "Mode4_SingleOn4" 30 "Mode4_SingleOn5" 31 "Mode4_SingleOn6" 32 "Mode4_SingleOn7" 33 "Mode4_SingleOn8" 34 "Mode4_SingleOn9" 35 "Mode4_SingleOn10" 36 "Mode4_SingleOn11" 37 "Mode4_SingleOn12" 38 "Mode4_SingleOff1" 39 "Mode4_SingleOff2" 40 "Mode4_SingleOff3" 41 "Mode4_SingleOff4" 42 "Mode4_SingleOff5" 43 "Mode4_SingleOff6" 44 "Mode4_SingleOff7" 45 "Mode4_SingleOff8" 46 "Mode4_SingleOff9" 47 "Mode4_SingleOff10" 48 "Mode4_SingleOff11" 49 "Mode4_SingleOff12";
VAL_ 845 DwnLoadDynLtgPrmForFrntRIGrp21Mode1 0 "Mode4_Off" 1 "Mode4_On" 2 "Mode4_GradualOn" 3 "Mode4_GradualOff" 4 "Mode4_ForwardWipingOn" 5 "Mode4_BackwardWipingOn" 6 "Mode4_OutwardWipingOn" 7 "Mode4_InwardWipingOn" 8 "Mode4_ForwardWipingOff" 9 "Mode4_BackwardWipingOff" 10 "Mode4_OutwardWipingOff" 11 "Mode4_InwardWipingOff" 12 "Mode4_ForwardScanning" 13 "Mode4_BackwardScanning" 14 "Mode4_BreathOn" 15 "Mode4_BreathOff" 16 "Mode4_1stHalfONand2ndHalfOFF" 17 "Mode4_HalfOFFHalfON" 18 "Mode4_HalfDimmingONHalfOFF" 19 "Mode4_HalfDimmingONHalfON" 20 "Mode4_HalfOFFHalfDimmingON" 21 "Mode4_HalfONHalfDimmingON" 22 "Mode4_HalfDimmingOFFHalfOFF" 23 "Mode4_HalfDimmingOFFHalfON" 24 "Mode4_HalfOFFHalfDimmingOFF" 25 "Mode4_HalfONHalfDimmingOFF" 26 "Mode4_SingleOn1" 27 "Mode4_SingleOn2" 28 "Mode4_SingleOn3" 29 "Mode4_SingleOn4" 30 "Mode4_SingleOn5" 31 "Mode4_SingleOn6" 32 "Mode4_SingleOn7" 33 "Mode4_SingleOn8" 34 "Mode4_SingleOn9" 35 "Mode4_SingleOn10" 36 "Mode4_SingleOn11" 37 "Mode4_SingleOn12" 38 "Mode4_SingleOff1" 39 "Mode4_SingleOff2" 40 "Mode4_SingleOff3" 41 "Mode4_SingleOff4" 42 "Mode4_SingleOff5" 43 "Mode4_SingleOff6" 44 "Mode4_SingleOff7" 45 "Mode4_SingleOff8" 46 "Mode4_SingleOff9" 47 "Mode4_SingleOff10" 48 "Mode4_SingleOff11" 49 "Mode4_SingleOff12";
VAL_ 846 DwnLoadDynLtgPrmForFrntRIGrp22Mode1 0 "Mode4_Off" 1 "Mode4_On" 2 "Mode4_GradualOn" 3 "Mode4_GradualOff" 4 "Mode4_ForwardWipingOn" 5 "Mode4_BackwardWipingOn" 6 "Mode4_OutwardWipingOn" 7 "Mode4_InwardWipingOn" 8 "Mode4_ForwardWipingOff" 9 "Mode4_BackwardWipingOff" 10 "Mode4_OutwardWipingOff" 11 "Mode4_InwardWipingOff" 12 "Mode4_ForwardScanning" 13 "Mode4_BackwardScanning" 14 "Mode4_BreathOn" 15 "Mode4_BreathOff" 16 "Mode4_1stHalfONand2ndHalfOFF" 17 "Mode4_HalfOFFHalfON" 18 "Mode4_HalfDimmingONHalfOFF" 19 "Mode4_HalfDimmingONHalfON" 20 "Mode4_HalfOFFHalfDimmingON" 21 "Mode4_HalfONHalfDimmingON" 22 "Mode4_HalfDimmingOFFHalfOFF" 23 "Mode4_HalfDimmingOFFHalfON" 24 "Mode4_HalfOFFHalfDimmingOFF" 25 "Mode4_HalfONHalfDimmingOFF" 26 "Mode4_SingleOn1" 27 "Mode4_SingleOn2" 28 "Mode4_SingleOn3" 29 "Mode4_SingleOn4" 30 "Mode4_SingleOn5" 31 "Mode4_SingleOn6" 32 "Mode4_SingleOn7" 33 "Mode4_SingleOn8" 34 "Mode4_SingleOn9" 35 "Mode4_SingleOn10" 36 "Mode4_SingleOn11" 37 "Mode4_SingleOn12" 38 "Mode4_SingleOff1" 39 "Mode4_SingleOff2" 40 "Mode4_SingleOff3" 41 "Mode4_SingleOff4" 42 "Mode4_SingleOff5" 43 "Mode4_SingleOff6" 44 "Mode4_SingleOff7" 45 "Mode4_SingleOff8" 46 "Mode4_SingleOff9" 47 "Mode4_SingleOff10" 48 "Mode4_SingleOff11" 49 "Mode4_SingleOff12";
VAL_ 847 DwnLoadDynLtgPrmForFrntRIGrp23Mode1 0 "Mode4_Off" 1 "Mode4_On" 2 "Mode4_GradualOn" 3 "Mode4_GradualOff" 4 "Mode4_ForwardWipingOn" 5 "Mode4_BackwardWipingOn" 6 "Mode4_OutwardWipingOn" 7 "Mode4_InwardWipingOn" 8 "Mode4_ForwardWipingOff" 9 "Mode4_BackwardWipingOff" 10 "Mode4_OutwardWipingOff" 11 "Mode4_InwardWipingOff" 12 "Mode4_ForwardScanning" 13 "Mode4_BackwardScanning" 14 "Mode4_BreathOn" 15 "Mode4_BreathOff" 16 "Mode4_1stHalfONand2ndHalfOFF" 17 "Mode4_HalfOFFHalfON" 18 "Mode4_HalfDimmingONHalfOFF" 19 "Mode4_HalfDimmingONHalfON" 20 "Mode4_HalfOFFHalfDimmingON" 21 "Mode4_HalfONHalfDimmingON" 22 "Mode4_HalfDimmingOFFHalfOFF" 23 "Mode4_HalfDimmingOFFHalfON" 24 "Mode4_HalfOFFHalfDimmingOFF" 25 "Mode4_HalfONHalfDimmingOFF" 26 "Mode4_SingleOn1" 27 "Mode4_SingleOn2" 28 "Mode4_SingleOn3" 29 "Mode4_SingleOn4" 30 "Mode4_SingleOn5" 31 "Mode4_SingleOn6" 32 "Mode4_SingleOn7" 33 "Mode4_SingleOn8" 34 "Mode4_SingleOn9" 35 "Mode4_SingleOn10" 36 "Mode4_SingleOn11" 37 "Mode4_SingleOn12" 38 "Mode4_SingleOff1" 39 "Mode4_SingleOff2" 40 "Mode4_SingleOff3" 41 "Mode4_SingleOff4" 42 "Mode4_SingleOff5" 43 "Mode4_SingleOff6" 44 "Mode4_SingleOff7" 45 "Mode4_SingleOff8" 46 "Mode4_SingleOff9" 47 "Mode4_SingleOff10" 48 "Mode4_SingleOff11" 49 "Mode4_SingleOff12";
VAL_ 848 DwnLoadDynLtgPrmForFrntRIGrp24Mode1 0 "Mode4_Off" 1 "Mode4_On" 2 "Mode4_GradualOn" 3 "Mode4_GradualOff" 4 "Mode4_ForwardWipingOn" 5 "Mode4_BackwardWipingOn" 6 "Mode4_OutwardWipingOn" 7 "Mode4_InwardWipingOn" 8 "Mode4_ForwardWipingOff" 9 "Mode4_BackwardWipingOff" 10 "Mode4_OutwardWipingOff" 11 "Mode4_InwardWipingOff" 12 "Mode4_ForwardScanning" 13 "Mode4_BackwardScanning" 14 "Mode4_BreathOn" 15 "Mode4_BreathOff" 16 "Mode4_1stHalfONand2ndHalfOFF" 17 "Mode4_HalfOFFHalfON" 18 "Mode4_HalfDimmingONHalfOFF" 19 "Mode4_HalfDimmingONHalfON" 20 "Mode4_HalfOFFHalfDimmingON" 21 "Mode4_HalfONHalfDimmingON" 22 "Mode4_HalfDimmingOFFHalfOFF" 23 "Mode4_HalfDimmingOFFHalfON" 24 "Mode4_HalfOFFHalfDimmingOFF" 25 "Mode4_HalfONHalfDimmingOFF" 26 "Mode4_SingleOn1" 27 "Mode4_SingleOn2" 28 "Mode4_SingleOn3" 29 "Mode4_SingleOn4" 30 "Mode4_SingleOn5" 31 "Mode4_SingleOn6" 32 "Mode4_SingleOn7" 33 "Mode4_SingleOn8" 34 "Mode4_SingleOn9" 35 "Mode4_SingleOn10" 36 "Mode4_SingleOn11" 37 "Mode4_SingleOn12" 38 "Mode4_SingleOff1" 39 "Mode4_SingleOff2" 40 "Mode4_SingleOff3" 41 "Mode4_SingleOff4" 42 "Mode4_SingleOff5" 43 "Mode4_SingleOff6" 44 "Mode4_SingleOff7" 45 "Mode4_SingleOff8" 46 "Mode4_SingleOff9" 47 "Mode4_SingleOff10" 48 "Mode4_SingleOff11" 49 "Mode4_SingleOff12";
VAL_ 784 ActvnOfADB 0 "OnOff1_Off" 1 "OnOff1_On";
VAL_ 784 ActvnOfLiForComity 0 "OnOff1_Off" 1 "OnOff1_On";
VAL_ 784 ActvnOfLiForSpkr 0 "OnOff1_Off" 1 "OnOff1_On";
VAL_ 784 ActvnOfLiForWait 0 "OnOff1_Off" 1 "OnOff1_On";
VAL_ 784 LockgCenStsLockSt 0 "LockSt3_LockUndefd" 1 "LockSt3_LockUnlckd" 2 "LockSt3_LockTrUnlckd" 3 "LockSt3_LockLockd";
VAL_ 784 LockgCenStsTrigSrc 0 "LockTrigSrc2_NoTrigSrc" 1 "LockTrigSrc2_KeyRem" 2 "LockTrigSrc2_Keyls" 3 "LockTrigSrc2_IntrSwt" 4 "LockTrigSrc2_SpdAut" 5 "LockTrigSrc2_TmrAut" 6 "LockTrigSrc2_Slam" 7 "LockTrigSrc2_Telm" 8 "LockTrigSrc2_Crash" 9 "LockTrigSrc2_Apprch" 10 "LockTrigSrc2_OutsOth" 11 "LockTrigSrc2_InsOth";
VAL_ 784 LockgCenStsUpdEve 0 "Boolean_FALSE" 1 "Boolean_TRUE";
VAL_ 1152 TiAndDateIndcnDataValid 0 "NoYes1_No" 1 "NoYes1_Yes";
VAL_ 120 CarpetLiModReq 0 "ModeReq_Mode1" 1 "ModeReq_Mode2" 2 "ModeReq_Mode3" 3 "ModeReq_Mode4" 4 "ModeReq_Mode5" 5 "ModeReq_Mode6";
VAL_ 120 CarpetLiSwtReq 0 "OnOff1_Off" 1 "OnOff1_On";
VAL_ 120 CarpetLiTiReq 0 "ModeReq_Mode1" 1 "ModeReq_Mode2" 2 "ModeReq_Mode3" 3 "ModeReq_Mode4" 4 "ModeReq_Mode5" 5 "ModeReq_Mode6";
VAL_ 120 LvlgSwtSetReqLvlgSwtSetReq 0 "LvlgSwtSetReq_Level0" 1 "LvlgSwtSetReq_Level1" 2 "LvlgSwtSetReq_Level2" 3 "LvlgSwtSetReq_Level3" 4 "LvlgSwtSetReq_Level4" 5 "LvlgSwtSetReq_Level5";
VAL_ 120 OutdBriSts 0 "OutdBriSts_Ukwn" 1 "OutdBriSts_Night" 2 "OutdBriSts_Day" 3 "OutdBriSts_Invld";
VAL_ 381 ActnOfLedFrntCrossLampDyn 0 "OnOff1_Off" 1 "OnOff1_On";
VAL_ 381 ActnOfLedGrilleLampDyn 0 "OnOff1_Off" 1 "OnOff1_On";
VAL_ 381 ActnOfLedLeLogoLampDyn 0 "OnOff1_Off" 1 "OnOff1_On";
VAL_ 381 ActnOfLedPosnLampDyn 0 "OnOff1_Off" 1 "OnOff1_On";
VAL_ 381 ActnOfLedRiLogoLampDyn 0 "OnOff1_Off" 1 "OnOff1_On";
VAL_ 381 ActvnOfHomeSafe 0 "OnOff1_Off" 1 "OnOff1_On";
VAL_ 381 ActvnOfReLogoLamp1 0 "OnOff1_Off" 1 "OnOff1_On";
VAL_ 612 ActvnOfApproach 0 "OnOff1_Off" 1 "OnOff1_On";
VAL_ 612 ActvnOfCarLoctr 0 "OnOff1_Off" 1 "OnOff1_On";
VAL_ 612 ActvnOfWaitMode 0 "OnOff1_Off" 1 "OnOff1_On";
VAL_ 612 BrkPedlValQf 0 "GenQf1_UndefindDataAccur" 1 "GenQf1_TmpUndefdData" 2 "GenQf1_DataAccurNotWithinSpcn" 3 "GenQf1_AccurData";
VAL_ 612 IndcrNoSeq 0 "OnOff1_Off" 1 "OnOff1_On";
VAL_ 612 LitArea 0 "NoYes1_No" 1 "NoYes1_Yes";
VAL_ 612 WipgInfoWipgSpdInfo 0 "WipgSpdInfo_Off" 1 "WipgSpdInfo_IntlLo" 2 "WipgSpdInfo_IntlHi" 3 "WipgSpdInfo_WipgSpd4045" 4 "WipgSpdInfo_WipgSpd4650" 5 "WipgSpdInfo_WipgSpd5155" 6 "WipgSpdInfo_WipgSpd5660" 7 "WipgSpdInfo_WiprErr";
VAL_ 612 WipgInfoWiprActv 0 "OnOff1_Off" 1 "OnOff1_On";
VAL_ 612 WipgInfoWiprInWipgAr 0 "OnOff1_Off" 1 "OnOff1_On";
VAL_ 522 ActnOfLedCornrgLampLe 0 "OnOff1_Off" 1 "OnOff1_On";
VAL_ 522 ActnOfLedCornrgLampRi 0 "OnOff1_Off" 1 "OnOff1_On";
VAL_ 522 ActnOfLedDaytiRunngLamp 0 "OnOff1_Off" 1 "OnOff1_On";
VAL_ 522 ActnOfLedFrntFogLamp 0 "OnOff1_Off" 1 "OnOff1_On";
VAL_ 522 ActnOfLedHiBeam 0 "OnOff1_Off" 1 "OnOff1_On";
VAL_ 522 ActnOfLedLoBeamActnOfLedLoBeam 0 "OnOff1_Off" 1 "OnOff1_On";
VAL_ 522 ActnOfLedPosnLamp 0 "OnOff1_Off" 1 "OnOff1_On";
VAL_ 522 ActnOfLedReFogLamp 0 "OnOff1_Off" 1 "OnOff1_On";
VAL_ 522 ActnOfLedRePosnLamp 0 "OnOff1_Off" 1 "OnOff1_On";
VAL_ 522 ActnOfLedRvsgLamp 0 "OnOff1_Off" 1 "OnOff1_On";
VAL_ 522 ActnOfLedStopLampActnOfLedStopLamp 0 "OnOff1_Off" 1 "OnOff1_On";
VAL_ 522 ActvnOfAfs 0 "OnOff1_Off" 1 "OnOff1_On";
VAL_ 522 ActvnOfAhbc 0 "OnOff1_Off" 1 "OnOff1_On";
VAL_ 522 ActvnOfAhl 0 "OnOff1_Off" 1 "OnOff1_On";
VAL_ 522 ActvnOfBrkLi 0 "OnOff1_Off" 1 "OnOff1_On";
VAL_ 522 ActvnOfDbl 0 "OnOff1_Off" 1 "OnOff1_On";
VAL_ 522 ActvnOfGoodByeLi 0 "OnOff1_Off" 1 "OnOff1_On";
VAL_ 522 ActvnOfTouristMod 0 "OnOff1_Off" 1 "OnOff1_On";
VAL_ 522 ActvnOfWelcomeLi 0 "OnOff1_Off" 1 "OnOff1_On";
VAL_ 538 ActvnOfIndcrIndcrOut 0 "IndcrSts1_Off" 1 "IndcrSts1_LeOn" 2 "IndcrSts1_RiOn" 3 "IndcrSts1_LeAndRiOn";
VAL_ 538 EmgyBrkLiIndcrTurn 0 "OnOffCrit1_NotVld1" 1 "OnOffCrit1_Off" 2 "OnOffCrit1_On" 3 "OnOffCrit1_NotVld2";
VAL_ 538 IndcrSts 0 "IndcrSts1_Off" 1 "IndcrSts1_LeOn" 2 "IndcrSts1_RiOn" 3 "IndcrSts1_LeAndRiOn";
VAL_ 24 DoorDrvrSts 0 "DoorSts2_Ukwn" 1 "DoorSts2_Opend" 2 "DoorSts2_Clsd";
VAL_ 24 DoorLeReSts 0 "DoorSts2_Ukwn" 1 "DoorSts2_Opend" 2 "DoorSts2_Clsd";
VAL_ 24 WelcomeGoodbyeModeReq 0 "ModeReq_Mode1" 1 "ModeReq_Mode2" 2 "ModeReq_Mode3" 3 "ModeReq_Mode4" 4 "ModeReq_Mode5" 5 "ModeReq_Mode6";
VAL_ 801 DwnLoadDynLtgPrmForFrntLeGrp1Mode1 0 "Mode4_Off" 1 "Mode4_On" 2 "Mode4_GradualOn" 3 "Mode4_GradualOff" 4 "Mode4_ForwardWipingOn" 5 "Mode4_BackwardWipingOn" 6 "Mode4_OutwardWipingOn" 7 "Mode4_InwardWipingOn" 8 "Mode4_ForwardWipingOff" 9 "Mode4_BackwardWipingOff" 10 "Mode4_OutwardWipingOff" 11 "Mode4_InwardWipingOff" 12 "Mode4_ForwardScanning" 13 "Mode4_BackwardScanning" 14 "Mode4_BreathOn" 15 "Mode4_BreathOff" 16 "Mode4_1stHalfONand2ndHalfOFF" 17 "Mode4_HalfOFFHalfON" 18 "Mode4_HalfDimmingONHalfOFF" 19 "Mode4_HalfDimmingONHalfON" 20 "Mode4_HalfOFFHalfDimmingON" 21 "Mode4_HalfONHalfDimmingON" 22 "Mode4_HalfDimmingOFFHalfOFF" 23 "Mode4_HalfDimmingOFFHalfON" 24 "Mode4_HalfOFFHalfDimmingOFF" 25 "Mode4_HalfONHalfDimmingOFF" 26 "Mode4_SingleOn1" 27 "Mode4_SingleOn2" 28 "Mode4_SingleOn3" 29 "Mode4_SingleOn4" 30 "Mode4_SingleOn5" 31 "Mode4_SingleOn6" 32 "Mode4_SingleOn7" 33 "Mode4_SingleOn8" 34 "Mode4_SingleOn9" 35 "Mode4_SingleOn10" 36 "Mode4_SingleOn11" 37 "Mode4_SingleOn12" 38 "Mode4_SingleOff1" 39 "Mode4_SingleOff2" 40 "Mode4_SingleOff3" 41 "Mode4_SingleOff4" 42 "Mode4_SingleOff5" 43 "Mode4_SingleOff6" 44 "Mode4_SingleOff7" 45 "Mode4_SingleOff8" 46 "Mode4_SingleOff9" 47 "Mode4_SingleOff10" 48 "Mode4_SingleOff11" 49 "Mode4_SingleOff12";
SIG_GROUP_ 128 AccrPedlRat 1 : AccrPedlRatAccrPedlRat AccrPedlRatChks AccrPedlRatCntr;
SIG_GROUP_ 522 ActnOfLedLoBeam 1 : ActnOfLedLoBeamActnOfLedLoBeam ActnOfLedLoBeamChks ActnOfLedLoBeamCntr;
SIG_GROUP_ 522 ActnOfLedStopLamp 1 : ActnOfLedStopLampActnOfLedStopLamp ActnOfLedStopLampChks ActnOfLedStopLampCntr;
SIG_GROUP_ 538 ActvnOfIndcr 1 : ActvnOfIndcrIndcrOut ActvnOfIndcrIndcrOutChks ActvnOfIndcrIndcrOutCntr;
SIG_GROUP_ 128 AmbTRaw 1 : AmbTRawAmbTVal AmbTRawQly;
SIG_GROUP_ 768 BrkPedlrRat 1 : BrkPedlrRatPerc BrkPedlrRatQf;
SIG_GROUP_ 128 BrkPedlSnsr 1 : BrkPedlSnsrChks BrkPedlSnsrCntr BrkPedlSnsrQf BrkPedlSnsrSt;
SIG_GROUP_ 612 BrkPedlVal 1 : BrkPedlValBrkPedlVal BrkPedlValQf;
SIG_GROUP_ 801 DwnLoadDynLtgPrmForFrntLeGrp1 1 : DwnLoadDynLtgPrmForFrntLeGrp1ContinueTime DwnLoadDynLtgPrmForFrntLeGrp1HighBrightness DwnLoadDynLtgPrmForFrntLeGrp1LowBrightness DwnLoadDynLtgPrmForFrntLeGrp1Mode1 DwnLoadDynLtgPrmForFrntLeGrp1OffsetTime DwnLoadDynLtgPrmForFrntLeGrp1Timestamp;
SIG_GROUP_ 834 DwnLoadDynLtgPrmForFrntRIGrp10 1 : DwnLoadDynLtgPrmForFrntRIGrp10ContinueTime DwnLoadDynLtgPrmForFrntRIGrp10HighBrightness DwnLoadDynLtgPrmForFrntRIGrp10LowBrightness DwnLoadDynLtgPrmForFrntRIGrp10Mode1 DwnLoadDynLtgPrmForFrntRIGrp10OffsetTime DwnLoadDynLtgPrmForFrntRIGrp10Timestamp;
SIG_GROUP_ 835 DwnLoadDynLtgPrmForFrntRIGrp11 1 : DwnLoadDynLtgPrmForFrntRIGrp11ContinueTime DwnLoadDynLtgPrmForFrntRIGrp11HighBrightness DwnLoadDynLtgPrmForFrntRIGrp11LowBrightness DwnLoadDynLtgPrmForFrntRIGrp11Mode1 DwnLoadDynLtgPrmForFrntRIGrp11OffsetTime DwnLoadDynLtgPrmForFrntRIGrp11Timestamp;
SIG_GROUP_ 836 DwnLoadDynLtgPrmForFrntRIGrp12 1 : DwnLoadDynLtgPrmForFrntRIGrp12ContinueTime DwnLoadDynLtgPrmForFrntRIGrp12HighBrightness DwnLoadDynLtgPrmForFrntRIGrp12LowBrightness DwnLoadDynLtgPrmForFrntRIGrp12Mode1 DwnLoadDynLtgPrmForFrntRIGrp12OffsetTime DwnLoadDynLtgPrmForFrntRIGrp12Timestamp;
SIG_GROUP_ 837 DwnLoadDynLtgPrmForFrntRIGrp13 1 : DwnLoadDynLtgPrmForFrntRIGrp13ContinueTime DwnLoadDynLtgPrmForFrntRIGrp13HighBrightness DwnLoadDynLtgPrmForFrntRIGrp13LowBrightness DwnLoadDynLtgPrmForFrntRIGrp13Mode1 DwnLoadDynLtgPrmForFrntRIGrp13OffsetTime DwnLoadDynLtgPrmForFrntRIGrp13Timestamp;
SIG_GROUP_ 838 DwnLoadDynLtgPrmForFrntRIGrp14 1 : DwnLoadDynLtgPrmForFrntRIGrp14ContinueTime DwnLoadDynLtgPrmForFrntRIGrp14HighBrightness DwnLoadDynLtgPrmForFrntRIGrp14LowBrightness DwnLoadDynLtgPrmForFrntRIGrp14Mode1 DwnLoadDynLtgPrmForFrntRIGrp14OffsetTime DwnLoadDynLtgPrmForFrntRIGrp14Timestamp;
SIG_GROUP_ 839 DwnLoadDynLtgPrmForFrntRIGrp15 1 : DwnLoadDynLtgPrmForFrntRIGrp15ContinueTime DwnLoadDynLtgPrmForFrntRIGrp15HighBrightness DwnLoadDynLtgPrmForFrntRIGrp15LowBrightness DwnLoadDynLtgPrmForFrntRIGrp15Mode1 DwnLoadDynLtgPrmForFrntRIGrp15OffsetTime DwnLoadDynLtgPrmForFrntRIGrp15Timestamp;
SIG_GROUP_ 840 DwnLoadDynLtgPrmForFrntRIGrp16 1 : DwnLoadDynLtgPrmForFrntRIGrp16ContinueTime DwnLoadDynLtgPrmForFrntRIGrp16HighBrightness DwnLoadDynLtgPrmForFrntRIGrp16LowBrightness DwnLoadDynLtgPrmForFrntRIGrp16Mode1 DwnLoadDynLtgPrmForFrntRIGrp16OffsetTime DwnLoadDynLtgPrmForFrntRIGrp16Timestamp;
SIG_GROUP_ 841 DwnLoadDynLtgPrmForFrntRIGrp17 1 : DwnLoadDynLtgPrmForFrntRIGrp17ContinueTime DwnLoadDynLtgPrmForFrntRIGrp17HighBrightness DwnLoadDynLtgPrmForFrntRIGrp17LowBrightness DwnLoadDynLtgPrmForFrntRIGrp17Mode1 DwnLoadDynLtgPrmForFrntRIGrp17OffsetTime DwnLoadDynLtgPrmForFrntRIGrp17Timestamp;
SIG_GROUP_ 842 DwnLoadDynLtgPrmForFrntRIGrp18 1 : DwnLoadDynLtgPrmForFrntRIGrp18ContinueTime DwnLoadDynLtgPrmForFrntRIGrp18HighBrightness DwnLoadDynLtgPrmForFrntRIGrp18LowBrightness DwnLoadDynLtgPrmForFrntRIGrp18Mode1 DwnLoadDynLtgPrmForFrntRIGrp18OffsetTime DwnLoadDynLtgPrmForFrntRIGrp18Timestamp;
SIG_GROUP_ 843 DwnLoadDynLtgPrmForFrntRIGrp19 1 : DwnLoadDynLtgPrmForFrntRIGrp19ContinueTime DwnLoadDynLtgPrmForFrntRIGrp19HighBrightness DwnLoadDynLtgPrmForFrntRIGrp19LowBrightness DwnLoadDynLtgPrmForFrntRIGrp19Mode1 DwnLoadDynLtgPrmForFrntRIGrp19OffsetTime DwnLoadDynLtgPrmForFrntRIGrp19Timestamp;
SIG_GROUP_ 844 DwnLoadDynLtgPrmForFrntRIGrp20 1 : DwnLoadDynLtgPrmForFrntRIGrp20ContinueTime DwnLoadDynLtgPrmForFrntRIGrp20HighBrightness DwnLoadDynLtgPrmForFrntRIGrp20LowBrightness DwnLoadDynLtgPrmForFrntRIGrp20Mode1 DwnLoadDynLtgPrmForFrntRIGrp20OffsetTime DwnLoadDynLtgPrmForFrntRIGrp20Timestamp;
SIG_GROUP_ 845 DwnLoadDynLtgPrmForFrntRIGrp21 1 : DwnLoadDynLtgPrmForFrntRIGrp21ContinueTime DwnLoadDynLtgPrmForFrntRIGrp21HighBrightness DwnLoadDynLtgPrmForFrntRIGrp21LowBrightness DwnLoadDynLtgPrmForFrntRIGrp21Mode1 DwnLoadDynLtgPrmForFrntRIGrp21OffsetTime DwnLoadDynLtgPrmForFrntRIGrp21Timestamp;
SIG_GROUP_ 846 DwnLoadDynLtgPrmForFrntRIGrp22 1 : DwnLoadDynLtgPrmForFrntRIGrp22ContinueTime DwnLoadDynLtgPrmForFrntRIGrp22HighBrightness DwnLoadDynLtgPrmForFrntRIGrp22LowBrightness DwnLoadDynLtgPrmForFrntRIGrp22Mode1 DwnLoadDynLtgPrmForFrntRIGrp22OffsetTime DwnLoadDynLtgPrmForFrntRIGrp22Timestamp;
SIG_GROUP_ 847 DwnLoadDynLtgPrmForFrntRIGrp23 1 : DwnLoadDynLtgPrmForFrntRIGrp23ContinueTime DwnLoadDynLtgPrmForFrntRIGrp23HighBrightness DwnLoadDynLtgPrmForFrntRIGrp23LowBrightness DwnLoadDynLtgPrmForFrntRIGrp23Mode1 DwnLoadDynLtgPrmForFrntRIGrp23OffsetTime DwnLoadDynLtgPrmForFrntRIGrp23Timestamp;
SIG_GROUP_ 848 DwnLoadDynLtgPrmForFrntRIGrp24 1 : DwnLoadDynLtgPrmForFrntRIGrp24ContinueTime DwnLoadDynLtgPrmForFrntRIGrp24HighBrightness DwnLoadDynLtgPrmForFrntRIGrp24LowBrightness DwnLoadDynLtgPrmForFrntRIGrp24Mode1 DwnLoadDynLtgPrmForFrntRIGrp24OffsetTime DwnLoadDynLtgPrmForFrntRIGrp24Timestamp;
SIG_GROUP_ 538 IndcrPat 1 : IndcrPatCmd1WdTiOff IndcrPatCmd1WdTiOn;
SIG_GROUP_ 784 LockgCenSts 1 : LockgCenStsLockSt LockgCenStsTrigSrc LockgCenStsUpdEve;
SIG_GROUP_ 120 LvlgSwtSetReq 1 : LvlgSwtSetReqChks LvlgSwtSetReqCntr LvlgSwtSetReqLvlgSwtSetReq;
SIG_GROUP_ 120 OutdBri 1 : OutdBriChks OutdBriCntr OutdBriSts;
SIG_GROUP_ 82 SteerWhlSnsr 1 : SteerWhlSnsrAg SteerWhlSnsrAgSpd SteerWhlSnsrChks SteerWhlSnsrCntr SteerWhlSnsrQf;
SIG_GROUP_ 400 SuspPosnVertAg 1 : SuspPosnVertAgGenQf SuspPosnVertAgSuspPosnVertAg;
SIG_GROUP_ 400 SuspPosnVertLvl 1 : SuspPosnVertLvlFrnt SuspPosnVertLvlFrntQf SuspPosnVertLvlRe SuspPosnVertLvlReQf;
SIG_GROUP_ 1152 TiAndDateIndcn 1 : TiAndDateIndcnDataValid TiAndDateIndcnDay TiAndDateIndcnHr1 TiAndDateIndcnMins1 TiAndDateIndcnMth1 TiAndDateIndcnSec1 TiAndDateIndcnYr1;
SIG_GROUP_ 389 TrafficSignForADB1 1 : TrafficSignForADB1AdbAbsDist TrafficSignForADB1AdbDetdQly TrafficSignForADB1AdbHozlAgLe TrafficSignForADB1AdbHozlAgRi TrafficSignForADB1AdbTrkInfo TrafficSignForADB1AdbVertAgBot TrafficSignForADB1AdbVertAgTop;
SIG_GROUP_ 390 TrafficSignForADB2 1 : TrafficSignForADB2AdbAbsDist TrafficSignForADB2AdbDetdQly TrafficSignForADB2AdbHozlAgLe TrafficSignForADB2AdbHozlAgRi TrafficSignForADB2AdbTrkInfo TrafficSignForADB2AdbVertAgBot TrafficSignForADB2AdbVertAgTop;
SIG_GROUP_ 512 VehBattU 1 : VehBattUSysU VehBattUSysUQf;
SIG_GROUP_ 384 VehCfgPrm 1 : VehCfgPrmBlkIDBytePosn1 VehCfgPrmCCPBytePosn2 VehCfgPrmCCPBytePosn3 VehCfgPrmCCPBytePosn4 VehCfgPrmCCPBytePosn5 VehCfgPrmCCPBytePosn6 VehCfgPrmCCPBytePosn7 VehCfgPrmCCPBytePosn8;
SIG_GROUP_ 387 VehCfgPrmExt 1 : VehCfgPrmExtBlkIDBytePosn1 VehCfgPrmExtCCPBytePosn2 VehCfgPrmExtCCPBytePosn3 VehCfgPrmExtCCPBytePosn4 VehCfgPrmExtCCPBytePosn5 VehCfgPrmExtCCPBytePosn6 VehCfgPrmExtCCPBytePosn7 VehCfgPrmExtCCPBytePosn8;
SIG_GROUP_ 64 VehModMngtGlbSafe1 1 : VehModMngtGlbSafe1CarModSts1 VehModMngtGlbSafe1CarModSubtypWdCarModSubtyp VehModMngtGlbSafe1Chks VehModMngtGlbSafe1Cntr VehModMngtGlbSafe1EgyLvlElecMai VehModMngtGlbSafe1EgyLvlElecSubtyp VehModMngtGlbSafe1FltEgyCnsWdSts VehModMngtGlbSafe1PwrLvlElecMai VehModMngtGlbSafe1PwrLvlElecSubtyp VehModMngtGlbSafe1UsgModSts;
SIG_GROUP_ 392 VehObjforADB1 1 : VehObjforADB1AdbAbsDist VehObjforADB1AdbClassn VehObjforADB1AdbHozlAgLe VehObjforADB1AdbHozlAgRi VehObjforADB1AdbObjDir VehObjforADB1AdbObjHozlAgSpdLe VehObjforADB1AdbObjHozlAgSpdRi VehObjforADB1AdbTrkInfo VehObjforADB1AdbVertAg;
SIG_GROUP_ 393 VehObjforADB2 1 : VehObjforADB2AdbAbsDist VehObjforADB2AdbClassn VehObjforADB2AdbHozlAgLe VehObjforADB2AdbHozlAgRi VehObjforADB2AdbObjDir VehObjforADB2AdbObjHozlAgSpdLe VehObjforADB2AdbObjHozlAgSpdRi VehObjforADB2AdbTrkInfo VehObjforADB2AdbVertAg;
SIG_GROUP_ 394 VehObjforADB3 1 : VehObjforADB3AdbAbsDist VehObjforADB3AdbClassn VehObjforADB3AdbHozlAgLe VehObjforADB3AdbHozlAgRi VehObjforADB3AdbObjDir VehObjforADB3AdbObjHozlAgSpdLe VehObjforADB3AdbObjHozlAgSpdRi VehObjforADB3AdbTrkInfo VehObjforADB3AdbVertAg;
SIG_GROUP_ 395 VehObjforADB4 1 : VehObjforADB4AdbAbsDist VehObjforADB4AdbClassn VehObjforADB4AdbHozlAgLe VehObjforADB4AdbHozlAgRi VehObjforADB4AdbObjDir VehObjforADB4AdbObjHozlAgSpdLe VehObjforADB4AdbObjHozlAgSpdRi VehObjforADB4AdbTrkInfo VehObjforADB4AdbVertAg;
SIG_GROUP_ 396 VehObjforADB5 1 : VehObjforADB5AdbAbsDist VehObjforADB5AdbClassn VehObjforADB5AdbHozlAgLe VehObjforADB5AdbHozlAgRi VehObjforADB5AdbObjDir VehObjforADB5AdbObjHozlAgSpdLe VehObjforADB5AdbObjHozlAgSpdRi VehObjforADB5AdbTrkInfo VehObjforADB5AdbVertAg;
SIG_GROUP_ 397 VehObjforADB6 1 : VehObjforADB6AdbAbsDist VehObjforADB6AdbClassn VehObjforADB6AdbHozlAgLe VehObjforADB6AdbHozlAgRi VehObjforADB6AdbObjDir VehObjforADB6AdbObjHozlAgSpdLe VehObjforADB6AdbObjHozlAgSpdRi VehObjforADB6AdbTrkInfo VehObjforADB6AdbVertAg;
SIG_GROUP_ 398 VehObjforADB7 1 : VehObjforADB7AdbAbsDist VehObjforADB7AdbClassn VehObjforADB7AdbHozlAgLe VehObjforADB7AdbHozlAgRi VehObjforADB7AdbObjDir VehObjforADB7AdbObjHozlAgSpdLe VehObjforADB7AdbObjHozlAgSpdRi VehObjforADB7AdbTrkInfo VehObjforADB7AdbVertAg;
SIG_GROUP_ 399 VehObjforADB8 1 : VehObjforADB8AdbAbsDist VehObjforADB8AdbClassn VehObjforADB8AdbHozlAgLe VehObjforADB8AdbHozlAgRi VehObjforADB8AdbObjDir VehObjforADB8AdbObjHozlAgSpdLe VehObjforADB8AdbObjHozlAgSpdRi VehObjforADB8AdbTrkInfo VehObjforADB8AdbVertAg;
SIG_GROUP_ 391 VehObjforAHB 1 : VehObjforAHBAdbAbsDist VehObjforAHBAdbClassn VehObjforAHBAdbClassnQly VehObjforAHBAdbDetdQly VehObjforAHBAdbHozlAg VehObjforAHBAdbObjDir VehObjforAHBAdbObjHozlAgSpd VehObjforAHBAdbObjVertAgSpd VehObjforAHBAdbTrkInfo VehObjforAHBAdbVertAg;
SIG_GROUP_ 80 VehSpdLgt 1 : VehSpdLgtA VehSpdLgtChks VehSpdLgtCntr VehSpdLgtQf;
SIG_GROUP_ 612 WipgInfo 1 : WipgInfoWipgSpdInfo WipgInfoWiprActv WipgInfoWiprInWipgAr;
